VERSION ""

NS_ :

BS_:

BU_: FCM

BO_ 969 RRCR_3: 24 Vector__XXX
 SG_ RRCR_3_Ri2ObjBoxLen : 7|9@0+ (0.1,0) [0|50] "m"  FCM
 SG_ RRCR_3_Ri2ObjBoxWidth : 14|9@0+ (0.1,0) [0|50] "m"  FCM
 SG_ RRCR_3_Ri2HdTo : 21|12@0+ (0.1,-180) [-180|180] "deg"  FCM
 SG_ RRCR_3_Ri2ObjID : 25|8@0+ (1,0) [0|255] ""  FCM
 SG_ RRCR_3_Ri2ObjCoordY : 33|13@0+ (0.05,-200) [-200|200] "m"  FCM
 SG_ RRCR_3_Ri2ObjCoordX : 52|13@0+ (0.05,-200) [-200|200] "m"  FCM
 SG_ RRCR_3_Ri2ObjXDirAV : 71|8@0+ (0.1,-12.8) [-12.8|12.7] "m/s2"  FCM
 SG_ RRCR_3_Ri2ObjYDirV : 79|14@0+ (0.02,-128) [-128|128] "m/s"  FCM
 SG_ RRCR_3_Ri2ObjXDirV : 81|14@0+ (0.02,-128) [-128|128] "m/s"  FCM
 SG_ RRCR_3_Ri2ObjMtnChartc : 99|2@0+ (1,0) [0|3] ""  FCM
 SG_ RRCR_3_Ri2ObjTyp : 97|2@0+ (1,0) [0|3] ""  FCM
 SG_ RRCR_3_Ri2ObjConf : 111|1@0+ (1,0) [0|1] ""  FCM
 SG_ RRCR_3_Ri2ObjNrOffocst : 110|5@0+ (1,0) [0|31] ""  FCM
 SG_ RRCR_3_Ri2ObjTrackSt : 105|2@0+ (1,0) [0|3] ""  FCM
 SG_ RRCR_3_Ri2ObjCoordXDstStdDe : 119|8@0+ (0.05,0) [0|12.7] ""  FCM
 SG_ RRCR_3_Ri2ObjCoordYDstStdDe : 127|8@0+ (0.05,0) [0|12.7] ""  FCM
 SG_ RRCR_3_Ri2ObjXDirVStdDe : 135|6@0+ (0.05,0) [0|2] ""  FCM
 SG_ RRCR_3_Ri2ObjYDirVStdDe : 129|6@0+ (0.05,0) [0|2] ""  FCM
 SG_ RRCR_3_MsgCntr : 179|4@0+ (1,0) [0|15] ""  FCM
 SG_ RRCR_3_CRC : 191|8@0+ (1,0) [0|255] ""  FCM

BO_ 976 RRCR_4: 24 Vector__XXX
 SG_ RRCR_4_Ri3ObjBoxLen : 7|9@0+ (0.1,0) [0|50] "m"  FCM
 SG_ RRCR_4_Ri3ObjBoxWidth : 14|9@0+ (0.1,0) [0|50] "m"  FCM
 SG_ RRCR_4_Ri3HdTo : 21|12@0+ (0.1,-180) [-180|180] "deg"  FCM
 SG_ RRCR_4_Ri3ObjID : 25|8@0+ (1,0) [0|255] ""  FCM
 SG_ RRCR_4_Ri3ObjCoordY : 33|13@0+ (0.05,-200) [-200|200] "m"  FCM
 SG_ RRCR_4_Ri3ObjCoordX : 52|13@0+ (0.05,-200) [-200|200] "m"  FCM
 SG_ RRCR_4_Ri3ObjXDirAV : 71|8@0+ (0.1,-12.8) [-12.8|12.7] "m/s2"  FCM
 SG_ RRCR_4_Ri3ObjYDirV : 79|14@0+ (0.02,-128) [-128|128] "m/s"  FCM
 SG_ RRCR_4_Ri3ObjXDirV : 81|14@0+ (0.02,-128) [-128|128] "m/s"  FCM
 SG_ RRCR_4_Ri3ObjMtnChartc : 99|2@0+ (1,0) [0|3] ""  FCM
 SG_ RRCR_4_Ri3ObjTyp : 97|2@0+ (1,0) [0|3] ""  FCM
 SG_ RRCR_4_Ri3ObjConf : 111|1@0+ (1,0) [0|1] ""  FCM
 SG_ RRCR_4_Ri3ObjNrOffocst : 110|5@0+ (1,0) [0|31] ""  FCM
 SG_ RRCR_4_Ri3ObjTrackSt : 105|2@0+ (1,0) [0|3] ""  FCM
 SG_ RRCR_4_Ri3ObjCoordXDstStdDe : 119|8@0+ (0.05,0) [0|12.7] ""  FCM
 SG_ RRCR_4_Ri3ObjCoordYDstStdDe : 127|8@0+ (0.05,0) [0|12.7] ""  FCM
 SG_ RRCR_4_Ri3ObjXDirVStdDe : 135|6@0+ (0.05,0) [0|2] ""  FCM
 SG_ RRCR_4_Ri3ObjYDirVStdDe : 129|6@0+ (0.05,0) [0|2] ""  FCM
 SG_ RRCR_4_MsgCntr : 179|4@0+ (1,0) [0|15] ""  FCM
 SG_ RRCR_4_CRC : 191|8@0+ (1,0) [0|255] ""  FCM

BO_ 984 RRCR_5: 24 Vector__XXX
 SG_ RRCR_5_Ri4ObjBoxLen : 7|9@0+ (0.1,0) [0|50] "m"  FCM
 SG_ RRCR_5_Ri4ObjBoxWidth : 14|9@0+ (0.1,0) [0|50] "m"  FCM
 SG_ RRCR_5_Ri4HdTo : 21|12@0+ (0.1,-180) [-180|180] "deg"  FCM
 SG_ RRCR_5_Ri4ObjID : 25|8@0+ (1,0) [0|255] ""  FCM
 SG_ RRCR_5_Ri4ObjCoordY : 33|13@0+ (0.05,-200) [-200|200] "m"  FCM
 SG_ RRCR_5_Ri4ObjCoordX : 52|13@0+ (0.05,-200) [-200|200] "m"  FCM
 SG_ RRCR_5_Ri4ObjXDirAV : 71|8@0+ (0.1,-12.8) [-12.8|12.7] "m/s2"  FCM
 SG_ RRCR_5_Ri4ObjYDirV : 79|14@0+ (0.02,-128) [-128|128] "m/s"  FCM
 SG_ RRCR_5_Ri4ObjXDirV : 81|14@0+ (0.02,-128) [-128|128] "m/s"  FCM
 SG_ RRCR_5_Ri4ObjMtnChartc : 99|2@0+ (1,0) [0|3] ""  FCM
 SG_ RRCR_5_Ri4ObjTyp : 97|2@0+ (1,0) [0|3] ""  FCM
 SG_ RRCR_5_Ri4ObjConf : 111|1@0+ (1,0) [0|1] ""  FCM
 SG_ RRCR_5_Ri4ObjNrOffocst : 110|5@0+ (1,0) [0|31] ""  FCM
 SG_ RRCR_5_Ri4ObjTrackSt : 105|2@0+ (1,0) [0|3] ""  FCM
 SG_ RRCR_5_Ri4ObjCoordXDstStdDe : 119|8@0+ (0.05,0) [0|12.7] ""  FCM
 SG_ RRCR_5_Ri4ObjCoordYDstStdDe : 127|8@0+ (0.05,0) [0|12.7] ""  FCM
 SG_ RRCR_5_Ri4ObjXDirVStdDe : 135|6@0+ (0.05,0) [0|2] ""  FCM
 SG_ RRCR_5_Ri4ObjYDirVStdDe : 129|6@0+ (0.05,0) [0|2] ""  FCM
 SG_ RRCR_5_MsgCntr : 179|4@0+ (1,0) [0|15] ""  FCM
 SG_ RRCR_5_CRC : 191|8@0+ (1,0) [0|255] ""  FCM

BO_ 986 RRCR_6: 24 Vector__XXX
 SG_ RRCR_6_Ri5ObjBoxLen : 7|9@0+ (0.1,0) [0|50] "m"  FCM
 SG_ RRCR_6_Ri5ObjBoxWidth : 14|9@0+ (0.1,0) [0|50] "m"  FCM
 SG_ RRCR_6_Ri5HdTo : 21|12@0+ (0.1,-180) [-180|180] "deg"  FCM
 SG_ RRCR_6_Ri5ObjID : 25|8@0+ (1,0) [0|255] ""  FCM
 SG_ RRCR_6_Ri5ObjCoordY : 33|13@0+ (0.05,-200) [-200|200] "m"  FCM
 SG_ RRCR_6_Ri5ObjCoordX : 52|13@0+ (0.05,-200) [-200|200] "m"  FCM
 SG_ RRCR_6_Ri5ObjXDirAV : 71|8@0+ (0.1,-12.8) [-12.8|12.7] "m/s2"  FCM
 SG_ RRCR_6_Ri5ObjYDirV : 79|14@0+ (0.02,-128) [-128|128] "m/s"  FCM
 SG_ RRCR_6_Ri5ObjXDirV : 81|14@0+ (0.02,-128) [-128|128] "m/s"  FCM
 SG_ RRCR_6_Ri5ObjMtnChartc : 99|2@0+ (1,0) [0|3] ""  FCM
 SG_ RRCR_6_Ri5ObjTyp : 97|2@0+ (1,0) [0|3] ""  FCM
 SG_ RRCR_6_Ri5ObjConf : 111|1@0+ (1,0) [0|1] ""  FCM
 SG_ RRCR_6_Ri5ObjNrOffocst : 110|5@0+ (1,0) [0|31] ""  FCM
 SG_ RRCR_6_Ri5ObjTrackSt : 105|2@0+ (1,0) [0|3] ""  FCM
 SG_ RRCR_6_Ri5ObjCoordXDstStdDe : 119|8@0+ (0.05,0) [0|12.7] ""  FCM
 SG_ RRCR_6_Ri5ObjCoordYDstStdDe : 127|8@0+ (0.05,0) [0|12.7] ""  FCM
 SG_ RRCR_6_Ri5ObjXDirVStdDe : 135|6@0+ (0.05,0) [0|2] ""  FCM
 SG_ RRCR_6_Ri5ObjYDirVStdDe : 129|6@0+ (0.05,0) [0|2] ""  FCM
 SG_ RRCR_6_MsgCntr : 179|4@0+ (1,0) [0|15] ""  FCM
 SG_ RRCR_6_CRC : 191|8@0+ (1,0) [0|255] ""  FCM

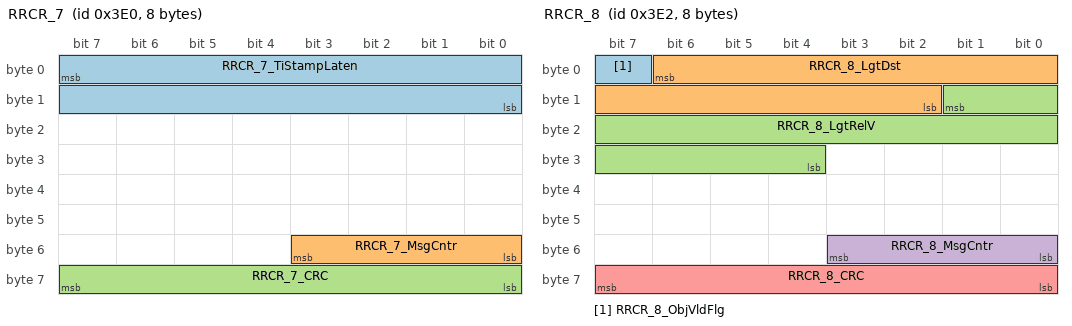
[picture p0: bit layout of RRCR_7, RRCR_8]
BO_ 992 RRCR_7: 8 Vector__XXX
 SG_ RRCR_7_TiStampLaten : 7|16@0+ (1,0) [0|65535] ""  FCM
 SG_ RRCR_7_MsgCntr : 51|4@0+ (1,0) [0|15] ""  FCM
 SG_ RRCR_7_CRC : 63|8@0+ (1,0) [0|255] ""  FCM

BO_ 994 RRCR_8: 8 Vector__XXX
 SG_ RRCR_8_ObjVldFlg : 7|1@0+ (1,0) [0|1] ""  FCM
 SG_ RRCR_8_LgtDst : 6|13@0+ (0.05,-200) [-200|200] "m"  FCM
 SG_ RRCR_8_LgtRelV : 9|14@0+ (0.02,-128) [-128|128] "m/s"  FCM
 SG_ RRCR_8_MsgCntr : 51|4@0+ (1,0) [0|15] ""  FCM
 SG_ RRCR_8_CRC : 63|8@0+ (1,0) [0|255] ""  FCM

BO_ 1785 XCP_FCM_RES: 8 FCM
 SG_ XCP_FCM_RES : 7|64@0+ (1,0) [0|1] ""  Vector__XXX

BO_ 1854 Diag_FCM_RES: 8 FCM
 SG_ Diag_FCM_RES : 7|64@0+ (1,0) [0|1] ""  Vector__XXX

BO_ 745 ABS_ESP_1: 8 Vector__XXX
 SG_ ABS_ESP_1_EBDFailSts : 1|1@0+ (1,0) [0|1] ""  FCM
 SG_ ABS_ESP_1_ABSFailSts : 5|1@0+ (1,0) [0|1] ""  FCM
 SG_ ABS_ESP_1_ABSActive : 6|1@0+ (1,0) [0|1] ""  FCM
 SG_ ABS_ESP_1_VDCFailSts : 11|1@0+ (1,0) [0|1] ""  FCM
 SG_ ABS_ESP_1_VDCActive : 12|1@0+ (1,0) [0|1] ""  FCM
 SG_ ABS_ESP_1_TCSFailSts : 13|1@0+ (1,0) [0|1] ""  FCM
 SG_ ABS_ESP_1_TCSActive : 14|1@0+ (1,0) [0|1] ""  FCM
 SG_ ABS_ESP_1_PressureMasterCylinder : 9|10@0+ (1,0) [0|1022] "Bar"  FCM
 SG_ ESP1_PressureMasCylindValidData : 29|1@0+ (1,0) [0|1] ""  FCM
 SG_ ESP1_VehicleSpeedVSOSigValidData : 30|1@0+ (1,0) [0|1] ""  FCM
 SG_ ABS_ESP_1_VehicleSpeedVSOSig : 28|13@0+ (0.0625,0) [0|511.875] "km/h"  FCM
 SG_ ABS_ESP_1_Checksum : 47|8@0+ (1,0) [0|255] ""  FCM
 SG_ ABS_ESP_1_HDCCtrlSts : 53|2@0+ (1,0) [0|3] ""  FCM
 SG_ ABS_ESP_1_HDCFailSts : 54|1@0+ (1,0) [0|1] ""  FCM
 SG_ ABS_ESP_1_MessageCounter : 59|4@0+ (1,0) [0|15] ""  FCM
 SG_ ABS_ESP_1_ESPSwitchStatus : 60|1@0+ (1,0) [0|1] ""  FCM
 SG_ SwitchOffCruiseControl : 63|1@0+ (1,0) [0|1] ""  FCM

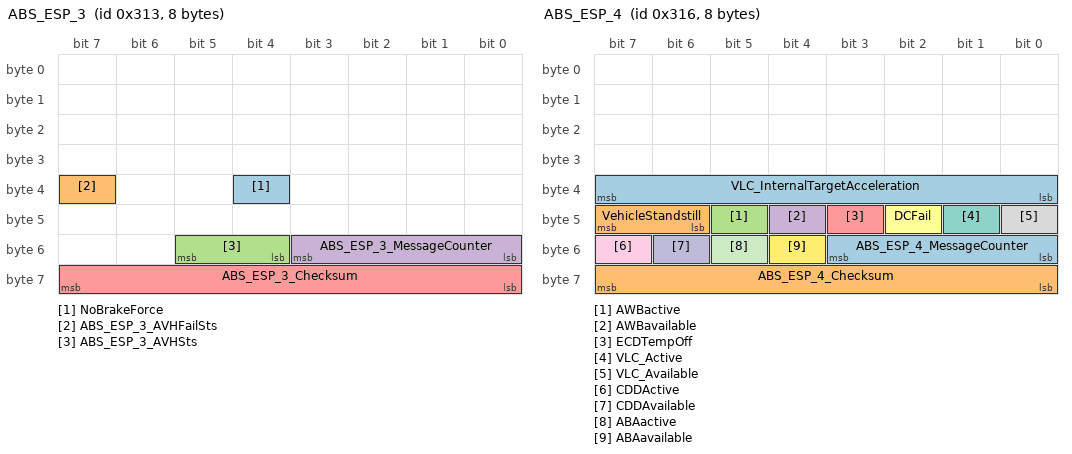
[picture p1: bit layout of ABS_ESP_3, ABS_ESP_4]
BO_ 787 ABS_ESP_3: 8 Vector__XXX
 SG_ NoBrakeForce : 36|1@0+ (1,0) [0|1] ""  FCM
 SG_ ABS_ESP_3_AVHFailSts : 39|1@0+ (1,0) [0|1] ""  FCM
 SG_ ABS_ESP_3_AVHSts : 53|2@0+ (1,0) [0|3] ""  FCM
 SG_ ABS_ESP_3_MessageCounter : 51|4@0+ (1,0) [0|15] ""  FCM
 SG_ ABS_ESP_3_Checksum : 63|8@0+ (1,0) [0|255] ""  FCM

BO_ 790 ABS_ESP_4: 8 Vector__XXX
 SG_ VLC_InternalTargetAcceleration : 39|8@0+ (0.05,-7) [-7|5.75] "m/s2"  FCM
 SG_ VehicleStandstill : 47|2@0+ (1,0) [0|3] ""  FCM
 SG_ AWBactive : 45|1@0+ (1,0) [0|1] ""  FCM
 SG_ AWBavailable : 44|1@0+ (1,0) [0|1] ""  FCM
 SG_ ECDTempOff : 43|1@0+ (1,0) [0|1] ""  FCM
 SG_ DCFail : 42|1@0+ (1,0) [0|1] ""  FCM
 SG_ VLC_Active : 41|1@0+ (1,0) [0|1] ""  FCM
 SG_ VLC_Available : 40|1@0+ (1,0) [0|1] ""  FCM
 SG_ CDDActive : 55|1@0+ (1,0) [0|1] ""  FCM
 SG_ CDDAvailable : 54|1@0+ (1,0) [0|1] ""  FCM
 SG_ ABAactive : 53|1@0+ (1,0) [0|1] ""  FCM
 SG_ ABAavailable : 52|1@0+ (1,0) [0|1] ""  FCM
 SG_ ABS_ESP_4_MessageCounter : 51|4@0+ (1,0) [0|15] ""  FCM
 SG_ ABS_ESP_4_Checksum : 63|8@0+ (1,0) [0|255] ""  FCM

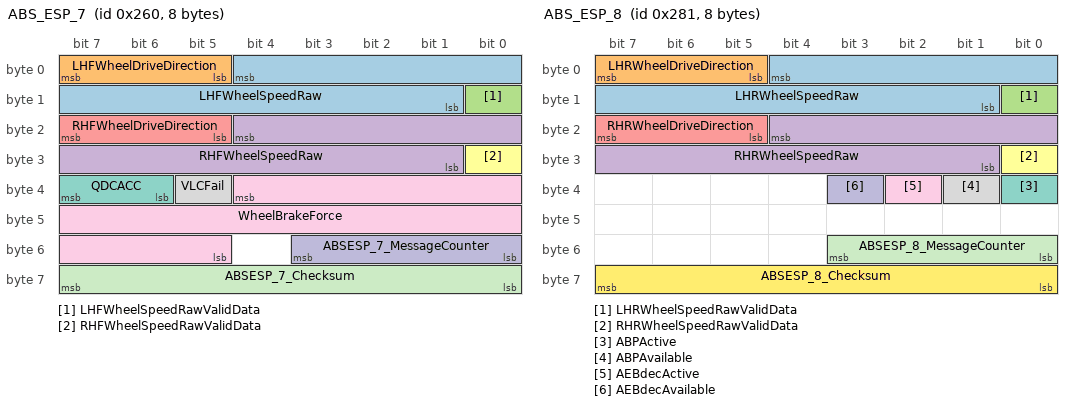
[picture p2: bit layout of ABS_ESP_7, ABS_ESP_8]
BO_ 608 ABS_ESP_7: 8 Vector__XXX
 SG_ LHFWheelSpeedRaw : 4|12@0+ (0.05,-30) [-30|80] "m/s"  FCM
 SG_ LHFWheelDriveDirection : 7|3@0+ (1,0) [0|7] ""  FCM
 SG_ LHFWheelSpeedRawValidData : 8|1@0+ (1,0) [0|1] ""  FCM
 SG_ RHFWheelSpeedRaw : 20|12@0+ (0.05,-30) [-30|80] "m/s"  FCM
 SG_ RHFWheelDriveDirection : 23|3@0+ (1,0) [0|7] ""  FCM
 SG_ RHFWheelSpeedRawValidData : 24|1@0+ (1,0) [0|1] ""  FCM
 SG_ QDCACC : 39|2@0+ (1,0) [0|3] ""  FCM
 SG_ VLCFail : 37|1@0+ (1,0) [0|1] ""  FCM
 SG_ WheelBrakeForce : 36|16@0+ (8,-250000) [-250000|250000] "N"  FCM
 SG_ ABSESP_7_MessageCounter : 51|4@0+ (1,0) [0|15] ""  FCM
 SG_ ABSESP_7_Checksum : 63|8@0+ (1,0) [0|255] ""  FCM

BO_ 641 ABS_ESP_8: 8 Vector__XXX
 SG_ LHRWheelSpeedRaw : 4|12@0+ (0.05,-30) [-30|80] "m/s"  FCM
 SG_ LHRWheelDriveDirection : 7|3@0+ (1,0) [0|7] ""  FCM
 SG_ LHRWheelSpeedRawValidData : 8|1@0+ (1,0) [0|1] ""  FCM
 SG_ RHRWheelSpeedRaw : 20|12@0+ (0.05,-30) [-30|80] "m/s"  FCM
 SG_ RHRWheelDriveDirection : 23|3@0+ (1,0) [0|7] ""  FCM
 SG_ RHRWheelSpeedRawValidData : 24|1@0+ (1,0) [0|1] ""  FCM
 SG_ ABPActive : 32|1@0+ (1,0) [0|1] ""  FCM
 SG_ ABPAvailable : 33|1@0+ (1,0) [0|1] ""  FCM
 SG_ AEBdecActive : 34|1@0+ (1,0) [0|1] ""  FCM
 SG_ AEBdecAvailable : 35|1@0+ (1,0) [0|1] ""  FCM
 SG_ ABSESP_8_MessageCounter : 51|4@0+ (1,0) [0|15] ""  FCM
 SG_ ABSESP_8_Checksum : 63|8@0+ (1,0) [0|255] ""  FCM

BO_ 1282 ABS_ESP_G: 7 Vector__XXX
 SG_ CDPActive : 13|1@0+ (1,0) [0|1] ""  FCM

BO_ 913 BCM_1: 8 Vector__XXX
 SG_ RHTurnlightSts : 0|1@0+ (1,0) [0|1] ""  FCM
 SG_ LHTurnlightSts : 1|1@0+ (1,0) [0|1] ""  FCM
 SG_ HighBeamSts : 2|1@0+ (1,0) [0|1] ""  FCM
 SG_ LowBeamSts : 3|1@0+ (1,0) [0|1] ""  FCM
 SG_ KeySts : 6|2@0+ (1,0) [0|3] ""  FCM
 SG_ BCM_1_Checksum : 15|8@0+ (1,0) [0|255] ""  FCM
 SG_ DirectionIndRight : 16|1@0+ (1,0) [0|1] ""  FCM
 SG_ DirectionIndLeft : 17|1@0+ (1,0) [0|1] ""  FCM
 SG_ HazardLightSW : 18|1@0+ (1,0) [0|1] ""  FCM
 SG_ AutoLightSW : 19|1@0+ (1,0) [0|1] ""  FCM
 SG_ FGHeat_Request_CommandFeedback : 22|1@0+ (1,0) [0|1] ""  FCM
 SG_ DriverDoorLockSts : 23|1@0+ (1,0) [0|1] ""  FCM
 SG_ DriverDoorSts : 24|1@0+ (1,0) [0|1] ""  FCM
 SG_ PsngrDoorSts : 25|1@0+ (1,0) [0|1] ""  FCM
 SG_ HoodSts : 26|1@0+ (1,0) [0|1] ""  FCM
 SG_ RHRDoorSts : 28|1@0+ (1,0) [0|1] ""  FCM
 SG_ LHRdoorSts : 29|1@0+ (1,0) [0|1] ""  FCM
 SG_ TrunkSts : 30|1@0+ (1,0) [0|1] ""  FCM
 SG_ DriverDoorStsQbit : 31|1@0+ (1,0) [0|1] ""  FCM
 SG_ HMASW : 32|1@0+ (1,0) [0|1] ""  FCM
 SG_ RearFogLightSts : 34|1@0+ (1,0) [0|1] ""  FCM
 SG_ ReverseGearSts : 35|1@0+ (1,0) [0|1] ""  FCM
 SG_ FrontFogLightSts : 37|1@0+ (1,0) [0|1] ""  FCM
 SG_ HighBeamSWSts : 38|1@0+ (1,0) [0|1] ""  FCM
 SG_ FlashSWSts : 39|1@0+ (1,0) [0|1] ""  FCM
 SG_ LHTurnSW : 44|1@0+ (1,0) [0|1] ""  FCM
 SG_ RHTurnSW : 45|1@0+ (1,0) [0|1] ""  FCM
 SG_ WiperSts : 47|2@0+ (1,0) [0|3] ""  FCM
 SG_ RainDetected : 53|1@0+ (1,0) [0|1] ""  FCM
 SG_ AutoHighSpeedRequest : 52|1@0+ (1,0) [0|1] ""  FCM
 SG_ BCM_1_MessageCounter : 51|4@0+ (1,0) [0|15] ""  FCM

BO_ 1077 BCM_9: 8 Vector__XXX
 SG_ TrailerConnectSts : 48|1@0+ (1,0) [0|1] ""  FCM

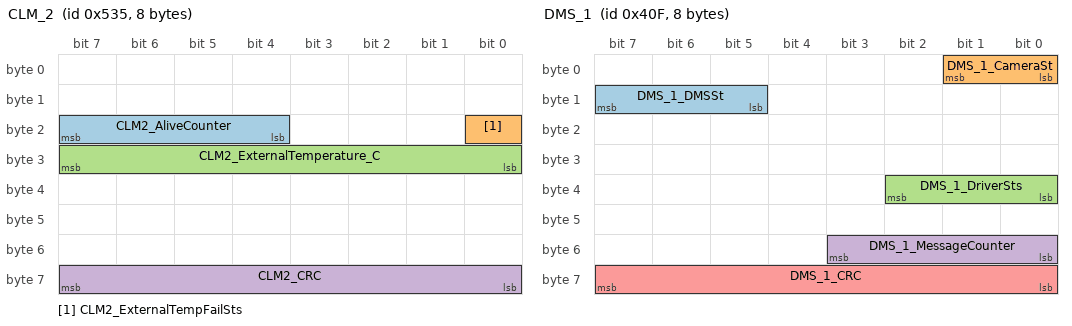
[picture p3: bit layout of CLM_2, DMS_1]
BO_ 1333 CLM_2: 8 Vector__XXX
 SG_ CLM2_AliveCounter : 23|4@0+ (1,0) [0|15] ""  FCM
 SG_ CLM2_ExternalTempFailSts : 16|1@0+ (1,0) [0|1] ""  FCM
 SG_ CLM2_ExternalTemperature_C : 31|8@0+ (0.5,-55) [-55|70] "°C"  FCM
 SG_ CLM2_CRC : 63|8@0+ (1,0) [0|255] ""  FCM

BO_ 1039 DMS_1: 8 Vector__XXX
 SG_ DMS_1_DMSSt : 15|3@0+ (1,0) [0|7] ""  FCM
 SG_ DMS_1_CameraSt : 1|2@0+ (1,0) [0|3] ""  FCM
 SG_ DMS_1_DriverSts : 34|3@0+ (1,0) [0|5] ""  FCM
 SG_ DMS_1_MessageCounter : 51|4@0+ (1,0) [0|15] ""  FCM
 SG_ DMS_1_CRC : 63|8@0+ (1,0) [0|255] ""  FCM

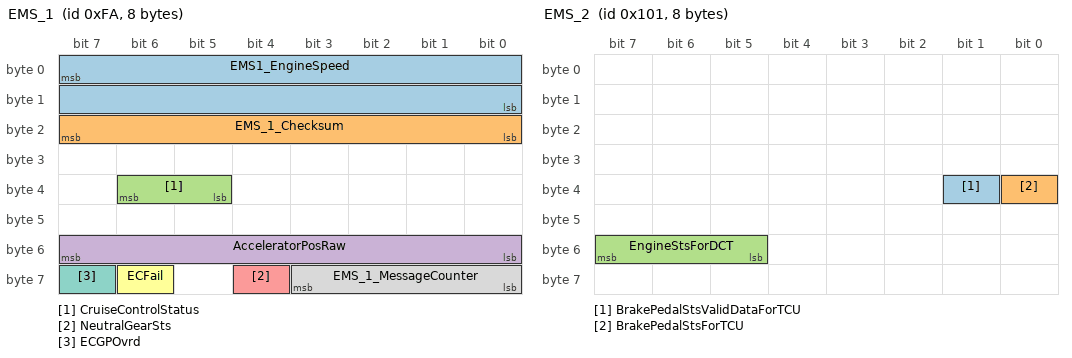
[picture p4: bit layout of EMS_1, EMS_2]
BO_ 250 EMS_1: 8 Vector__XXX
 SG_ EMS1_EngineSpeed : 7|16@0+ (0.25,0) [0|16383] "rpm"  FCM
 SG_ EMS_1_Checksum : 23|8@0+ (1,0) [0|255] ""  FCM
 SG_ CruiseControlStatus : 38|2@0+ (1,0) [0|3] ""  FCM
 SG_ AcceleratorPosRaw : 55|8@0+ (0.392,0) [0|99.568] "%"  FCM
 SG_ NeutralGearSts : 60|1@0+ (1,0) [0|1] ""  FCM
 SG_ ECFail : 62|1@0+ (1,0) [0|1] ""  FCM
 SG_ ECGPOvrd : 63|1@0+ (1,0) [0|1] ""  FCM
 SG_ EMS_1_MessageCounter : 59|4@0+ (1,0) [0|15] ""  FCM

BO_ 257 EMS_2: 8 Vector__XXX
 SG_ BrakePedalStsValidDataForTCU : 33|1@0+ (1,0) [0|1] ""  FCM
 SG_ BrakePedalStsForTCU : 32|1@0+ (1,0) [0|1] ""  FCM
 SG_ EngineStsForDCT : 55|3@0+ (1,0) [0|7] ""  FCM

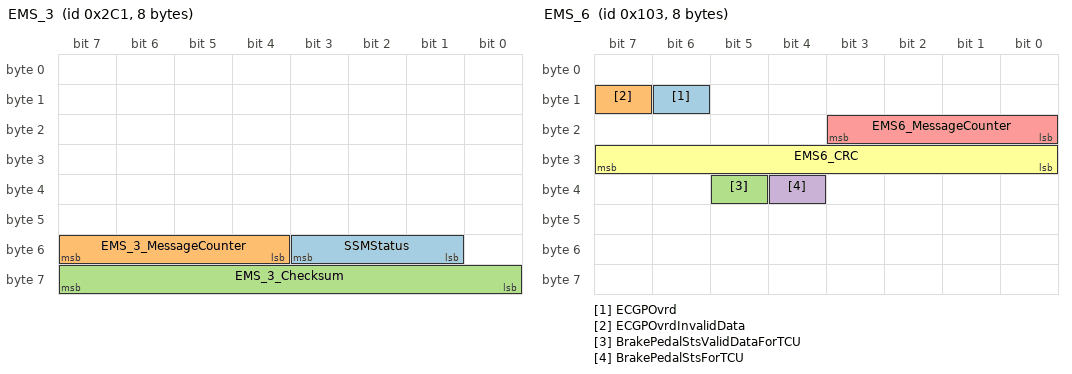
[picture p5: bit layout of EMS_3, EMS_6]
BO_ 705 EMS_3: 8 Vector__XXX
 SG_ SSMStatus : 51|3@0+ (1,0) [0|7] ""  FCM
 SG_ EMS_3_MessageCounter : 55|4@0+ (1,0) [0|15] ""  FCM
 SG_ EMS_3_Checksum : 63|8@0+ (1,0) [0|255] ""  FCM

BO_ 259 EMS_6: 8 Vector__XXX
 SG_ ECGPOvrd : 14|1@0+ (1,0) [0|1] ""  FCM
 SG_ ECGPOvrdInvalidData : 15|1@0+ (1,0) [0|1] ""  FCM
 SG_ BrakePedalStsValidDataForTCU : 37|1@0+ (1,0) [0|1] ""  FCM
 SG_ BrakePedalStsForTCU : 36|1@0+ (1,0) [0|1] ""  FCM
 SG_ EMS6_MessageCounter : 19|4@0+ (1,0) [0|15] ""  FCM
 SG_ EMS6_CRC : 31|8@0+ (1,0) [0|255] ""  FCM

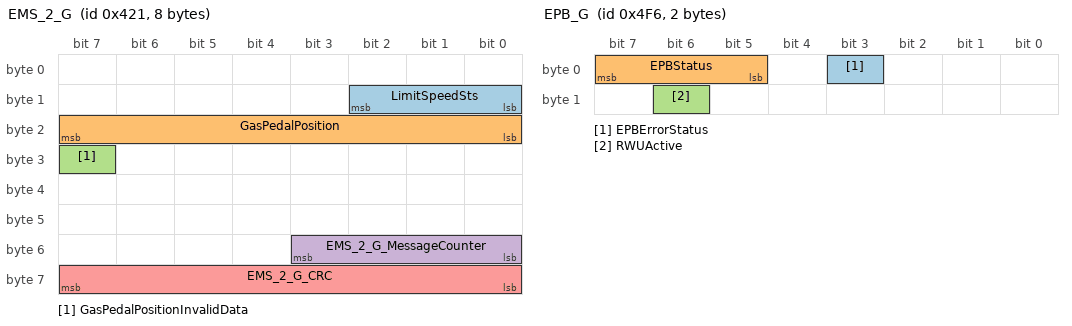
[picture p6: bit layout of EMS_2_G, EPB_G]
BO_ 1057 EMS_2_G: 8 Vector__XXX
 SG_ LimitSpeedSts : 10|3@0+ (1,0) [0|7] ""  FCM
 SG_ GasPedalPosition : 23|8@0+ (0.392,0) [0|99.568] "%"  FCM
 SG_ GasPedalPositionInvalidData : 31|1@0+ (1,0) [0|1] ""  FCM
 SG_ EMS_2_G_MessageCounter : 51|4@0+ (1,0) [0|15] ""  FCM
 SG_ EMS_2_G_CRC : 63|8@0+ (1,0) [0|255] ""  FCM

BO_ 1270 EPB_G: 2 Vector__XXX
 SG_ EPBErrorStatus : 3|1@0+ (1,0) [0|1] ""  FCM
 SG_ EPBStatus : 7|3@0+ (1,0) [0|7] ""  FCM
 SG_ RWUActive : 14|1@0+ (1,0) [0|1] ""  FCM

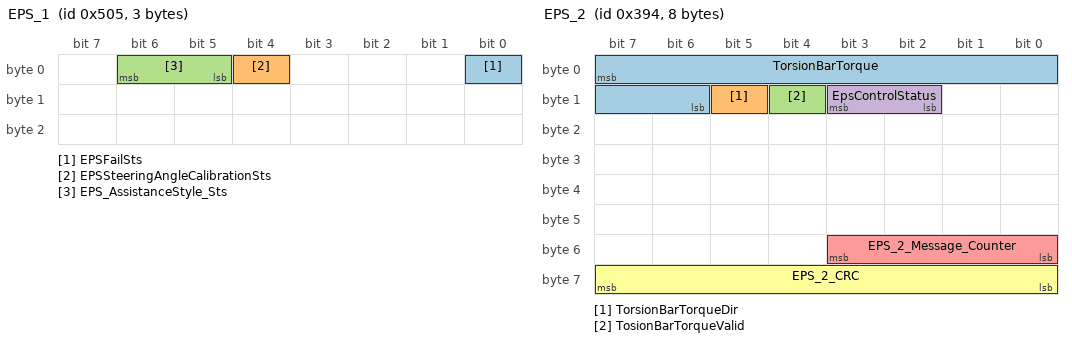
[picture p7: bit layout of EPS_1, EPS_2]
BO_ 1285 EPS_1: 3 Vector__XXX
 SG_ EPSFailSts : 0|1@0+ (1,0) [0|1] ""  FCM
 SG_ EPSSteeringAngleCalibrationSts : 4|1@0+ (1,0) [0|1] ""  FCM
 SG_ EPS_AssistanceStyle_Sts : 6|2@0+ (1,0) [0|3] ""  FCM

BO_ 916 EPS_2: 8 Vector__XXX
 SG_ TorsionBarTorque : 7|10@0+ (0.01,0) [0|10.23] "Nm"  FCM
 SG_ TorsionBarTorqueDir : 13|1@0+ (1,0) [0|1] ""  FCM
 SG_ TosionBarTorqueValid : 12|1@0+ (1,0) [0|1] ""  FCM
 SG_ EpsControlStatus : 11|2@0+ (1,0) [0|3] ""  FCM
 SG_ EPS_2_Message_Counter : 51|4@0+ (1,0) [0|15] ""  FCM
 SG_ EPS_2_CRC : 63|8@0+ (1,0) [0|255] ""  FCM

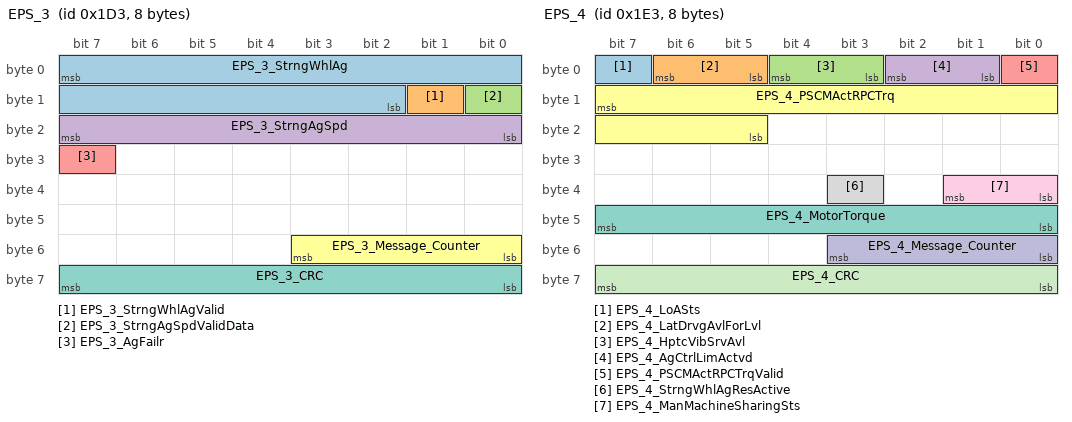
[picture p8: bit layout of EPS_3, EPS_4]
BO_ 467 EPS_3: 8 Vector__XXX
 SG_ EPS_3_StrngWhlAg : 7|14@0+ (0.1,-780) [-780|780] "deg"  FCM
 SG_ EPS_3_StrngWhlAgValid : 9|1@0+ (1,0) [0|1] ""  FCM
 SG_ EPS_3_StrngAgSpdValidData : 8|1@0+ (1,0) [0|1] ""  FCM
 SG_ EPS_3_StrngAgSpd : 23|8@0+ (4,0) [0|1016] "deg/Sec"  FCM
 SG_ EPS_3_AgFailr : 31|1@0+ (1,0) [0|1] ""  FCM
 SG_ EPS_3_Message_Counter : 51|4@0+ (1,0) [0|15] ""  FCM
 SG_ EPS_3_CRC : 63|8@0+ (1,0) [0|255] ""  FCM

BO_ 483 EPS_4: 8 Vector__XXX
 SG_ EPS_4_LoASts : 7|1@0+ (1,0) [0|1] ""  FCM
 SG_ EPS_4_LatDrvgAvlForLvl : 6|2@0+ (1,0) [0|3] ""  FCM
 SG_ EPS_4_HptcVibSrvAvl : 4|2@0+ (1,0) [0|3] ""  FCM
 SG_ EPS_4_AgCtrlLimActvd : 2|2@0+ (1,0) [0|3] ""  FCM
 SG_ EPS_4_PSCMActRPCTrqValid : 0|1@0+ (1,0) [0|1] ""  FCM
 SG_ EPS_4_PSCMActRPCTrq : 15|11@0+ (0.02,-20.48) [-20.48|20.44] "Nm"  FCM
 SG_ EPS_4_MotorTorque : 47|8@0+ (0.1,-10) [-10|10] "NM"  FCM
 SG_ EPS_4_StrngWhlAgResActive : 35|1@0+ (1,0) [0|1] ""  FCM
 SG_ EPS_4_ManMachineSharingSts : 33|2@0+ (1,0) [0|3] ""  FCM
 SG_ EPS_4_Message_Counter : 51|4@0+ (1,0) [0|15] ""  FCM
 SG_ EPS_4_CRC : 63|8@0+ (1,0) [0|255] ""  FCM

BO_ 406 EPB_State_R: 24 Vector__XXX
 SG_ EPB_State_R_CRC1 : 7|8@0+ (1,0) [0|255] ""  FCM
 SG_ EPB_State_R_RollgCntr1 : 11|4@0+ (1,0) [0|15] ""  FCM
 SG_ EPB_FltLvl : 37|2@0+ (1,0) [0|3] ""  FCM
 SG_ EPBStatus : 61|3@0+ (1,0) [0|7] ""  FCM

BO_ 263 HCU_6: 32 Vector__XXX
 SG_ HCU_6_MaxTorqueWheel : 87|16@0+ (1,-32767) [-32767|32767] "NM"  FCM
 SG_ HCU_6_MinTorqueWheel : 103|16@0+ (1,-32767) [-32767|32767] "NM"  FCM
 SG_ HCU_6_ECGPOvrd : 119|1@0+ (1,0) [0|1] ""  FCM
 SG_ HCU_6_ECGPOvrdInvalidData : 118|1@0+ (1,0) [0|1] ""  FCM
 SG_ HCU_BrakePedalStsValidDataForTCU : 148|1@0+ (1,0) [0|1] ""  FCM
 SG_ HCU_6_BrakePedalStsForTCU : 149|1@0+ (1,0) [0|1] ""  FCM
 SG_ HCU_6_MessageCounter : 243|4@0+ (1,0) [0|15] "/"  FCM
 SG_ HCU_6_CRC : 255|8@0+ (1,0) [0|255] "/"  FCM

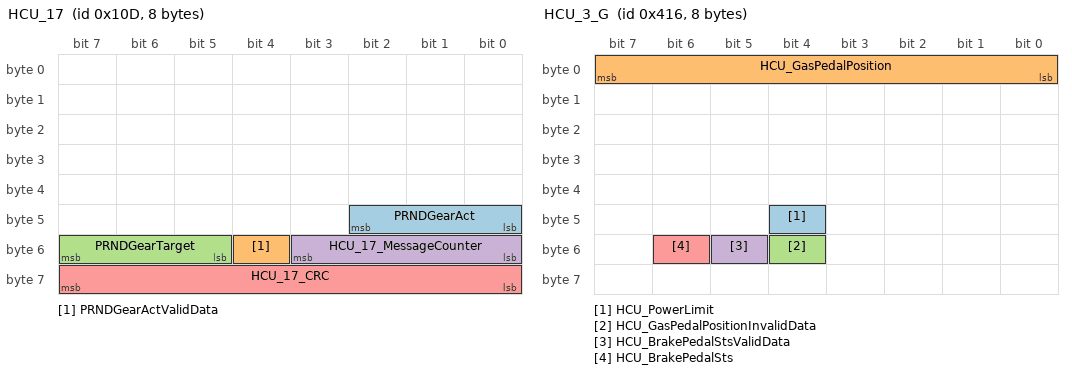
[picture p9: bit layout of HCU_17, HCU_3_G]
BO_ 269 HCU_17: 8 Vector__XXX
 SG_ PRNDGearAct : 42|3@0+ (1,0) [0|7] ""  FCM
 SG_ PRNDGearActValidData : 52|1@0+ (1,0) [0|1] ""  FCM
 SG_ PRNDGearTarget : 55|3@0+ (1,0) [0|7] ""  FCM
 SG_ HCU_17_MessageCounter : 51|4@0+ (1,0) [0|15] ""  FCM
 SG_ HCU_17_CRC : 63|8@0+ (1,0) [0|255] ""  FCM

BO_ 1034 HCU_1_G: 8 Vector__XXX
 SG_ HCU_PTReady : 49|1@0+ (1,0) [0|1] ""  FCM
 SG_ HCU_PowertrainFault : 8|1@0+ (1,0) [0|1] ""  FCM

BO_ 1046 HCU_3_G: 8 Vector__XXX
 SG_ HCU_PowerLimit : 44|1@0+ (1,0) [0|1] ""  FCM
 SG_ HCU_GasPedalPosition : 7|8@0+ (0.392,0) [0|99.96] "%"  FCM
 SG_ HCU_GasPedalPositionInvalidData : 52|1@0+ (1,0) [0|1] ""  FCM
 SG_ HCU_BrakePedalStsValidData : 53|1@0+ (1,0) [0|1] ""  FCM
 SG_ HCU_BrakePedalSts : 54|1@0+ (1,0) [0|1] ""  FCM

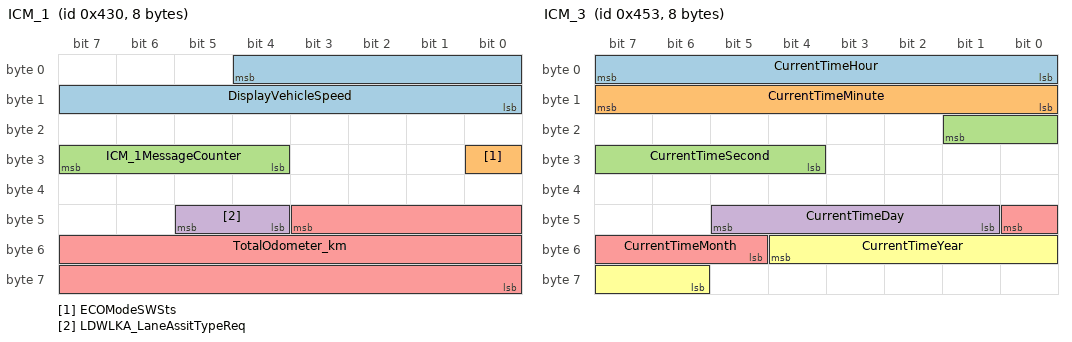
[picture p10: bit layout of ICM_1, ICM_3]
BO_ 1072 ICM_1: 8 Vector__XXX
 SG_ DisplayVehicleSpeed : 4|13@0+ (0.0625,0) [0|511.875] "km/h"  FCM
 SG_ ECOModeSWSts : 24|1@0+ (1,0) [0|1] ""  FCM
 SG_ ICM_1MessageCounter : 31|4@0+ (1,0) [0|15] ""  FCM
 SG_ LDWLKA_LaneAssitTypeReq : 45|2@0+ (1,0) [0|3] ""  FCM
 SG_ TotalOdometer_km : 43|20@0+ (1,0) [0|999999] "km"  FCM

BO_ 1106 ICM_2: 4 Vector__XXX
 SG_ DISFail : 18|1@0+ (1,0) [0|1] ""  FCM
 SG_ QDashACCFail : 17|2@0+ (1,0) [0|3] ""  FCM

BO_ 1107 ICM_3: 8 Vector__XXX
 SG_ CurrentTimeHour : 7|8@0+ (1,0) [0|23] ""  FCM
 SG_ CurrentTimeMinute : 15|8@0+ (1,0) [0|59] ""  FCM
 SG_ CurrentTimeSecond : 17|6@0+ (1,0) [0|59] ""  FCM
 SG_ CurrentTimeDay : 45|5@0+ (1,0) [1|31] ""  FCM
 SG_ CurrentTimeMonth : 40|4@0+ (1,0) [1|12] ""  FCM
 SG_ CurrentTimeYear : 52|7@0+ (1,2000) [2000|2127] ""  FCM

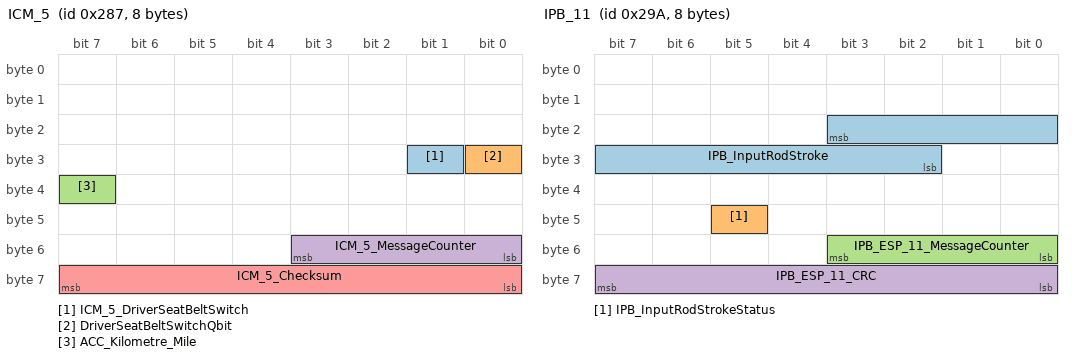
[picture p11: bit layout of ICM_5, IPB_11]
BO_ 647 ICM_5: 8 Vector__XXX
 SG_ ICM_5_DriverSeatBeltSwitch : 25|1@0+ (1,0) [0|1] ""  FCM
 SG_ DriverSeatBeltSwitchQbit : 24|1@0+ (1,0) [0|1] ""  FCM
 SG_ ACC_Kilometre_Mile : 39|1@0+ (1,0) [0|1] ""  FCM
 SG_ ICM_5_MessageCounter : 51|4@0+ (1,0) [0|15] ""  FCM
 SG_ ICM_5_Checksum : 63|8@0+ (1,0) [0|255] ""  FCM

BO_ 666 IPB_11: 8 Vector__XXX
 SG_ IPB_InputRodStroke : 19|10@0+ (0.05,-5) [-5|46.15] "mm"  FCM
 SG_ IPB_InputRodStrokeStatus : 45|1@0+ (1,0) [0|1] ""  FCM
 SG_ IPB_ESP_11_MessageCounter : 51|4@0+ (1,0) [0|15] ""  FCM
 SG_ IPB_ESP_11_CRC : 63|8@0+ (1,0) [0|255] ""  FCM

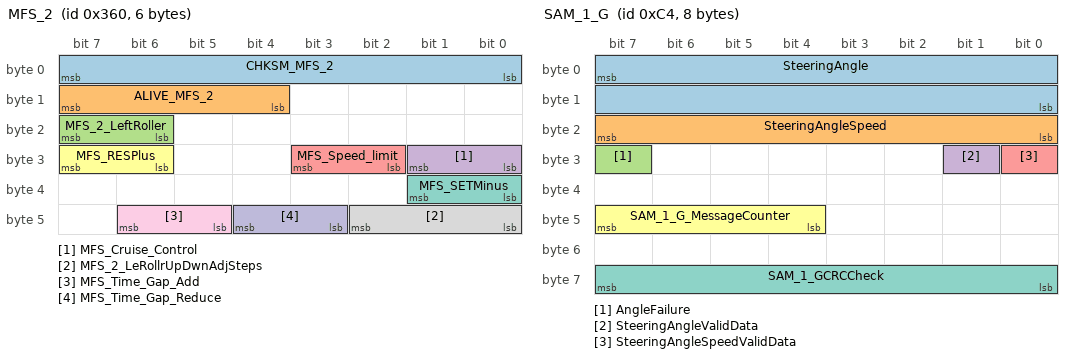
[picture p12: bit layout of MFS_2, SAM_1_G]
BO_ 864 MFS_2: 6 Vector__XXX
 SG_ CHKSM_MFS_2 : 7|8@0+ (1,0) [0|255] ""  FCM
 SG_ ALIVE_MFS_2 : 15|4@0+ (1,0) [0|15] ""  FCM
 SG_ MFS_2_LeftRoller : 23|2@0+ (1,0) [0|3] ""  FCM
 SG_ MFS_Cruise_Control : 25|2@0+ (1,0) [0|3] ""  FCM
 SG_ MFS_Speed_limit : 27|2@0+ (1,0) [0|3] ""  FCM
 SG_ MFS_RESPlus : 31|2@0+ (1,0) [0|3] ""  FCM
 SG_ MFS_SETMinus : 33|2@0+ (1,0) [0|3] ""  FCM
 SG_ MFS_2_LeRollrUpDwnAdjSteps : 42|3@0+ (1,0) [0|7] ""  FCM
 SG_ MFS_Time_Gap_Add : 46|2@0+ (1,0) [0|3] ""  FCM
 SG_ MFS_Time_Gap_Reduce : 44|2@0+ (1,0) [0|3] ""  FCM

BO_ 196 SAM_1_G: 8 Vector__XXX
 SG_ SteeringAngle : 7|16@0+ (0.0625,-2048) [-2048|2047.875] "deg"  FCM
 SG_ SteeringAngleSpeed : 23|8@0+ (4,0) [0|1016] "deg/Sec"  FCM
 SG_ AngleFailure : 31|1@0+ (1,0) [0|1] ""  FCM
 SG_ SteeringAngleValidData : 25|1@0+ (1,0) [0|1] ""  FCM
 SG_ SteeringAngleSpeedValidData : 24|1@0+ (1,0) [0|1] ""  FCM
 SG_ SAM_1_G_MessageCounter : 47|4@0+ (1,0) [0|15] ""  FCM
 SG_ SAM_1_GCRCCheck : 63|8@0+ (1,0) [0|255] ""  FCM

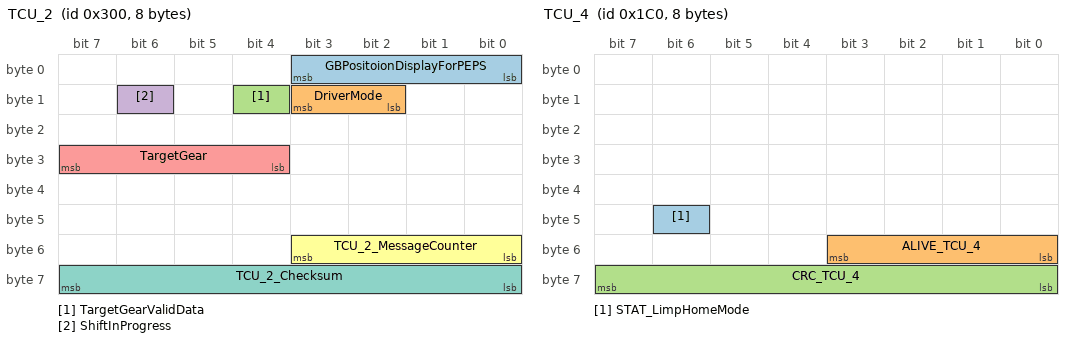
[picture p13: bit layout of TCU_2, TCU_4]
BO_ 768 TCU_2: 8 Vector__XXX
 SG_ GBPositoionDisplayForPEPS : 3|4@0+ (1,0) [0|15] ""  FCM
 SG_ DriverMode : 11|2@0+ (1,0) [0|3] ""  FCM
 SG_ TargetGearValidData : 12|1@0+ (1,0) [0|1] ""  FCM
 SG_ ShiftInProgress : 14|1@0+ (1,0) [0|1] ""  FCM
 SG_ TargetGear : 31|4@0+ (1,0) [0|15] ""  FCM
 SG_ TCU_2_MessageCounter : 51|4@0+ (1,0) [0|15] ""  FCM
 SG_ TCU_2_Checksum : 63|8@0+ (1,0) [0|255] ""  FCM

BO_ 448 TCU_4: 8 Vector__XXX
 SG_ STAT_LimpHomeMode : 46|1@0+ (1,0) [0|1] ""  FCM
 SG_ ALIVE_TCU_4 : 51|4@0+ (1,0) [0|15] ""  FCM
 SG_ CRC_TCU_4 : 63|8@0+ (1,0) [0|255] ""  FCM

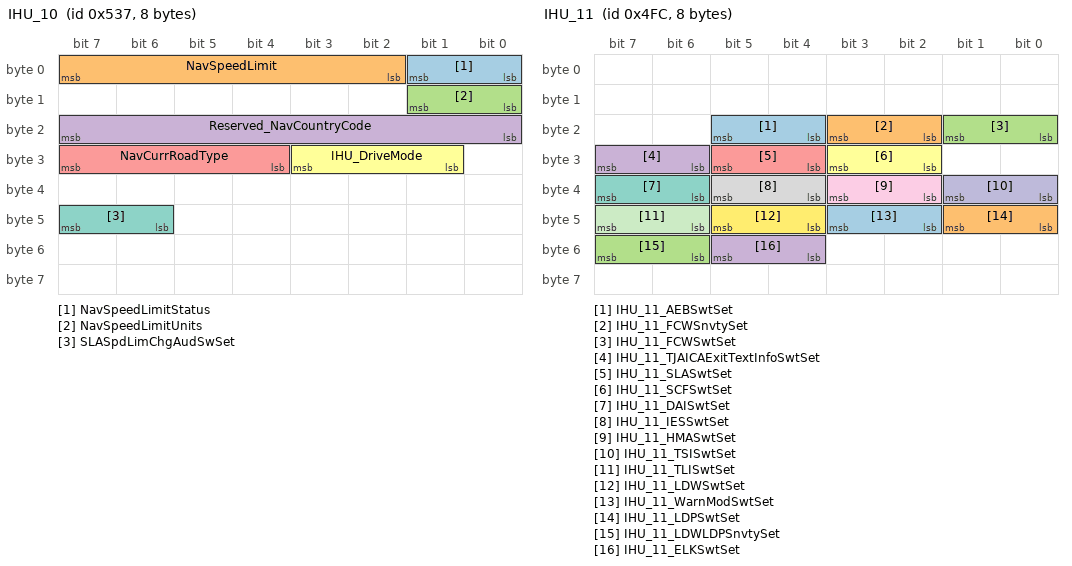
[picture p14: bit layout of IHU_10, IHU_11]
BO_ 1335 IHU_10: 8 Vector__XXX
 SG_ NavSpeedLimitStatus : 1|2@0+ (1,0) [0|3] ""  FCM
 SG_ NavSpeedLimit : 7|6@0+ (1,0) [0|59] ""  FCM
 SG_ NavSpeedLimitUnits : 9|2@0+ (1,0) [0|3] ""  FCM
 SG_ Reserved_NavCountryCode : 23|8@0+ (1,0) [0|255] ""  FCM
 SG_ NavCurrRoadType : 31|4@0+ (1,0) [0|15] ""  FCM
 SG_ IHU_DriveMode : 27|3@0+ (1,0) [0|7] ""  FCM
 SG_ SLASpdLimChgAudSwSet : 47|2@0+ (1,0) [0|3] ""  FCM

BO_ 1276 IHU_11: 8 Vector__XXX
 SG_ IHU_11_AEBSwtSet : 21|2@0+ (1,0) [0|3] ""  FCM
 SG_ IHU_11_FCWSnvtySet : 19|2@0+ (1,0) [0|3] ""  FCM
 SG_ IHU_11_FCWSwtSet : 17|2@0+ (1,0) [0|3] ""  FCM
 SG_ IHU_11_TJAICAExitTextInfoSwtSet : 31|2@0+ (1,0) [0|3] ""  FCM
 SG_ IHU_11_SLASwtSet : 29|2@0+ (1,0) [0|3] ""  FCM
 SG_ IHU_11_SCFSwtSet : 27|2@0+ (1,0) [0|3] ""  FCM
 SG_ IHU_11_DAISwtSet : 39|2@0+ (1,0) [0|3] ""  FCM
 SG_ IHU_11_IESSwtSet : 37|2@0+ (1,0) [0|3] ""  FCM
 SG_ IHU_11_HMASwtSet : 35|2@0+ (1,0) [0|3] ""  FCM
 SG_ IHU_11_TSISwtSet : 33|2@0+ (1,0) [0|3] ""  FCM
 SG_ IHU_11_TLISwtSet : 47|2@0+ (1,0) [0|3] ""  FCM
 SG_ IHU_11_LDWSwtSet : 45|2@0+ (1,0) [0|3] ""  FCM
 SG_ IHU_11_WarnModSwtSet : 43|2@0+ (1,0) [0|3] ""  FCM
 SG_ IHU_11_LDPSwtSet : 41|2@0+ (1,0) [0|3] ""  FCM
 SG_ IHU_11_LDWLDPSnvtySet : 55|2@0+ (1,0) [0|3] ""  FCM
 SG_ IHU_11_ELKSwtSet : 53|2@0+ (1,0) [0|3] ""  FCM

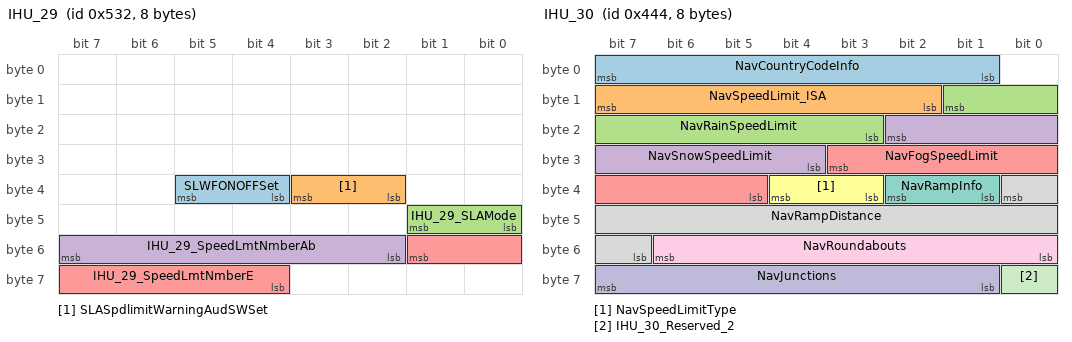
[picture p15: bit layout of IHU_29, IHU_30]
BO_ 1330 IHU_29: 8 Vector__XXX
 SG_ SLWFONOFFSet : 37|2@0+ (1,0) [0|3] ""  FCM
 SG_ SLASpdlimitWarningAudSWSet : 35|2@0+ (1,0) [0|3] ""  FCM
 SG_ IHU_29_SLAMode : 41|2@0+ (1,0) [0|3] ""  FCM
 SG_ IHU_29_SpeedLmtNmberAb : 55|6@0+ (1,0) [0|63] ""  FCM
 SG_ IHU_29_SpeedLmtNmberE : 49|6@0+ (1,0) [0|63] ""  FCM

BO_ 1092 IHU_30: 8 Vector__XXX
 SG_ NavCountryCodeInfo : 7|7@0+ (1,0) [0|127] ""  FCM
 SG_ NavSpeedLimit_ISA : 15|6@0+ (1,0) [0|34] ""  FCM
 SG_ NavRainSpeedLimit : 9|7@0+ (1,0) [0|120] ""  FCM
 SG_ NavSnowSpeedLimit : 18|7@0+ (1,0) [0|120] ""  FCM
 SG_ NavFogSpeedLimit : 27|7@0+ (1,0) [0|120] ""  FCM
 SG_ NavSpeedLimitType : 36|2@0+ (1,0) [0|3] ""  FCM
 SG_ NavRampInfo : 34|2@0+ (1,0) [0|1] ""  FCM
 SG_ NavRampDistance : 32|10@0+ (1,0) [0|1000] "m"  FCM
 SG_ NavRoundabouts : 54|7@0+ (1,0) [0|100] ""  FCM
 SG_ NavJunctions : 63|7@0+ (1,0) [0|100] ""  FCM
 SG_ IHU_30_Reserved_2 : 56|1@0+ (1,0) [0|1] ""  FCM

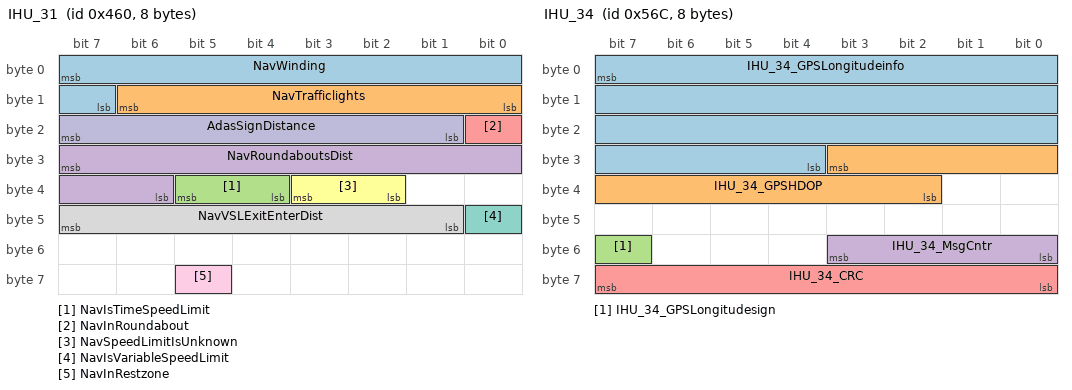
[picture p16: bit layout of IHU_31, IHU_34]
BO_ 1120 IHU_31: 8 Vector__XXX
 SG_ NavWinding : 7|9@0+ (1,0) [0|360] ""  FCM
 SG_ NavTrafficlights : 14|7@0+ (1,0) [0|100] ""  FCM
 SG_ NavIsTimeSpeedLimit : 37|2@0+ (1,0) [0|3] ""  FCM
 SG_ NavRoundaboutsDist : 31|10@0+ (1,0) [0|1000] "m"  FCM
 SG_ NavInRoundabout : 16|1@0+ (1,0) [0|1] ""  FCM
 SG_ NavSpeedLimitIsUnknown : 35|2@0+ (1,0) [0|3] ""  FCM
 SG_ NavIsVariableSpeedLimit : 40|1@0+ (1,0) [0|1] ""  FCM
 SG_ NavVSLExitEnterDist : 47|7@0+ (1,0) [0|1] "m"  FCM
 SG_ NavInRestzone : 61|1@0+ (1,0) [0|1] ""  FCM
 SG_ AdasSignDistance : 23|7@0+ (1,0) [0|100] ""  FCM

BO_ 1388 IHU_34: 8 Vector__XXX
 SG_ IHU_34_GPSLongitudeinfo : 7|28@0+ (0.000001,0) [0|180] "°"  FCM
 SG_ IHU_34_GPSHDOP : 27|10@0+ (0.1,0) [0|99.9] ""  FCM
 SG_ IHU_34_GPSLongitudesign : 55|1@0+ (1,0) [0|1] ""  FCM
 SG_ IHU_34_MsgCntr : 51|4@0+ (1,0) [0|15] ""  FCM
 SG_ IHU_34_CRC : 63|8@0+ (1,0) [0|255] ""  FCM

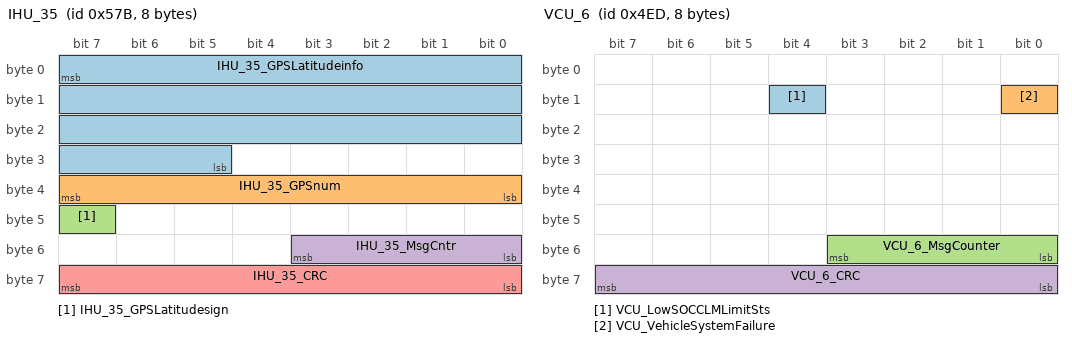
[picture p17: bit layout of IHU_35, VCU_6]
BO_ 1403 IHU_35: 8 Vector__XXX
 SG_ IHU_35_GPSLatitudeinfo : 7|27@0+ (0.000001,0) [0|90] "°"  FCM
 SG_ IHU_35_GPSnum : 39|8@0+ (1,0) [0|254] "pcs"  FCM
 SG_ IHU_35_GPSLatitudesign : 47|1@0+ (1,0) [0|1] ""  FCM
 SG_ IHU_35_MsgCntr : 51|4@0+ (1,0) [0|15] ""  FCM
 SG_ IHU_35_CRC : 63|8@0+ (1,0) [0|255] ""  FCM

BO_ 1441 IHU_40: 8 Vector__XXX
 SG_ IHU_40_IDSSwtSet : 7|2@0+ (1,0) [0|3] ""  FCM
 SG_ IHU_40_WSOSSwtSet : 5|2@0+ (1,0) [0|3] ""  FCM

BO_ 62 VCU_2: 48 Vector__XXX
 SG_ VCU_2_CRC1 : 7|8@0+ (1,0) [0|255] ""  FCM
 SG_ VCU_2_RollgCntr1 : 11|4@0+ (1,0) [0|15] ""  FCM
 SG_ VCU_2_Resd1 : 15|4@0+ (1,0) [0|1] ""  FCM
 SG_ VCU_MinActualWheelTorque : 55|16@0+ (1,-32768) [-32768|32767] "NM"  FCM
 SG_ VCU_2_CRC2 : 71|8@0+ (1,0) [0|255] ""  FCM
 SG_ VCU_2_RollgCntr2 : 75|4@0+ (1,0) [0|15] ""  FCM
 SG_ VCU_2_Resd2 : 79|4@0+ (1,0) [0|1] ""  FCM
 SG_ VCU_MaxActualWheelTorque : 87|16@0+ (1,-32768) [-32768|32767] "NM"  FCM
 SG_ VCU_2_CRC3 : 135|8@0+ (1,0) [0|255] ""  FCM
 SG_ VCU_2_RollgCntr3 : 139|4@0+ (1,0) [0|15] ""  FCM
 SG_ VCU_2_Resd3 : 143|4@0+ (1,0) [0|1] ""  FCM
 SG_ VCU_GasPedalPositionInvalidData : 173|1@0+ (1,0) [0|1] ""  FCM
 SG_ VCU_DrivePedalOverride : 171|1@0+ (1,0) [0|1] ""  FCM
 SG_ VCU_DrivePedalOverride_Valid : 170|1@0+ (1,0) [0|1] ""  FCM
 SG_ VCU_GasPedalPosition : 183|8@0+ (0.392,0) [0|99.568] "%"  FCM
 SG_ VCU_2_CRC4 : 199|8@0+ (1,0) [0|255] ""  FCM
 SG_ VCU_2_RollgCntr4 : 203|4@0+ (1,0) [0|15] ""  FCM
 SG_ VCU_PTReady : 245|1@0+ (1,0) [0|1] ""  FCM
 SG_ VCU_2_Resd4 : 207|1@0+ (1,0) [0|1] ""  FCM
 SG_ VCU_TargetGear : 213|3@0+ (1,0) [0|7] ""  FCM
 SG_ VCU_ActualGear : 210|3@0+ (1,0) [0|7] ""  FCM
 SG_ VCU_TargetGearValidData : 223|1@0+ (1,0) [0|1] ""  FCM
 SG_ VCU_ActualGearValidData : 222|1@0+ (1,0) [0|1] ""  FCM
 SG_ VCU_BrakePedalStsValidData : 221|1@0+ (1,0) [0|1] ""  FCM
 SG_ VCU_BrakePedalSts : 220|1@0+ (1,0) [0|1] ""  FCM
 SG_ VCU_LimitSpeedSts : 219|3@0+ (1,0) [0|7] ""  FCM

BO_ 1261 VCU_6: 8 Vector__XXX
 SG_ VCU_LowSOCCLMLimitSts : 12|1@0+ (1,0) [0|1] ""  FCM
 SG_ VCU_VehicleSystemFailure : 8|1@0+ (1,0) [0|1] ""  FCM
 SG_ VCU_6_MsgCounter : 51|4@0+ (1,0) [0|15] ""  FCM
 SG_ VCU_6_CRC : 63|8@0+ (1,0) [0|255] ""  FCM

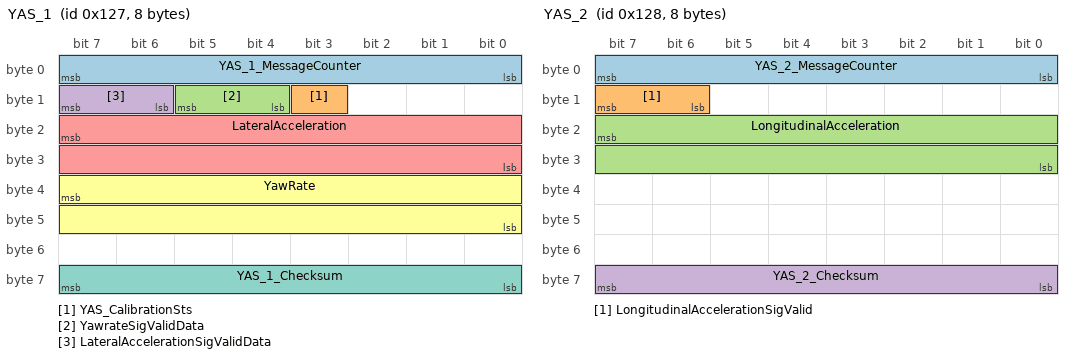
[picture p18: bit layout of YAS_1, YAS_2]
BO_ 295 YAS_1: 8 Vector__XXX
 SG_ YAS_1_MessageCounter : 7|8@0+ (1,0) [0|255] ""  FCM
 SG_ YAS_CalibrationSts : 11|1@0+ (1,0) [0|1] ""  FCM
 SG_ YawrateSigValidData : 13|2@0+ (1,0) [0|3] ""  FCM
 SG_ LateralAccelerationSigValidData : 15|2@0+ (1,0) [0|3] ""  FCM
 SG_ LateralAcceleration : 23|16@0+ (0.001,-2) [-2|2] "g"  FCM
 SG_ YawRate : 39|16@0+ (0.01,-180) [-180|180] "deg/sec"  FCM
 SG_ YAS_1_Checksum : 63|8@0+ (1,0) [0|255] ""  FCM

BO_ 296 YAS_2: 8 Vector__XXX
 SG_ YAS_2_MessageCounter : 7|8@0+ (1,0) [0|255] ""  FCM
 SG_ LongitudinalAccelerationSigValid : 15|2@0+ (1,0) [0|3] ""  FCM
 SG_ LongitudinalAcceleration : 23|16@0+ (0.001,-2) [-2|2] "g"  FCM
 SG_ YAS_2_Checksum : 63|8@0+ (1,0) [0|255] ""  FCM

BO_ 1784 XCP_FCM_REQ: 8 Vector__XXX
 SG_ XCP_FCM_REQ : 7|64@0+ (1,0) [0|1] ""  FCM

BO_ 1838 Diag_FCM_REQ: 8 Vector__XXX
 SG_ Diag_FCM_REQ : 7|64@0+ (1,0) [0|1] ""  FCM

BO_ 2015 DIAG_OBD_REQ_Broadcast: 8 Vector__XXX
 SG_ Diag_Functional_REQ : 7|64@0+ (1,0) [0|1] ""  FCM

CM_ BO_ 969 "(only for VEONEER)";
CM_ BO_ 976 "(only for VEONEER)";
CM_ BO_ 984 "(only for VEONEER)";
CM_ BO_ 986 "(only for VEONEER)";
CM_ BO_ 992 "(only for VEONEER)";
CM_ BO_ 994 "(only for Bosch)";
CM_ BO_ 745 "Source network message is 'Cyclic, 10ms'.
If no messages are received on source network, no messages are sent on the destination network.";
CM_ BO_ 787 "Source network message is 'Cyclic, 20ms'.
If no messages are received on source network, no messages are sent on the destination network.";
CM_ BO_ 790 "Source network message is 'Cyclic, 20ms'.
If no messages are received on source network, no messages are sent on the destination network.";
CM_ BO_ 608 "Source network message is 'Cyclic, 20ms'.
If no messages are received on source network, no messages are sent on the destination network.";
CM_ BO_ 641 "Source network message is 'Cyclic, 20ms'.
If no messages are received on source network, no messages are sent on the destination network.";
CM_ BO_ 1282 "Source network message is 'Cyclic, 100ms'.
If no messages are received on source network, no messages are sent on the destination network.";
CM_ BO_ 913 "Source network message is 'Cyclic, 20ms'.
If no messages are received on source network, no messages are sent on the destination network.";
CM_ BO_ 1077 "Source network message is 'Cyclic, 100ms'.
If no messages are received on source network, no messages are sent on the destination network.";
CM_ BO_ 1333 "Source network message is 'Cyclic, 100ms'.
If no messages are received on source network, no messages are sent on the destination network.";
CM_ BO_ 250 "Source network message is 'Cyclic, 10ms'.
If no messages are received on source network, no messages are sent on the destination network.";
CM_ BO_ 257 "Source network message is 'Cyclic, 10ms'.
If no messages are received on source network, no messages are sent on the destination network.";
CM_ BO_ 705 "Source network message is 'Cyclic, 10ms'.
If no messages are received on source network, no messages are sent on the destination network.";
CM_ BO_ 259 "Source network message is 'Cyclic, 10ms'.
If no messages are received on source network, no messages are sent on the destination network.";
CM_ BO_ 1057 "Source network message is 'Cyclic, 100ms'.
If no messages are received on source network, no messages are sent on the destination network.";
CM_ BO_ 1270 "Source network message is 'Cyclic, 100ms'.
If no messages are received on source network, no messages are sent on the destination network.";
CM_ BO_ 1285 "Source network message is 'Cyclic, 100ms'.
If no messages are received on source network, no messages are sent on the destination network.";
CM_ BO_ 916 "Source network message is 'Cyclic, 20ms'.
If no messages are received on source network, no messages are sent on the destination network.";
CM_ BO_ 467 "Source network message is 'Cyclic, 10ms'.
If no messages are received on source network, no messages are sent on the destination network.";
CM_ BO_ 483 "Source network message is 'Cyclic, 10ms'.
If no messages are received on source network, no messages are sent on the destination network.";
CM_ BO_ 406 "Source network message is 'Cyclic, 20ms'.
If no messages are received on source network, no messages are sent on the destination network.";
CM_ BO_ 1072 "Source network message is 'Cyclic, 20ms'.
If no messages are received on source network, no messages are sent on the destination network.";
CM_ BO_ 1106 "Source network message is 'Cyclic, 100ms'.
If no messages are received on source network, no messages are sent on the destination network.";
CM_ BO_ 1107 "Source network message is 'Cyclic, 500ms'.
If no messages are received on source network, no messages are sent on the destination network.";
CM_ BO_ 647 "Source network message is 'Cyclic, 20ms'.
If no messages are received on source network, no messages are sent on the destination network.";
CM_ BO_ 666 "Only IPB transmit this message";
CM_ BO_ 864 "Source network message is 'Cyclic, 50ms'.
If no messages are received on source network, no messages are sent on the destination network.";
CM_ BO_ 196 "Source network message is 'Cyclic, 10ms'.
If no messages are received on source network, no messages are sent on the destination network.";
CM_ BO_ 768 "Source network message is 'Cyclic, 10ms'.
If no messages are received on source network, no messages are sent on the destination network.";
CM_ BO_ 448 "Source network message is 'Cyclic, 10ms'.
If no messages are received on source network, no messages are sent on the destination network.";
CM_ BO_ 1335 "Source network message is 'Cyclic, 100ms'.
If no messages are received on source network, no messages are sent on the destination network.";
CM_ BO_ 1276 "Source network message is 'NoMsgSendType, /'.
If no messages are received on source network, no messages are sent on the destination network.";
CM_ BO_ 62 "Source network message is 'Cyclic, 10ms'.
If no messages are received on source network, no messages are sent on the destination network.";
CM_ BO_ 1261 "Source network message is 'Cyclic, 100ms'.
If no messages are received on source network, no messages are sent on the destination network.";
CM_ BO_ 295 "Source network message is 'Cyclic, 20ms'.
If no messages are received on source network, no messages are sent on the destination network.";
CM_ BO_ 296 "Source network message is 'Cyclic, 20ms'.
If no messages are received on source network, no messages are sent on the destination network.";
CM_ BO_ 1784 "Source network message is 'NoMsgSendType, /'.
If no messages are received on source network, no messages are sent on the destination network.";
CM_ BO_ 1838 "Source network message is 'NoMsgSendType, /'.
If no messages are received on source network, no messages are sent on the destination network.";
CM_ BO_ 2015 "Source network message is 'NoMsgSendType, /'.
If no messages are received on source network, no messages are sent on the destination network.";
CM_ SG_ 969 RRCR_3_Ri2ObjBoxLen "right 2 Objective Box Length";
CM_ SG_ 969 RRCR_3_Ri2ObjBoxWidth "right 2 Objective Box Width";
CM_ SG_ 969 RRCR_3_Ri2HdTo "right 2 Head towards";
CM_ SG_ 969 RRCR_3_Ri2ObjID "right 2 Objective ID";
CM_ SG_ 969 RRCR_3_Ri2ObjCoordY "Y coordinates of right 2 Objective目标物中心位置y轴坐标";
CM_ SG_ 969 RRCR_3_Ri2ObjCoordX "X coordinates of right 2Objective目标物中心位置x轴坐标";
CM_ SG_ 969 RRCR_3_Ri2ObjXDirAV "right 2 Objective X directions Acceleration velocity目标物x方向加速度";
CM_ SG_ 969 RRCR_3_Ri2ObjYDirV "right 2Objective Y directions velocity目标物y方向速度";
CM_ SG_ 969 RRCR_3_Ri2ObjXDirV "right 2Objective X directions velocity目标物x方向速度";
CM_ SG_ 969 RRCR_3_Ri2ObjMtnChartc "right 2 Objective motion characteristic目标运动特征";
CM_ SG_ 969 RRCR_3_Ri2ObjTyp "right 2 Objective type
-00 (Ukwn)： invalid（Unused objects, such as people）";
CM_ SG_ 969 RRCR_3_Ri2ObjConf "right 2 Objective confidence目标置信度";
CM_ SG_ 969 RRCR_3_Ri2ObjNrOffocst "forecast Number of right 2 Objective  目标预测次数";
CM_ SG_ 969 RRCR_3_Ri2ObjTrackSt "right 2 Objective Track state 目标追踪状态";
CM_ SG_ 969 RRCR_3_Ri2ObjCoordXDstStdDe "right 2 Objective X coordinates distance standard deviations
x轴距离标准";
CM_ SG_ 969 RRCR_3_Ri2ObjCoordYDstStdDe "right 2ObjectiveY coordinates distance standard deviations  y轴距离标准差";
CM_ SG_ 969 RRCR_3_Ri2ObjXDirVStdDe "right 2 Objective X directions velocity standard deviations x方向速度标准差";
CM_ SG_ 969 RRCR_3_Ri2ObjYDirVStdDe "right 2 Objective Y directions velocity standard deviations y方向速度标准差";
CM_ SG_ 969 RRCR_3_MsgCntr "Rolling message counter(the maximum value of Alive counter is 15)
Note: Details Please refer to specification《EE Standard Specification for CAN FD Network Implementation》section 2.3.1";
CM_ SG_ 969 RRCR_3_CRC "CRC (SAE J1850 CRC-8)
Note: Details Please refer to specification《EE Standard Specification for CAN FD Network Implementation》section 2.3.2";
CM_ SG_ 976 RRCR_4_Ri3ObjBoxLen "right 3 Objective Box Length";
CM_ SG_ 976 RRCR_4_Ri3ObjBoxWidth "right 3 Objective Box Width";
CM_ SG_ 976 RRCR_4_Ri3HdTo "right 3 Head towards";
CM_ SG_ 976 RRCR_4_Ri3ObjID "right 3 Objective ID";
CM_ SG_ 976 RRCR_4_Ri3ObjCoordY "Y coordinates of right 3 Objective目标物中心位置y轴坐标";
CM_ SG_ 976 RRCR_4_Ri3ObjCoordX "X coordinates of  right 3 Objective目标物中心位置x轴坐标";
CM_ SG_ 976 RRCR_4_Ri3ObjXDirAV "right 3 Objective X directions Acceleration velocity目标物x方向加速度";
CM_ SG_ 976 RRCR_4_Ri3ObjYDirV "right 3 Objective Y directions velocity目标物y方向速度";
CM_ SG_ 976 RRCR_4_Ri3ObjXDirV "right 3 Objective X directions velocity目标物x方向速度";
CM_ SG_ 976 RRCR_4_Ri3ObjMtnChartc "right 3 Objective motion characteristic目标运动特征";
CM_ SG_ 976 RRCR_4_Ri3ObjTyp "right 3 Objective type
-00 (Ukwn)： invalid（Unused objects, such as people）";
CM_ SG_ 976 RRCR_4_Ri3ObjConf "right 3 Objective confidence目标置信度";
CM_ SG_ 976 RRCR_4_Ri3ObjNrOffocst "forecast Number of right 3 Objective  目标预测次数";
CM_ SG_ 976 RRCR_4_Ri3ObjTrackSt "right 3 Objective Track state 目标追踪状态";
CM_ SG_ 976 RRCR_4_Ri3ObjCoordXDstStdDe "right 3 Objective X coordinates distance standard deviations
x轴距离标准";
CM_ SG_ 976 RRCR_4_Ri3ObjCoordYDstStdDe "right 3 ObjectiveY coordinates distance standard deviations  y轴距离标准差";
CM_ SG_ 976 RRCR_4_Ri3ObjXDirVStdDe "right 3 Objective X directions velocity standard deviations x方向速度标准差";
CM_ SG_ 976 RRCR_4_Ri3ObjYDirVStdDe "right 3 Objective Y directions velocity standard deviations y方向速度标准差";
CM_ SG_ 976 RRCR_4_MsgCntr "Rolling message counter(the maximum value of Alive counter is 15)
Note: Details Please refer to specification《EE Standard Specification for CAN FD Network Implementation》section 2.3.1";
CM_ SG_ 976 RRCR_4_CRC "CRC (SAE J1850 CRC-8)
Note: Details Please refer to specification《EE Standard Specification for CAN FD Network Implementation》section 2.3.2";
CM_ SG_ 984 RRCR_5_Ri4ObjBoxLen "right 4 Objective Box Length";
CM_ SG_ 984 RRCR_5_Ri4ObjBoxWidth "right 4 Objective Box Width";
CM_ SG_ 984 RRCR_5_Ri4HdTo "right 4 Head towards";
CM_ SG_ 984 RRCR_5_Ri4ObjID "right 4 Objective ID";
CM_ SG_ 984 RRCR_5_Ri4ObjCoordY "Y coordinates of right 4 Objective目标物中心位置y轴坐标";
CM_ SG_ 984 RRCR_5_Ri4ObjCoordX "X coordinates of  right 4 Objective目标物中心位置x轴坐标";
CM_ SG_ 984 RRCR_5_Ri4ObjXDirAV "right 4 Objective X directions Acceleration velocity目标物x方向加速度";
CM_ SG_ 984 RRCR_5_Ri4ObjYDirV "right 4 Objective Y directions velocity目标物y方向速度";
CM_ SG_ 984 RRCR_5_Ri4ObjXDirV "right 4 Objective X directions velocity目标物x方向速度";
CM_ SG_ 984 RRCR_5_Ri4ObjMtnChartc "right 4 Objective motion characteristic目标运动特征";
CM_ SG_ 984 RRCR_5_Ri4ObjTyp "right 4Objective type
-00 (Ukwn)： invalid（Unused objects, such as people）";
CM_ SG_ 984 RRCR_5_Ri4ObjConf "right 4 Objective confidence目标置信度";
CM_ SG_ 984 RRCR_5_Ri4ObjNrOffocst "forecast Number of right 4 Objective  目标预测次数";
CM_ SG_ 984 RRCR_5_Ri4ObjTrackSt "right 4 Objective Track state 目标追踪状态";
CM_ SG_ 984 RRCR_5_Ri4ObjCoordXDstStdDe "right 4 Objective X coordinates distance standard deviations
x轴距离标准";
CM_ SG_ 984 RRCR_5_Ri4ObjCoordYDstStdDe "right 4 ObjectiveY coordinates distance standard deviations  y轴距离标准差";
CM_ SG_ 984 RRCR_5_Ri4ObjXDirVStdDe "right 4 Objective X directions velocity standard deviations x方向速度标准差";
CM_ SG_ 984 RRCR_5_Ri4ObjYDirVStdDe "right 4 Objective Y directions velocity standard deviations y方向速度标准差";
CM_ SG_ 984 RRCR_5_MsgCntr "Rolling message counter(the maximum value of Alive counter is 15)
Note: Details Please refer to specification《EE Standard Specification for CAN FD Network Implementation》section 2.3.1";
CM_ SG_ 984 RRCR_5_CRC "CRC (SAE J1850 CRC-8)
Note: Details Please refer to specification《EE Standard Specification for CAN FD Network Implementation》section 2.3.2";
CM_ SG_ 986 RRCR_6_Ri5ObjBoxLen "right 5 Objective Box Length";
CM_ SG_ 986 RRCR_6_Ri5ObjBoxWidth "right 5 Objective Box Width";
CM_ SG_ 986 RRCR_6_Ri5HdTo "right 5 Head towards";
CM_ SG_ 986 RRCR_6_Ri5ObjID "right 5 Objective ID";
CM_ SG_ 986 RRCR_6_Ri5ObjCoordY "Y coordinates of right 5 Objective目标物中心位置y轴坐标";
CM_ SG_ 986 RRCR_6_Ri5ObjCoordX "X coordinates of  right 5 Objective目标物中心位置x轴坐标";
CM_ SG_ 986 RRCR_6_Ri5ObjXDirAV "right 5 Objective X directions Acceleration velocity目标物x方向加速度";
CM_ SG_ 986 RRCR_6_Ri5ObjYDirV "right 5 Objective Y directions velocity目标物y方向速度";
CM_ SG_ 986 RRCR_6_Ri5ObjXDirV "right 5 Objective X directions velocity目标物x方向速度";
CM_ SG_ 986 RRCR_6_Ri5ObjMtnChartc "right 5 Objective motion characteristic目标运动特征";
CM_ SG_ 986 RRCR_6_Ri5ObjTyp "right 5 Objective type
-00 (Ukwn)： invalid（Unused objects, such as people）";
CM_ SG_ 986 RRCR_6_Ri5ObjConf "right 5 Objective confidence目标置信度";
CM_ SG_ 986 RRCR_6_Ri5ObjNrOffocst "forecast Number of right 5 Objective  目标预测次数";
CM_ SG_ 986 RRCR_6_Ri5ObjTrackSt "right 5 Objective Track state 目标追踪状态";
CM_ SG_ 986 RRCR_6_Ri5ObjCoordXDstStdDe "right 5 Objective X coordinates distance standard deviations
x轴距离标准";
CM_ SG_ 986 RRCR_6_Ri5ObjCoordYDstStdDe "right 5 ObjectiveY coordinates distance standard deviations  y轴距离标准差";
CM_ SG_ 986 RRCR_6_Ri5ObjXDirVStdDe "right 5 Objective X directions velocity standard deviations x方向速度标准差";
CM_ SG_ 986 RRCR_6_Ri5ObjYDirVStdDe "right 5 Objective Y directions velocity standard deviations y方向速度标准差";
CM_ SG_ 986 RRCR_6_MsgCntr "Rolling message counter(the maximum value of Alive counter is 15)
Note: Details Please refer to specification《EE Standard Specification for CAN FD Network Implementation》section 2.3.1";
CM_ SG_ 986 RRCR_6_CRC "CRC (SAE J1850 CRC-8)
Note: Details Please refer to specification《EE Standard Specification for CAN FD Network Implementation》section 2.3.2";
CM_ SG_ 992 RRCR_7_TiStampLaten "timestamp Latency时间戳同步用的延迟，生成目标到发到总线上的时间，提供平均值";
CM_ SG_ 992 RRCR_7_MsgCntr "Rolling message counter(the maximum value of Alive counter is 15)
Note: Details Please refer to specification《EE Standard Specification for CAN FD Network Implementation》section 2.3.1";
CM_ SG_ 992 RRCR_7_CRC "CRC (SAE J1850 CRC-8)
Note: Details Please refer to specification《EE Standard Specification for CAN FD Network Implementation》section 2.3.2";
CM_ SG_ 994 RRCR_8_ObjVldFlg "Right Object valid flag(For Bosch)目标有效位";
CM_ SG_ 994 RRCR_8_LgtDst "Right Longitudinal distance(For Bosch)纵向距离（以车辆后轴中心作为原点）";
CM_ SG_ 994 RRCR_8_LgtRelV "Right Longitudinal relative velocity(For Bosch)   纵向相对速度";
CM_ SG_ 994 RRCR_8_MsgCntr "Rolling message counter(the maximum value of Alive counter is 15)
Note: Details Please refer to specification《EE Standard Specification for CAN FD Network Implementation》section 2.3.1";
CM_ SG_ 994 RRCR_8_CRC "CRC (SAE J1850 CRC-8)
Note: Details Please refer to specification《EE Standard Specification for CAN FD Network Implementation》section 2.3.2";
CM_ SG_ 745 ABS_ESP_1_VDCActive "ESP lamp on ICM should blinking ;VDC Intervention";
CM_ SG_ 745 ABS_ESP_1_TCSActive "ESP lamp on ICM should blinking; TCS Intervention";
CM_ SG_ 745 ABS_ESP_1_PressureMasterCylinder "ESP：主缸压力";
CM_ SG_ 745 ESP1_PressureMasCylindValidData "Valid check bit of the signal ABS_ESP_1_PressureMasterCylinder";
CM_ SG_ 745 ABS_ESP_1_Checksum "((Byte0+Byte1+ Byte2+Byte3+Byte4+Byte6+Byte7) AND 0xFF) XOR 0xFF";
CM_ SG_ 745 ABS_ESP_1_ESPSwitchStatus "“1” means VDC and Engine Traction Control System (PTC) Function and Brake Traction Control System (BTC) Function disabled and Ignit ESP lamp.
0x0：ESP功能开启
0x1：ESP功能关闭";
CM_ SG_ 787 NoBrakeForce "No brake pressure applied
Generally it regards wheel cylinder pressure";
CM_ SG_ 787 ABS_ESP_3_AVHFailSts "AutoHold功能失效状态";
CM_ SG_ 787 ABS_ESP_3_AVHSts "Auto Hold功能状态";
CM_ SG_ 787 ABS_ESP_3_MessageCounter "Rolling message counter(the maximum value of Alive counter is 15)
Note: Details Please refer to specification《EE Standard Specification for CAN FD Network Implementation》section 2.3.1";
CM_ SG_ 787 ABS_ESP_3_Checksum "((Byte0+Byte1+ Byte2+Byte3+Byte4+Byte5+Byte6) AND 0xFF) XOR 0xFF
Note: Details Please refer to specification《EE Standard Specification for CAN FD Network Implementation》section 2.3.3";
CM_ SG_ 790 VLC_InternalTargetAcceleration "VLC内部加速度";
CM_ SG_ 790 VehicleStandstill "车辆静止状态";
CM_ SG_ 790 ECDTempOff "制动盘温度过高";
CM_ SG_ 790 DCFail "不能执行ACC的减速功能时通知FRM";
CM_ SG_ 790 VLC_Active "VLC激活";
CM_ SG_ 790 VLC_Available "VLC可用";
CM_ SG_ 790 ABS_ESP_4_MessageCounter "Rolling message counter(the maximum value of Alive counter is 15)
Note: Details Please refer to specification《Standard Specification for CAN Data Link Layer_v1.1》section 2.3.1";
CM_ SG_ 790 ABS_ESP_4_Checksum "((Byte0+Byte1+ Byte2+Byte3+Byte4+Byte5+Byte6) AND 0xFF) XOR 0xFF
Note: Details Please refer to specification《Standard Specification for CAN Data Link Layer_v1.1》section 2.3.3";
CM_ SG_ 608 QDCACC "ACC error detected by ESP, like timeout or alivecounter error.
The error should distinguish reversible and irreversible errors.";
CM_ SG_ 608 WheelBrakeForce "Four-wheel total braking force
0xF425~0xFFFE：Not Used";
CM_ SG_ 608 ABSESP_7_MessageCounter "Rolling message counter(the maximum value of Alive counter is 15)
Note: Details Please refer to specification《Standard Specification for CAN Data Link Layer_v1.1》section 2.3.1";
CM_ SG_ 608 ABSESP_7_Checksum "((Byte0+Byte1+ Byte2+Byte3+Byte4+Byte5+Byte6) AND 0xFF) XOR 0xFF
Note: Details Please refer to specification《Standard Specification for CAN Data Link Layer_v1.1》section 2.3.3";
CM_ SG_ 641 ABPActive "Automatic Brake Pre-fill--自动预制动";
CM_ SG_ 641 AEBdecActive "AEB  braking function";
CM_ SG_ 641 ABSESP_8_MessageCounter "Rolling message counter(the maximum value of Alive counter is 15)
Note: Details Please refer to specification《Standard Specification for CAN Data Link Layer_v1.1》section 2.3.1";
CM_ SG_ 641 ABSESP_8_Checksum "((Byte0+Byte1+ Byte2+Byte3+Byte4+Byte5+Byte6) AND 0xFF) XOR 0xFF
Note: Details Please refer to specification《Standard Specification for CAN Data Link Layer_v1.1》section 2.3.3";
CM_ SG_ 1282 CDPActive "动态制动时：仪表接收CDPActive=1_active或RWUActive=1_active，仪表驻车灯闪烁";
CM_ SG_ 913 HighBeamSts "HighBeamFlash function uses this signal.";
CM_ SG_ 913 BCM_1_Checksum "((Byte0+Byte2+Byte3+Byte4+Byte5+Byte6+Byte7) AND 0xFF) XOR 0xFF
Note: Details Please refer to specification《Standard Specification for CAN Data Link Layer_v1.1》section 2.3.3";
CM_ SG_ 913 DirectionIndRight "当右转向灯闪烁时一直发1，转向灯熄灭时一直发0.";
CM_ SG_ 913 DirectionIndLeft "当左转向灯闪烁时一直发1，转向灯熄灭时一直发0.";
CM_ SG_ 913 HazardLightSW "带自锁的开关，按照危险灯状态发送；不带自锁的开关，发送危险灯状态";
CM_ SG_ 913 AutoLightSW "AUTO灯开关，拨到该位置（打开）发1，不拨到该位置（关闭）发0，默认发0";
CM_ SG_ 913 HMASW "Intelligent Headlamp Control Switch From BCM";
CM_ SG_ 913 ReverseGearSts "MT：BCM接倒车开关硬线。
AT：BCM接TCU发的倒档CAN信号。
MT的车，ESP接收从BCM过来的ReverseGearSts信号
AT的车，ESP 接收从TCU过来的ActualGear信号";
CM_ SG_ 913 LHTurnSW "左转向开关，打开发1；关闭发0，默认发0";
CM_ SG_ 913 RHTurnSW "右转向开关，打开发1；关闭发0，默认发0";
CM_ SG_ 913 RainDetected "Rain detected
检测到有无雨量";
CM_ SG_ 913 AutoHighSpeedRequest "Auto high speed request
让高速雨刮电机工作";
CM_ SG_ 913 BCM_1_MessageCounter "Rolling message counter(the maximum value of Alive counter is 15)
Note: Details Please refer to specification《Standard Specification for CAN Data Link Layer_v1.1》section 2.3.1";
CM_ SG_ 1077 TrailerConnectSts "拖车连接状态";
CM_ SG_ 1333 CLM2_AliveCounter "Rolling message counter(the maximum value of Alive counter is 15)
Note: Details Please refer to specification《Standard Specification for CAN Data Link Layer_v1.1》section 2.3.1
备注：外控变排量增加此信号";
CM_ SG_ 1333 CLM2_CRC "CRC (SAE J1850 CRC-8)
Note: Details Please refer to specification《Standard Specification for CAN Data Link Layer_v1.1》section 2.3.2
备注：外控变排量增加此信号";
CM_ SG_ 1039 DMS_1_DMSSt "DMS State";
CM_ SG_ 1039 DMS_1_CameraSt "Camera State";
CM_ SG_ 1039 DMS_1_DriverSts "Driver status signal";
CM_ SG_ 1039 DMS_1_MessageCounter "Rolling message counter(the maximum value of Alive counter is 15)
Note: Details Please refer to specification《EE Standard Specification for CAN  Network Implementation》section 2.3.1";
CM_ SG_ 1039 DMS_1_CRC "CRC (SAE J1850 CRC-8)
Note: Details Please refer to specification《EE Standard Specification for CAN  Network Implementation》section 2.3.2";
CM_ SG_ 250 EMS_1_Checksum "((Byte0+Byte1+Byte3+Byte4+Byte5+Byte6+Byte7) AND 0xFF) XOR 0xFF
Note: Details Please refer to specification《Standard Specification for CAN Data Link Layer_v1.1》section 2.3.3";
CM_ SG_ 250 CruiseControlStatus "Cruise Control Status";
CM_ SG_ 250 AcceleratorPosRaw "Raw position of the accelerator pedal (unfiltered). Represents always raw pedal position without any other influcence only mandatory to calculated gradient acceleration pedal.";
CM_ SG_ 250 NeutralGearSts "Neutral Gear Status
空档状态信号
This signal is reserved ,because PHEV doesn't have MT";
CM_ SG_ 250 ECGPOvrd "标识驾驶员扭矩高于ACC请求扭矩
Identify driver torque is higher than ACC requested torque";
CM_ SG_ 250 EMS_1_MessageCounter "Rolling message counter(the maximum value of Alive counter is 15)
Note: Details Please refer to specification《Standard Specification for CAN Data Link Layer_v1.1》section 2.3.1";
CM_ SG_ 257 EngineStsForDCT "发动机状态信号";
CM_ SG_ 705 SSMStatus "用于起停状态机的各种状态
0-Reset Start/Stop not active(any engine condition possible)
开关关掉
1-StandbyS/S active, engine off(waiting for initial keybutton start)
默认状态，奇瑞默认上电开启
2- StoppedS/S active, engine standstill
3- Starter RestartSS/ active starter engine is turning 
是指需要通过起动机来启动
4 - Engine RestartS/S active, engine runs up
只是不需要起动机介入就可以自动启动，比如说正在停机过程中，转速还没有到0，驾驶员改变的意图，不想停机了。因为这时候转速还比较高，不需要起动机拖动，直接恢复供油就可以启动了。
5 - OperationS/S active, engine is running
6 - Auto StoppingS/S active, engine is turning but no fuel injection anymore
若无ISS功能，该信号发000";
CM_ SG_ 705 EMS_3_MessageCounter "Rolling message counter(the maximum value of Alive counter is 15)
Note: Details Please refer to specification《Standard Specification for CAN Data Link Layer_v1.1》section 2.3.1";
CM_ SG_ 705 EMS_3_Checksum "((Byte0+Byte1+Byte2+Byte3+Byte4+Byte5+Byte6) AND 0xFF) XOR 0xFF
Note: Details Please refer to specification《Standard Specification for CAN Data Link Layer_v1.1》section 2.3.3";
CM_ SG_ 259 ECGPOvrd "标识驾驶员扭矩高于ACC请求扭矩";
CM_ SG_ 259 BrakePedalStsValidDataForTCU "Valid check bit of the signal BrakePedalStsForTCU";
CM_ SG_ 259 BrakePedalStsForTCU "Brake Pedal Status For TCU";
CM_ SG_ 259 EMS6_MessageCounter "Rolling message counter(the maximum value of Alive counter is 15)
Note: Details Please refer to specification《EE Standard Specification for CAN FD Network Implementation》section 2.3.1";
CM_ SG_ 259 EMS6_CRC "CRC (SAE J1850 CRC-8)
Note: Details Please refer to specification《EE Standard Specification for CAN FD Network Implementation》section 2.3.2";
CM_ SG_ 1057 LimitSpeedSts "Off：关闭主动限速功能
Standby：打开主动限速功能但未激活
Overspeed：限速功能激活后当前车速超过限速值
Limit：限速功能激活
Cancel：暂时退出主动限速状态
Kickdown：油门踩到底";
CM_ SG_ 1057 GasPedalPosition "Driver/Cruise control
This signal including compositive informations which are actual gas pedal position and dummy Cruise control gas pedal position";
CM_ SG_ 1057 EMS_2_G_MessageCounter "Rolling message counter(the maximum value of Alive counter is 15)
Note: Details Please refer to specification《EE Standard Specification for CAN FD Network Implementation_V6.0》section 2.3.1";
CM_ SG_ 1057 EMS_2_G_CRC "CRC (SAE J1850 CRC-8)
Note: Details Please refer to specification《EE Standard Specification for CAN FD Network Implementation_V6.0》section 2.3.2";
CM_ SG_ 1270 EPBErrorStatus "用于EPB故障显示
夹紧力不够时也发Error";
CM_ SG_ 1270 EPBStatus "（此信号EV/PHEV专用）
卡钳处于释放状态
卡钳处于夹紧状态
卡钳正处于释放过程中
卡钳正处于夹紧过程中
未知状态：当前卡钳处于未知状态
ErrorApplied：
当EPBError之前卡钳已经处于夹紧状态,用户再操作EPB(apply)开关时发101进行闪烁报警；
当EPBError之后卡钳处于夹紧状态,发101进行闪烁报警。";
CM_ SG_ 1270 RWUActive "动态制动时：仪表接收CDPActive=1_active或RWUActive=1_active，仪表驻车灯闪烁";
CM_ SG_ 1285 EPS_AssistanceStyle_Sts "0x0: 'sport'
0x1: 'comfort'
0x2: 'normal'";
CM_ SG_ 916 TorsionBarTorque "驾驶员输入方向盘扭矩";
CM_ SG_ 916 TorsionBarTorqueDir "方向盘扭矩方向";
CM_ SG_ 916 EpsControlStatus "为LKS对EPS的控制信号";
CM_ SG_ 916 EPS_2_Message_Counter "Rolling message counter(the maximum value of Alive counter is 15)
Note: Details Please refer to specification《Standard Specification for CAN Data Link Layer_v1.1》section 2.3.1";
CM_ SG_ 916 EPS_2_CRC "CRC (SAE J1850 CRC-8)
Note: Details Please refer to specification《Standard Specification for CAN Data Link Layer_v1.1》section 2.3.2";
CM_ SG_ 467 EPS_3_StrngWhlAg "EPS实时监测的方向盘转角信号
EPS shall provide the calculated angle from steering wheel.The result is average of the right wheel and the left wheel.";
CM_ SG_ 467 EPS_3_StrngWhlAgValid "EPS转角响应有效状态";
CM_ SG_ 467 EPS_3_StrngAgSpdValidData "Strng Angle Speed Valid Data(for Veoneer)";
CM_ SG_ 467 EPS_3_StrngAgSpd "Strng Angle Speed(for Veoneer)";
CM_ SG_ 467 EPS_3_AgFailr "Angle Failure";
CM_ SG_ 467 EPS_3_Message_Counter "Rolling message counter(the maximum value of Alive counter is 15)
Note: Details Please refer to specification《Standard Specification for CAN Data Link Layer_v1.1》section 2.3.1";
CM_ SG_ 467 EPS_3_CRC "CRC (SAE J1850 CRC-8)
Note: Details Please refer to specification《Standard Specification for CAN Data Link Layer_v1.1》section 2.3.2";
CM_ SG_ 483 EPS_4_LoASts "(only for VEONEER)
EPSLoAStatus_HandsFree. Indicate whether loss of assisstence fault happens
EPS失去助力状态位";
CM_ SG_ 483 EPS_4_LatDrvgAvlForLvl "EPS lateral driving service availability for level 1 or 2.
角度端口 是否支持角度控制";
CM_ SG_ 483 EPS_4_HptcVibSrvAvl "Steering wheel vibration service availability
方向盘震动状态位";
CM_ SG_ 483 EPS_4_AgCtrlLimActvd "(only for VEONEER)
0:The angle controller has not been limited.
1:The angle controller has been limited by
AgCtrlTqMaxLim.
2:The angle controller has been limited by
AgCtrlTqMinLim.
3:The angle controller has been rate limited by
PinionAgRateLim.";
CM_ SG_ 483 EPS_4_PSCMActRPCTrqValid "(only for VEONEER)
EPS电机端扭矩校验位";
CM_ SG_ 483 EPS_4_PSCMActRPCTrq "(only for VEONEER)
Actual RPC torque request (TBT level)
EPS电机端扭矩";
CM_ SG_ 483 EPS_4_ManMachineSharingSts "EPS是否支持人机共驾标志位";
CM_ SG_ 483 EPS_4_Message_Counter "Rolling message counter(the maximum value of Alive counter is 15)
Note: Details Please refer to specification《Standard Specification for CAN Data Link Layer_v1.1》section 2.3.1";
CM_ SG_ 483 EPS_4_CRC "CRC (SAE J1850 CRC-8)
Note: Details Please refer to specification《Standard Specification for CAN Data Link Layer_v1.1》section 2.3.2";
CM_ SG_ 406 EPB_State_R_CRC1 "CRC (SAE J1850 CRC-8) Note: Details Please refer to specification《EE Standard Specification for CAN FD Network Implementation》section 2.3.2";
CM_ SG_ 406 EPB_State_R_RollgCntr1 "Rolling message counter(the maximum value of Alive counter is 15) Note: Details Please refer to specification《EE Standard Specification for CAN FD Network Implementation》section 2.3.1";
CM_ SG_ 406 EPB_FltLvl "EPB故障状态";
CM_ SG_ 406 EPBStatus "EPB Status
For EEA4.0";
CM_ SG_ 263 HCU_6_ECGPOvrd "标识驾驶员扭矩高于ACC请求扭矩";
CM_ SG_ 263 HCU_BrakePedalStsValidDataForTCU "Valid check bit of the signal BrakePedalStsForTCU";
CM_ SG_ 263 HCU_6_BrakePedalStsForTCU "Brake Pedal Status For TCU";
CM_ SG_ 263 HCU_6_MessageCounter "Alivecounter";
CM_ SG_ 263 HCU_6_CRC "CRC";
CM_ SG_ 269 PRNDGearAct "Actual PRND gear as evaluated by HCU.";
CM_ SG_ 269 PRNDGearActValidData "Valid check bit of the signal  PRNDGearAct";
CM_ SG_ 269 PRNDGearTarget "Target PRND gear as evaluated by HCU.";
CM_ SG_ 269 HCU_17_MessageCounter "Alivecounter";
CM_ SG_ 269 HCU_17_CRC "CRC";
CM_ SG_ 1034 HCU_PTReady "Drive Ready indication";
CM_ SG_ 1034 HCU_PowertrainFault "Powertrain fault";
CM_ SG_ 1046 HCU_PowerLimit "Power Limit";
CM_ SG_ 1046 HCU_GasPedalPosition "Driver/Cruise control
This signal including compositive informations which are actual gas pedal position and dummy Cruise control gas pedal position";
CM_ SG_ 1046 HCU_GasPedalPositionInvalidData "gas pedal position valid";
CM_ SG_ 1046 HCU_BrakePedalStsValidData "brake pedal position";
CM_ SG_ 1046 HCU_BrakePedalSts "brake pedal position valid";
CM_ SG_ 1072 DisplayVehicleSpeed "仪表显示的车速，比实际车速略大。";
CM_ SG_ 1072 ECOModeSWSts "信号值为1代表'ECO'，0代表'Sport'
MT无有ECO模式。";
CM_ SG_ 1072 ICM_1MessageCounter "Rolling message counter(the maximum value of Alive counter is 15)
Note: Details Please refer to specification《Standard Specification for CAN Data Link Layer_v1.1》section 2.3.1";
CM_ SG_ 1106 DISFail "Error in the display or display control unit.
TFT本身有个输出PIN脚，可以通过检测这个PIN能发现屏本身参数设置是否有问题，但屏损坏不能正常工作时可能会影响这个PIN输出造成判断错误;";
CM_ SG_ 1106 QDashACCFail "Error in the ACC message detected by the HMI, like timeout or alivecounter error.
The error should distinguish reversible and irreversible errors.
屏上的报警指示灯显示方法是原指示灯图片与背景叠加在一起显示。如果要判断指示灯是否有问题就需要把指示灯显示区域的图抠出来分离出指示灯的图片与原图作对比，这个技术暂时无法实现;";
CM_ SG_ 1107 CurrentTimeHour "ICM把当前时钟信号回馈给
DVD用于时间设置接口
若断蓄电池电，发0 (Not active)；初始化期间发0 (Startup)；若断15电后再上电，发当前时钟信息(仪表通过晶振自动更新时间)。";
CM_ SG_ 1107 CurrentTimeMinute "ICM把当前分钟信号回馈
DVD用于时间设置接口
若断蓄电池电，发0 (Not active)；初始化期间发0 (Startup)；若断15电后再上电，发当前时钟信息(仪表通过晶振自动更新时间)。";
CM_ SG_ 1107 CurrentTimeSecond "ICM把当前秒钟信号回馈
DVD；
若断蓄电池电，发0 (Not active)；
初始化期间发0 (Startup)；若断15电后再上电，发当前时钟信息(仪表通过晶振自动更新时间)。";
CM_ SG_ 1107 CurrentTimeDay "日";
CM_ SG_ 1107 CurrentTimeMonth "月";
CM_ SG_ 1107 CurrentTimeYear "年";
CM_ SG_ 647 ICM_5_MessageCounter "Rolling message counter(the maximum value of Alive counter is 15)
Note: Details Please refer to specification《Standard Specification for CAN Data Link Layer_v1.1》section 2.3.1";
CM_ SG_ 647 ICM_5_Checksum "((Byte0+Byte1+Byte2+Byte3+Byte4+Byte5+Byte6) AND 0xFF) XOR 0xFF
Note: Details Please refer to specification《Standard Specification for CAN Data Link Layer_v1.1》section 2.3.3";
CM_ SG_ 666 IPB_InputRodStroke "Indicate inputRod stroke for pedal travel";
CM_ SG_ 666 IPB_InputRodStrokeStatus "Indicate inputRod stroke for pedal travel";
CM_ SG_ 666 IPB_ESP_11_CRC "(SAE J1850 CRC-8)";
CM_ SG_ 864 CHKSM_MFS_2 "Checksum (SAE J1850 CRC-8).";
CM_ SG_ 864 ALIVE_MFS_2 "Alive counter.";
CM_ SG_ 864 MFS_2_LeftRoller "备注：左滚轮方向（仅T1GC项目E系列方向盘使用）";
CM_ SG_ 864 MFS_Cruise_Control "Cruise Control ON/OFF button";
CM_ SG_ 864 MFS_Speed_limit "Speed limit ON/OFF button";
CM_ SG_ 864 MFS_RESPlus "CC/SL RES/+ button";
CM_ SG_ 864 MFS_SETMinus "CC/SL SET/- button";
CM_ SG_ 864 MFS_2_LeRollrUpDwnAdjSteps "备注：左滚轮步数信号（仅T1GC项目E系列方向盘使用）";
CM_ SG_ 864 MFS_Time_Gap_Add "Distance increases";
CM_ SG_ 864 MFS_Time_Gap_Reduce "distance decreases";
CM_ SG_ 196 SteeringAngle "The actual range is from -720 deg to +720 deg.";
CM_ SG_ 196 AngleFailure "此错误为角度传感器（SAS）自身的错误。在
SAS未能进行标定或角度超过允许范围时发1-failure";
CM_ SG_ 196 SAM_1_G_MessageCounter "Rolling message counter(the maximum value of Alive counter is 15)
Note: Details Please refer to specification《Standard Specification for CAN Data Link Layer_v1.1》section 2.3.1";
CM_ SG_ 196 SAM_1_GCRCCheck "CRC (SAE J1850 CRC-8)
Note: Details Please refer to specification《Standard Specification for CAN Data Link Layer_v1.1》section 2.3.2";
CM_ SG_ 768 GBPositoionDisplayForPEPS "DCT这个信号为换挡杆物理位置；CVT这个信号，_G中档位显示信号属性可以覆盖此信号。
PEPS：获取P档和N档信号
目标档位
CVT可用到属性里的1-9gear
和PRND。
4AT可用到属性里的1-4gear和PRND。
AMT可用到属性里的RND（AMT由手动变速箱更改过来的，没有增加驻车锁，所以没有P档）。
DCT只发出0001、1011、1100、1101、1110、1111";
CM_ SG_ 768 DriverMode "CVT有正常、运动、冬季模式；4AT有正常、运动、冬季模式；AMT有正常、经济模式；
DCT有正常、ECO模式，ECO模式通过其他模块给开关信号。";
CM_ SG_ 768 ShiftInProgress "Shift In progress:
shows if a gear shift is
actually in progress";
CM_ SG_ 768 TargetGear "The gear that the gearbox is currently changing to (this is valid when Gearshift In Progress equals 1).
Target gear是指变速箱将要达到的档位。
Actual gear是指变速箱现在实际的档位
DCT无0111,1000两个属性";
CM_ SG_ 768 TCU_2_Checksum "((Byte0+Byte1+……+Byte6) AND 0xFF) XOR 0xFF";
CM_ SG_ 448 ALIVE_TCU_4 "Rolling message counter(the maximum value of Alive counter is 15)
Note: Details Please refer to specification《Standard Specification for CAN Data Link Layer_v1.1》section 2.3.1";
CM_ SG_ 448 CRC_TCU_4 "CRC (SAE J1850 CRC-8)
Note: Details Please refer to specification《Standard Specification for CAN Data Link Layer_v1.1》section 2.3.2";
CM_ SG_ 1335 NavSpeedLimitStatus "NavSpeedLimitStatus
0x0'SL_UNKNOWN';导航不可用
0x1'SL_EXISTS';有限速
0x2'SL_NOLIMIT';无限速
0x3'SL_PLURAL'.有匝道
专业将0x0定义为故障信号，默认发送故障信号，易导致FCM下线报错
0x2包含导航无限速和德国高速不限速两种情况
0x3表示驶入没有数据的国家/GPS信号弱/无GPS信号，也用于表示地图不可用";
CM_ SG_ 1335 NavSpeedLimit "NavSpeedLimit";
CM_ SG_ 1335 NavSpeedLimitUnits "NavSpeedLimitUnits";
CM_ SG_ 1335 SLASpdLimChgAudSwSet "提示开关限速值改变";
CM_ SG_ 1276 IHU_11_AEBSwtSet "AEB switch set";
CM_ SG_ 1276 IHU_11_FCWSnvtySet "FCW_Sensitivity_Set";
CM_ SG_ 1276 IHU_11_FCWSwtSet "FCW switch set";
CM_ SG_ 1276 IHU_11_TJAICAExitTextInfoSwtSet "TJAICA Exit Text Information switch set";
CM_ SG_ 1276 IHU_11_SLASwtSet "SLA switch set";
CM_ SG_ 1276 IHU_11_SCFSwtSet "SCF switch set";
CM_ SG_ 1276 IHU_11_DAISwtSet "DAI switch set";
CM_ SG_ 1276 IHU_11_IESSwtSet "IES switch set";
CM_ SG_ 1276 IHU_11_HMASwtSet "HMA switch set";
CM_ SG_ 1276 IHU_11_TSISwtSet "TSI  switch set";
CM_ SG_ 1276 IHU_11_TLISwtSet "TLI  switch set";
CM_ SG_ 1276 IHU_11_LDWSwtSet "LDW switch set";
CM_ SG_ 1276 IHU_11_WarnModSwtSet "warning mode switch set";
CM_ SG_ 1276 IHU_11_LDPSwtSet "LDP switch set";
CM_ SG_ 1276 IHU_11_LDWLDPSnvtySet "LDWLDP Senstitivity set";
CM_ SG_ 1276 IHU_11_ELKSwtSet "ELK switch set";
CM_ SG_ 1330 IHU_29_SLAMode "限速提醒，增加绝对和相对切换信号";
CM_ SG_ 1330 IHU_29_SpeedLmtNmberAb "限速阈值调整信号，从-10到10";
CM_ SG_ 1330 IHU_29_SpeedLmtNmberE "限速阈值调整相对信号，从-20%到20%";
CM_ SG_ 1092 NavCountryCodeInfo "国家代码";
CM_ SG_ 1092 NavSpeedLimit_ISA "道路限速值-EV欧洲";
CM_ SG_ 1092 NavRainSpeedLimit "雨天道路限速值";
CM_ SG_ 1092 NavSnowSpeedLimit "雪天道路限速值";
CM_ SG_ 1092 NavFogSpeedLimit "大雾道路限速值";
CM_ SG_ 1092 NavSpeedLimitType "道路限速类型";
CM_ SG_ 1092 NavRampInfo "前方路口匝道信息
0x0:unknown 导航不可用
0x1:exists 前方1公里内第一个岔路口有匝道
0x2:About to leave 即将离开匝道";
CM_ SG_ 1092 NavRampDistance "距离匝道距离";
CM_ SG_ 1092 NavRoundabouts "0表示前方100米内无圆环，非0表示前方100米内有圆环和限速值，例：50=有圆环，圆环限速50";
CM_ SG_ 1092 NavJunctions "0表示前方100米内无交叉口，非0表示前方100米内有交叉口和距离，例：60=距离交叉口60米";
CM_ SG_ 1120 NavWinding "前方道路的弯曲角度，取值范围0~360度；
计算角度方案：根据道路限速，暂定道路等级1和2为1000米，3和4为600米，5为400米，后面根据路测效果校调；
多少度算弯路由ADAS定";
CM_ SG_ 1120 NavTrafficlights "0表示前方100米内无红绿灯，非0表示前方100米内有红绿灯和距离，例：60=距离红绿灯60米";
CM_ SG_ 1120 NavIsTimeSpeedLimit "0:默认值或没有时间限速, 
1:有时间限速,但未满足时间条件(NavSpeedLimit_EV为原限速)
2:有时间限速,且满足时间条件(NavSpeedLimit_EV为时间限速)
3:预留";
CM_ SG_ 1120 NavRoundaboutsDist "当前到下一个环岛的距离
（暂定最大值1000米，以梦擎实际外发的最大距离为准）";
CM_ SG_ 1120 NavInRoundabout "0：默认值&不在圆环&其他情况 
1：在圆环内";
CM_ SG_ 1120 NavSpeedLimitIsUnknown "0:默认值
1:无限速数据
2:有限速数据（包含有限速和德国不限速）
3:预留";
CM_ SG_ 1120 NavIsVariableSpeedLimit "0：默认值or不是可变限速
1：当前道路是可变限速";
CM_ SG_ 1120 NavVSLExitEnterDist "距离可变限速开始或结束位置的距离(单位:米).取值范围[0,100];默认值或超出范围:0";
CM_ SG_ 1120 NavInRestzone "0：默认值&不在服务区&其他情况
1：在服务区内";
CM_ SG_ 1120 AdasSignDistance "标牌距离";
CM_ SG_ 1388 IHU_34_GPSLongitudeinfo "经度";
CM_ SG_ 1388 IHU_34_GPSHDOP "水平精度质量因子";
CM_ SG_ 1388 IHU_34_GPSLongitudesign "东经或西经";
CM_ SG_ 1388 IHU_34_MsgCntr "Rolling message counter(the maximum value of Alive counter is 15)
Note: Details Please refer to specification《EE Standard Specification for CAN FD Network Implementation》section 2.3.1";
CM_ SG_ 1388 IHU_34_CRC "CRC (SAE J1850 CRC-8)
Note: Details Please refer to specification《EE Standard Specification for CAN FD Network Implementation》section 2.3.2";
CM_ SG_ 1403 IHU_35_GPSLatitudeinfo "纬度";
CM_ SG_ 1403 IHU_35_GPSnum "卫星数量";
CM_ SG_ 1403 IHU_35_GPSLatitudesign "北纬或南纬";
CM_ SG_ 1403 IHU_35_MsgCntr "Rolling message counter(the maximum value of Alive counter is 15)
Note: Details Please refer to specification《EE Standard Specification for CAN FD Network Implementation》section 2.3.1";
CM_ SG_ 1403 IHU_35_CRC "CRC (SAE J1850 CRC-8)
Note: Details Please refer to specification《EE Standard Specification for CAN FD Network Implementation》section 2.3.2";
CM_ SG_ 1441 IHU_40_IDSSwtSet "通过DVD设置IDS功能开关";
CM_ SG_ 1441 IHU_40_WSOSSwtSet "通过DVD设置WSOS功能开关";
CM_ SG_ 62 VCU_2_CRC1 "CRC (SAE J1850 CRC-8) Note: Details Please refer to specification《EE Standard Specification for CAN FD Network Implementation》section 2.3.2";
CM_ SG_ 62 VCU_2_RollgCntr1 "Rolling message counter(the maximum value of Alive counter is 15) Note: Details Please refer to specification《EE Standard Specification for CAN FD Network Implementation》section 2.3.1";
CM_ SG_ 62 VCU_2_Resd1 "Reserved";
CM_ SG_ 62 VCU_MinActualWheelTorque "最小轮端扭矩";
CM_ SG_ 62 VCU_2_CRC2 "CRC (SAE J1850 CRC-8) Note: Details Please refer to specification《EE Standard Specification for CAN FD Network Implementation》section 2.3.2";
CM_ SG_ 62 VCU_2_RollgCntr2 "Rolling message counter(the maximum value of Alive counter is 15) Note: Details Please refer to specification《EE Standard Specification for CAN FD Network Implementation》section 2.3.1";
CM_ SG_ 62 VCU_2_Resd2 "Reserved";
CM_ SG_ 62 VCU_MaxActualWheelTorque "最大轮端扭矩";
CM_ SG_ 62 VCU_2_CRC3 "CRC (SAE J1850 CRC-8) Note: Details Please refer to specification《EE Standard Specification for CAN FD Network Implementation》section 2.3.2";
CM_ SG_ 62 VCU_2_RollgCntr3 "Rolling message counter(the maximum value of Alive counter is 15) Note: Details Please refer to specification《EE Standard Specification for CAN FD Network Implementation》section 2.3.1";
CM_ SG_ 62 VCU_2_Resd3 "Reserved";
CM_ SG_ 62 VCU_GasPedalPosition "Driver/Cruise control
This signal including compositive informations which are actual gas pedal position and dummy Cruise control gas pedal position";
CM_ SG_ 62 VCU_2_CRC4 "CRC (SAE J1850 CRC-8) Note: Details Please refer to specification《EE Standard Specification for CAN FD Network Implementation》section 2.3.2";
CM_ SG_ 62 VCU_2_RollgCntr4 "Rolling message counter(the maximum value of Alive counter is 15) Note: Details Please refer to specification《EE Standard Specification for CAN FD Network Implementation》section 2.3.1";
CM_ SG_ 62 VCU_PTReady "PT Ready indication";
CM_ SG_ 62 VCU_2_Resd4 "Reserved";
CM_ SG_ 62 VCU_TargetGear "Target gear";
CM_ SG_ 62 VCU_ActualGear "actual gear";
CM_ SG_ 62 VCU_TargetGearValidData "valid Target gear";
CM_ SG_ 62 VCU_ActualGearValidData "valid actual gear";
CM_ SG_ 62 VCU_LimitSpeedSts "主动限速状态，用于和ACC功能互斥";
CM_ SG_ 1261 VCU_LowSOCCLMLimitSts "power limitation CLM";
CM_ SG_ 1261 VCU_VehicleSystemFailure "vehicle system failure";
CM_ SG_ 1261 VCU_6_MsgCounter "Alivecounter";
CM_ SG_ 1261 VCU_6_CRC "SAE J1850 CRC-8";
CM_ SG_ 295 YAS_CalibrationSts "Indicates  IMU Calibration State";
CM_ SG_ 295 YawrateSigValidData "Signal state for yawrate";
CM_ SG_ 295 LateralAccelerationSigValidData "If hasn’t been calibrated, after initialization, this signal ‘s value is always 10(invalid).";
CM_ SG_ 295 LateralAcceleration "横向加速度信号
传感器精度：0.0027680342857143g";
CM_ SG_ 295 YawRate "偏航角速度信号                传感器精度：0.122189236 deg/s";
CM_ SG_ 295 YAS_1_Checksum "0x01 XOR 0x27 XOR Byte0 XOR Byte1 XOR Byte2 XOR Byte3 XOR Byte4 XOR Byte5 XOR Byte6";
CM_ SG_ 296 LongitudinalAccelerationSigValid "If hasn’t been calibrated, after initialization, this signal ‘s value is always10(invalid)";
CM_ SG_ 296 LongitudinalAcceleration "纵向加速度信号
传感器精度：0.0027680342857143 g";
CM_ SG_ 296 YAS_2_Checksum "0x01 XOR 0x28 XOR Byte0 XOR Byte1 XOR Byte2 XOR Byte3 XOR Byte4 XOR Byte5 XOR Byte6";

BA_DEF_ BO_  "DiagState" ENUM  "No","Yes";
BA_DEF_ BO_  "GenMsgSendType" ENUM  "Cyclic","Event","IfActive","CE","CA","NoMsgSendType";
BA_DEF_ BO_  "GenMsgCycleTime" INT 0 0;
BA_DEF_ SG_  "GenSigSendType" ENUM  "Cyclic","OnChange","OnWrite","IfActive","OnChangeWithRepetition","OnWriteWithRepetition","IfActiveWithRepetition","NoSigSendType","OnChangeAndIfActive","OnChangeAndIfActiveWithRepetition","CA","CE","Event";
BA_DEF_ SG_  "GenSigStartValue" INT 0 0;
BA_DEF_ BO_  "GenMsgCycleTimeFast" INT 0 0;
BA_DEF_ BO_  "GenMsgNrOfRepetition" INT 0 0;
BA_DEF_ BO_  "GenMsgDelayTime" INT 0 0;
BA_DEF_ BO_  "CANFD_BRS" ENUM  "0","1";
BA_DEF_ BO_  "VFrameFormat" ENUM  "StandardCAN","ExtendedCAN","reserved","reserved","reserved","reserved","reserved","reserved","reserved","reserved","reserved","reserved","reserved","reserved","StandardCAN_FD","ExtendedCAN_FD";
BA_DEF_ BO_  "GenMsgILSupport" ENUM  "No","Yes";
BA_DEF_ SG_ "GenSigASIL" ENUM "QM","A","B","C","D","";
BA_DEF_DEF_  "DiagState" "No";
BA_DEF_DEF_  "GenMsgSendType" "Cyclic";
BA_DEF_DEF_  "GenMsgCycleTime" 0;
BA_DEF_DEF_  "GenSigSendType" "Cyclic";
BA_DEF_DEF_  "GenSigStartValue" 0;
BA_DEF_DEF_  "GenMsgCycleTimeFast" 0;
BA_DEF_DEF_  "GenMsgNrOfRepetition" 0;
BA_DEF_DEF_  "GenMsgDelayTime" 0;
BA_DEF_DEF_  "CANFD_BRS" "1";
BA_DEF_DEF_  "VFrameFormat" "StandardCAN_FD";
BA_DEF_DEF_  "GenMsgILSupport" "No";
BA_DEF_DEF_ "GenSigASIL" "QM";
BA_ "GenMsgILSupport" BO_ 969 1;
BA_ "GenMsgCycleTime" BO_ 969 50;
BA_ "GenSigASIL"  SG_ 969 RRCR_3_Ri2ObjBoxLen 5;
BA_ "GenSigASIL"  SG_ 969 RRCR_3_Ri2ObjBoxWidth 5;
BA_ "GenSigStartValue" SG_ 969 RRCR_3_Ri2HdTo 1800;
BA_ "GenSigASIL"  SG_ 969 RRCR_3_Ri2HdTo 5;
BA_ "GenSigASIL"  SG_ 969 RRCR_3_Ri2ObjID 5;
BA_ "GenSigStartValue" SG_ 969 RRCR_3_Ri2ObjCoordY 4000;
BA_ "GenSigASIL"  SG_ 969 RRCR_3_Ri2ObjCoordY 5;
BA_ "GenSigStartValue" SG_ 969 RRCR_3_Ri2ObjCoordX 4000;
BA_ "GenSigASIL"  SG_ 969 RRCR_3_Ri2ObjCoordX 5;
BA_ "GenSigStartValue" SG_ 969 RRCR_3_Ri2ObjXDirAV 128;
BA_ "GenSigASIL"  SG_ 969 RRCR_3_Ri2ObjXDirAV 5;
BA_ "GenSigStartValue" SG_ 969 RRCR_3_Ri2ObjYDirV 6400;
BA_ "GenSigASIL"  SG_ 969 RRCR_3_Ri2ObjYDirV 5;
BA_ "GenSigStartValue" SG_ 969 RRCR_3_Ri2ObjXDirV 6400;
BA_ "GenSigASIL"  SG_ 969 RRCR_3_Ri2ObjXDirV 5;
BA_ "GenSigASIL"  SG_ 969 RRCR_3_Ri2ObjMtnChartc 5;
BA_ "GenSigASIL"  SG_ 969 RRCR_3_Ri2ObjTyp 5;
BA_ "GenSigASIL"  SG_ 969 RRCR_3_Ri2ObjConf 5;
BA_ "GenSigStartValue" SG_ 969 RRCR_3_Ri2ObjNrOffocst 31;
BA_ "GenSigASIL"  SG_ 969 RRCR_3_Ri2ObjNrOffocst 5;
BA_ "GenSigASIL"  SG_ 969 RRCR_3_Ri2ObjTrackSt 5;
BA_ "GenSigASIL"  SG_ 969 RRCR_3_Ri2ObjCoordXDstStdDe 5;
BA_ "GenSigASIL"  SG_ 969 RRCR_3_Ri2ObjCoordYDstStdDe 5;
BA_ "GenSigASIL"  SG_ 969 RRCR_3_Ri2ObjXDirVStdDe 5;
BA_ "GenSigASIL"  SG_ 969 RRCR_3_Ri2ObjYDirVStdDe 5;
BA_ "GenSigASIL"  SG_ 969 RRCR_3_MsgCntr 5;
BA_ "GenSigASIL"  SG_ 969 RRCR_3_CRC 5;
BA_ "GenMsgILSupport" BO_ 976 1;
BA_ "GenMsgCycleTime" BO_ 976 50;
BA_ "GenSigASIL"  SG_ 976 RRCR_4_Ri3ObjBoxLen 5;
BA_ "GenSigASIL"  SG_ 976 RRCR_4_Ri3ObjBoxWidth 5;
BA_ "GenSigStartValue" SG_ 976 RRCR_4_Ri3HdTo 1800;
BA_ "GenSigASIL"  SG_ 976 RRCR_4_Ri3HdTo 5;
BA_ "GenSigASIL"  SG_ 976 RRCR_4_Ri3ObjID 5;
BA_ "GenSigStartValue" SG_ 976 RRCR_4_Ri3ObjCoordY 4000;
BA_ "GenSigASIL"  SG_ 976 RRCR_4_Ri3ObjCoordY 5;
BA_ "GenSigStartValue" SG_ 976 RRCR_4_Ri3ObjCoordX 4000;
BA_ "GenSigASIL"  SG_ 976 RRCR_4_Ri3ObjCoordX 5;
BA_ "GenSigStartValue" SG_ 976 RRCR_4_Ri3ObjXDirAV 128;
BA_ "GenSigASIL"  SG_ 976 RRCR_4_Ri3ObjXDirAV 5;
BA_ "GenSigStartValue" SG_ 976 RRCR_4_Ri3ObjYDirV 6400;
BA_ "GenSigASIL"  SG_ 976 RRCR_4_Ri3ObjYDirV 5;
BA_ "GenSigStartValue" SG_ 976 RRCR_4_Ri3ObjXDirV 6400;
BA_ "GenSigASIL"  SG_ 976 RRCR_4_Ri3ObjXDirV 5;
BA_ "GenSigASIL"  SG_ 976 RRCR_4_Ri3ObjMtnChartc 5;
BA_ "GenSigASIL"  SG_ 976 RRCR_4_Ri3ObjTyp 5;
BA_ "GenSigASIL"  SG_ 976 RRCR_4_Ri3ObjConf 5;
BA_ "GenSigStartValue" SG_ 976 RRCR_4_Ri3ObjNrOffocst 31;
BA_ "GenSigASIL"  SG_ 976 RRCR_4_Ri3ObjNrOffocst 5;
BA_ "GenSigASIL"  SG_ 976 RRCR_4_Ri3ObjTrackSt 5;
BA_ "GenSigASIL"  SG_ 976 RRCR_4_Ri3ObjCoordXDstStdDe 5;
BA_ "GenSigASIL"  SG_ 976 RRCR_4_Ri3ObjCoordYDstStdDe 5;
BA_ "GenSigASIL"  SG_ 976 RRCR_4_Ri3ObjXDirVStdDe 5;
BA_ "GenSigASIL"  SG_ 976 RRCR_4_Ri3ObjYDirVStdDe 5;
BA_ "GenSigASIL"  SG_ 976 RRCR_4_MsgCntr 5;
BA_ "GenSigASIL"  SG_ 976 RRCR_4_CRC 5;
BA_ "GenMsgILSupport" BO_ 984 1;
BA_ "GenMsgCycleTime" BO_ 984 50;
BA_ "GenSigASIL"  SG_ 984 RRCR_5_Ri4ObjBoxLen 5;
BA_ "GenSigASIL"  SG_ 984 RRCR_5_Ri4ObjBoxWidth 5;
BA_ "GenSigStartValue" SG_ 984 RRCR_5_Ri4HdTo 1800;
BA_ "GenSigASIL"  SG_ 984 RRCR_5_Ri4HdTo 5;
BA_ "GenSigASIL"  SG_ 984 RRCR_5_Ri4ObjID 5;
BA_ "GenSigStartValue" SG_ 984 RRCR_5_Ri4ObjCoordY 4000;
BA_ "GenSigASIL"  SG_ 984 RRCR_5_Ri4ObjCoordY 5;
BA_ "GenSigStartValue" SG_ 984 RRCR_5_Ri4ObjCoordX 4000;
BA_ "GenSigASIL"  SG_ 984 RRCR_5_Ri4ObjCoordX 5;
BA_ "GenSigStartValue" SG_ 984 RRCR_5_Ri4ObjXDirAV 128;
BA_ "GenSigASIL"  SG_ 984 RRCR_5_Ri4ObjXDirAV 5;
BA_ "GenSigStartValue" SG_ 984 RRCR_5_Ri4ObjYDirV 6400;
BA_ "GenSigASIL"  SG_ 984 RRCR_5_Ri4ObjYDirV 5;
BA_ "GenSigStartValue" SG_ 984 RRCR_5_Ri4ObjXDirV 6400;
BA_ "GenSigASIL"  SG_ 984 RRCR_5_Ri4ObjXDirV 5;
BA_ "GenSigASIL"  SG_ 984 RRCR_5_Ri4ObjMtnChartc 5;
BA_ "GenSigASIL"  SG_ 984 RRCR_5_Ri4ObjTyp 5;
BA_ "GenSigASIL"  SG_ 984 RRCR_5_Ri4ObjConf 5;
BA_ "GenSigStartValue" SG_ 984 RRCR_5_Ri4ObjNrOffocst 31;
BA_ "GenSigASIL"  SG_ 984 RRCR_5_Ri4ObjNrOffocst 5;
BA_ "GenSigASIL"  SG_ 984 RRCR_5_Ri4ObjTrackSt 5;
BA_ "GenSigASIL"  SG_ 984 RRCR_5_Ri4ObjCoordXDstStdDe 5;
BA_ "GenSigASIL"  SG_ 984 RRCR_5_Ri4ObjCoordYDstStdDe 5;
BA_ "GenSigASIL"  SG_ 984 RRCR_5_Ri4ObjXDirVStdDe 5;
BA_ "GenSigASIL"  SG_ 984 RRCR_5_Ri4ObjYDirVStdDe 5;
BA_ "GenSigASIL"  SG_ 984 RRCR_5_MsgCntr 5;
BA_ "GenSigASIL"  SG_ 984 RRCR_5_CRC 5;
BA_ "GenMsgILSupport" BO_ 986 1;
BA_ "GenMsgCycleTime" BO_ 986 50;
BA_ "GenSigASIL"  SG_ 986 RRCR_6_Ri5ObjBoxLen 5;
BA_ "GenSigASIL"  SG_ 986 RRCR_6_Ri5ObjBoxWidth 5;
BA_ "GenSigStartValue" SG_ 986 RRCR_6_Ri5HdTo 1800;
BA_ "GenSigASIL"  SG_ 986 RRCR_6_Ri5HdTo 5;
BA_ "GenSigASIL"  SG_ 986 RRCR_6_Ri5ObjID 5;
BA_ "GenSigStartValue" SG_ 986 RRCR_6_Ri5ObjCoordY 4000;
BA_ "GenSigASIL"  SG_ 986 RRCR_6_Ri5ObjCoordY 5;
BA_ "GenSigStartValue" SG_ 986 RRCR_6_Ri5ObjCoordX 4000;
BA_ "GenSigASIL"  SG_ 986 RRCR_6_Ri5ObjCoordX 5;
BA_ "GenSigStartValue" SG_ 986 RRCR_6_Ri5ObjXDirAV 128;
BA_ "GenSigASIL"  SG_ 986 RRCR_6_Ri5ObjXDirAV 5;
BA_ "GenSigStartValue" SG_ 986 RRCR_6_Ri5ObjYDirV 6400;
BA_ "GenSigASIL"  SG_ 986 RRCR_6_Ri5ObjYDirV 5;
BA_ "GenSigStartValue" SG_ 986 RRCR_6_Ri5ObjXDirV 6400;
BA_ "GenSigASIL"  SG_ 986 RRCR_6_Ri5ObjXDirV 5;
BA_ "GenSigASIL"  SG_ 986 RRCR_6_Ri5ObjMtnChartc 5;
BA_ "GenSigASIL"  SG_ 986 RRCR_6_Ri5ObjTyp 5;
BA_ "GenSigASIL"  SG_ 986 RRCR_6_Ri5ObjConf 5;
BA_ "GenSigStartValue" SG_ 986 RRCR_6_Ri5ObjNrOffocst 31;
BA_ "GenSigASIL"  SG_ 986 RRCR_6_Ri5ObjNrOffocst 5;
BA_ "GenSigASIL"  SG_ 986 RRCR_6_Ri5ObjTrackSt 5;
BA_ "GenSigASIL"  SG_ 986 RRCR_6_Ri5ObjCoordXDstStdDe 5;
BA_ "GenSigASIL"  SG_ 986 RRCR_6_Ri5ObjCoordYDstStdDe 5;
BA_ "GenSigASIL"  SG_ 986 RRCR_6_Ri5ObjXDirVStdDe 5;
BA_ "GenSigASIL"  SG_ 986 RRCR_6_Ri5ObjYDirVStdDe 5;
BA_ "GenSigASIL"  SG_ 986 RRCR_6_MsgCntr 5;
BA_ "GenSigASIL"  SG_ 986 RRCR_6_CRC 5;
BA_ "GenMsgILSupport" BO_ 992 1;
BA_ "GenMsgCycleTime" BO_ 992 50;
BA_ "GenSigASIL"  SG_ 992 RRCR_7_TiStampLaten 5;
BA_ "GenSigASIL"  SG_ 992 RRCR_7_MsgCntr 5;
BA_ "GenSigASIL"  SG_ 992 RRCR_7_CRC 5;
BA_ "GenMsgILSupport" BO_ 994 1;
BA_ "GenMsgCycleTime" BO_ 994 50;
BA_ "GenSigASIL"  SG_ 994 RRCR_8_ObjVldFlg 5;
BA_ "GenSigStartValue" SG_ 994 RRCR_8_LgtDst 4000;
BA_ "GenSigASIL"  SG_ 994 RRCR_8_LgtDst 5;
BA_ "GenSigStartValue" SG_ 994 RRCR_8_LgtRelV 6400;
BA_ "GenSigASIL"  SG_ 994 RRCR_8_LgtRelV 5;
BA_ "GenSigASIL"  SG_ 994 RRCR_8_MsgCntr 5;
BA_ "GenSigASIL"  SG_ 994 RRCR_8_CRC 5;
BA_ "GenMsgSendType" BO_ 1785 5;
BA_ "GenSigSendType" SG_ 1785 XCP_FCM_RES 2;
BA_ "GenSigASIL"  SG_ 1785 XCP_FCM_RES 5;
BA_ "GenMsgSendType" BO_ 1854 5;
BA_ "GenSigSendType" SG_ 1854 Diag_FCM_RES 2;
BA_ "GenSigASIL"  SG_ 1854 Diag_FCM_RES 5;
BA_ "GenMsgILSupport" BO_ 745 1;
BA_ "GenMsgCycleTime" BO_ 745 10;
BA_ "GenSigASIL"  SG_ 745 ABS_ESP_1_EBDFailSts 5;
BA_ "GenSigASIL"  SG_ 745 ABS_ESP_1_ABSFailSts 5;
BA_ "GenSigASIL"  SG_ 745 ABS_ESP_1_ABSActive 5;
BA_ "GenSigASIL"  SG_ 745 ABS_ESP_1_VDCFailSts 5;
BA_ "GenSigASIL"  SG_ 745 ABS_ESP_1_VDCActive 5;
BA_ "GenSigASIL"  SG_ 745 ABS_ESP_1_TCSFailSts 5;
BA_ "GenSigASIL"  SG_ 745 ABS_ESP_1_TCSActive 5;
BA_ "GenSigASIL"  SG_ 745 ABS_ESP_1_PressureMasterCylinder 5;
BA_ "GenSigStartValue" SG_ 745 ESP1_PressureMasCylindValidData 1;
BA_ "GenSigASIL"  SG_ 745 ESP1_PressureMasCylindValidData 5;
BA_ "GenSigStartValue" SG_ 745 ESP1_VehicleSpeedVSOSigValidData 1;
BA_ "GenSigASIL"  SG_ 745 ESP1_VehicleSpeedVSOSigValidData 5;
BA_ "GenSigASIL"  SG_ 745 ABS_ESP_1_VehicleSpeedVSOSig 5;
BA_ "GenSigASIL"  SG_ 745 ABS_ESP_1_Checksum 5;
BA_ "GenSigASIL"  SG_ 745 ABS_ESP_1_HDCCtrlSts 5;
BA_ "GenSigASIL"  SG_ 745 ABS_ESP_1_HDCFailSts 5;
BA_ "GenSigASIL"  SG_ 745 ABS_ESP_1_MessageCounter 5;
BA_ "GenSigASIL"  SG_ 745 ABS_ESP_1_ESPSwitchStatus 5;
BA_ "GenSigASIL"  SG_ 745 SwitchOffCruiseControl 5;
BA_ "GenMsgILSupport" BO_ 787 1;
BA_ "GenMsgCycleTime" BO_ 787 20;
BA_ "GenSigStartValue" SG_ 787 NoBrakeForce 1;
BA_ "GenSigASIL"  SG_ 787 NoBrakeForce 5;
BA_ "GenSigASIL"  SG_ 787 ABS_ESP_3_AVHFailSts 5;
BA_ "GenSigASIL"  SG_ 787 ABS_ESP_3_AVHSts 5;
BA_ "GenSigASIL"  SG_ 787 ABS_ESP_3_MessageCounter 5;
BA_ "GenSigASIL"  SG_ 787 ABS_ESP_3_Checksum 5;
BA_ "GenMsgILSupport" BO_ 790 1;
BA_ "GenMsgCycleTime" BO_ 790 20;
BA_ "GenSigStartValue" SG_ 790 VLC_InternalTargetAcceleration 140;
BA_ "GenSigASIL"  SG_ 790 VLC_InternalTargetAcceleration 5;
BA_ "GenSigASIL"  SG_ 790 VehicleStandstill 5;
BA_ "GenSigASIL"  SG_ 790 AWBactive 5;
BA_ "GenSigASIL"  SG_ 790 AWBavailable 5;
BA_ "GenSigASIL"  SG_ 790 ECDTempOff 5;
BA_ "GenSigASIL"  SG_ 790 DCFail 5;
BA_ "GenSigASIL"  SG_ 790 VLC_Active 5;
BA_ "GenSigASIL"  SG_ 790 VLC_Available 5;
BA_ "GenSigASIL"  SG_ 790 CDDActive 5;
BA_ "GenSigASIL"  SG_ 790 CDDAvailable 5;
BA_ "GenSigASIL"  SG_ 790 ABAactive 5;
BA_ "GenSigASIL"  SG_ 790 ABAavailable 5;
BA_ "GenSigASIL"  SG_ 790 ABS_ESP_4_MessageCounter 5;
BA_ "GenSigASIL"  SG_ 790 ABS_ESP_4_Checksum 5;
BA_ "GenMsgILSupport" BO_ 608 1;
BA_ "GenMsgCycleTime" BO_ 608 20;
BA_ "GenSigASIL"  SG_ 608 LHFWheelSpeedRaw 5;
BA_ "GenSigASIL"  SG_ 608 LHFWheelDriveDirection 5;
BA_ "GenSigStartValue" SG_ 608 LHFWheelSpeedRawValidData 1;
BA_ "GenSigASIL"  SG_ 608 LHFWheelSpeedRawValidData 5;
BA_ "GenSigASIL"  SG_ 608 RHFWheelSpeedRaw 5;
BA_ "GenSigASIL"  SG_ 608 RHFWheelDriveDirection 5;
BA_ "GenSigStartValue" SG_ 608 RHFWheelSpeedRawValidData 1;
BA_ "GenSigASIL"  SG_ 608 RHFWheelSpeedRawValidData 5;
BA_ "GenSigASIL"  SG_ 608 QDCACC 5;
BA_ "GenSigStartValue" SG_ 608 VLCFail 1;
BA_ "GenSigASIL"  SG_ 608 VLCFail 5;
BA_ "GenSigStartValue" SG_ 608 WheelBrakeForce 31250;
BA_ "GenSigASIL"  SG_ 608 WheelBrakeForce 5;
BA_ "GenSigASIL"  SG_ 608 ABSESP_7_MessageCounter 5;
BA_ "GenSigASIL"  SG_ 608 ABSESP_7_Checksum 5;
BA_ "GenMsgILSupport" BO_ 641 1;
BA_ "GenMsgCycleTime" BO_ 641 20;
BA_ "GenSigASIL"  SG_ 641 LHRWheelSpeedRaw 5;
BA_ "GenSigASIL"  SG_ 641 LHRWheelDriveDirection 5;
BA_ "GenSigStartValue" SG_ 641 LHRWheelSpeedRawValidData 1;
BA_ "GenSigASIL"  SG_ 641 LHRWheelSpeedRawValidData 5;
BA_ "GenSigASIL"  SG_ 641 RHRWheelSpeedRaw 5;
BA_ "GenSigASIL"  SG_ 641 RHRWheelDriveDirection 5;
BA_ "GenSigStartValue" SG_ 641 RHRWheelSpeedRawValidData 1;
BA_ "GenSigASIL"  SG_ 641 RHRWheelSpeedRawValidData 5;
BA_ "GenSigASIL"  SG_ 641 ABPActive 5;
BA_ "GenSigASIL"  SG_ 641 ABPAvailable 5;
BA_ "GenSigASIL"  SG_ 641 AEBdecActive 5;
BA_ "GenSigASIL"  SG_ 641 AEBdecAvailable 5;
BA_ "GenSigASIL"  SG_ 641 ABSESP_8_MessageCounter 5;
BA_ "GenSigASIL"  SG_ 641 ABSESP_8_Checksum 5;
BA_ "GenMsgILSupport" BO_ 1282 1;
BA_ "GenMsgCycleTime" BO_ 1282 100;
BA_ "GenSigASIL"  SG_ 1282 CDPActive 5;
BA_ "GenMsgILSupport" BO_ 913 1;
BA_ "GenMsgCycleTime" BO_ 913 20;
BA_ "GenSigASIL"  SG_ 913 RHTurnlightSts 5;
BA_ "GenSigASIL"  SG_ 913 LHTurnlightSts 5;
BA_ "GenSigASIL"  SG_ 913 HighBeamSts 5;
BA_ "GenSigASIL"  SG_ 913 LowBeamSts 5;
BA_ "GenSigASIL"  SG_ 913 KeySts 5;
BA_ "GenSigASIL"  SG_ 913 BCM_1_Checksum 5;
BA_ "GenSigASIL"  SG_ 913 DirectionIndRight 5;
BA_ "GenSigASIL"  SG_ 913 DirectionIndLeft 5;
BA_ "GenSigASIL"  SG_ 913 HazardLightSW 5;
BA_ "GenSigASIL"  SG_ 913 AutoLightSW 5;
BA_ "GenSigASIL"  SG_ 913 FGHeat_Request_CommandFeedback 5;
BA_ "GenSigStartValue" SG_ 913 DriverDoorLockSts 1;
BA_ "GenSigASIL"  SG_ 913 DriverDoorLockSts 5;
BA_ "GenSigASIL"  SG_ 913 DriverDoorSts 5;
BA_ "GenSigASIL"  SG_ 913 PsngrDoorSts 5;
BA_ "GenSigASIL"  SG_ 913 HoodSts 5;
BA_ "GenSigASIL"  SG_ 913 RHRDoorSts 5;
BA_ "GenSigASIL"  SG_ 913 LHRdoorSts 5;
BA_ "GenSigASIL"  SG_ 913 TrunkSts 5;
BA_ "GenSigASIL"  SG_ 913 DriverDoorStsQbit 5;
BA_ "GenSigASIL"  SG_ 913 HMASW 5;
BA_ "GenSigASIL"  SG_ 913 RearFogLightSts 5;
BA_ "GenSigASIL"  SG_ 913 ReverseGearSts 5;
BA_ "GenSigASIL"  SG_ 913 FrontFogLightSts 5;
BA_ "GenSigASIL"  SG_ 913 HighBeamSWSts 5;
BA_ "GenSigASIL"  SG_ 913 FlashSWSts 5;
BA_ "GenSigASIL"  SG_ 913 LHTurnSW 5;
BA_ "GenSigASIL"  SG_ 913 RHTurnSW 5;
BA_ "GenSigASIL"  SG_ 913 WiperSts 5;
BA_ "GenSigASIL"  SG_ 913 RainDetected 5;
BA_ "GenSigASIL"  SG_ 913 AutoHighSpeedRequest 5;
BA_ "GenSigASIL"  SG_ 913 BCM_1_MessageCounter 5;
BA_ "GenMsgILSupport" BO_ 1077 1;
BA_ "GenMsgCycleTime" BO_ 1077 100;
BA_ "GenSigASIL"  SG_ 1077 TrailerConnectSts 5;
BA_ "GenMsgILSupport" BO_ 1333 1;
BA_ "GenMsgCycleTime" BO_ 1333 100;
BA_ "GenSigASIL"  SG_ 1333 CLM2_AliveCounter 5;
BA_ "GenSigASIL"  SG_ 1333 CLM2_ExternalTempFailSts 5;
BA_ "GenSigStartValue" SG_ 1333 CLM2_ExternalTemperature_C 254;
BA_ "GenSigASIL"  SG_ 1333 CLM2_ExternalTemperature_C 5;
BA_ "GenSigASIL"  SG_ 1333 CLM2_CRC 5;
BA_ "GenMsgILSupport" BO_ 1039 1;
BA_ "GenMsgCycleTime" BO_ 1039 100;
BA_ "GenSigASIL"  SG_ 1039 DMS_1_DMSSt 5;
BA_ "GenSigASIL"  SG_ 1039 DMS_1_CameraSt 5;
BA_ "GenSigASIL"  SG_ 1039 DMS_1_DriverSts 5;
BA_ "GenSigASIL"  SG_ 1039 DMS_1_MessageCounter 5;
BA_ "GenSigASIL"  SG_ 1039 DMS_1_CRC 5;
BA_ "GenMsgILSupport" BO_ 250 1;
BA_ "GenMsgCycleTime" BO_ 250 10;
BA_ "GenSigASIL"  SG_ 250 EMS1_EngineSpeed 5;
BA_ "GenSigASIL"  SG_ 250 EMS_1_Checksum 5;
BA_ "GenSigASIL"  SG_ 250 CruiseControlStatus 5;
BA_ "GenSigASIL"  SG_ 250 AcceleratorPosRaw 5;
BA_ "GenSigASIL"  SG_ 250 NeutralGearSts 5;
BA_ "GenSigASIL"  SG_ 250 ECFail 5;
BA_ "GenSigASIL"  SG_ 250 ECGPOvrd 5;
BA_ "GenSigASIL"  SG_ 250 EMS_1_MessageCounter 5;
BA_ "GenMsgILSupport" BO_ 257 1;
BA_ "GenMsgCycleTime" BO_ 257 10;
BA_ "GenSigASIL"  SG_ 257 BrakePedalStsValidDataForTCU 5;
BA_ "GenSigASIL"  SG_ 257 BrakePedalStsForTCU 5;
BA_ "GenSigASIL"  SG_ 257 EngineStsForDCT 5;
BA_ "GenMsgILSupport" BO_ 705 1;
BA_ "GenMsgCycleTime" BO_ 705 10;
BA_ "GenSigASIL"  SG_ 705 SSMStatus 5;
BA_ "GenSigASIL"  SG_ 705 EMS_3_MessageCounter 5;
BA_ "GenSigASIL"  SG_ 705 EMS_3_Checksum 5;
BA_ "GenMsgILSupport" BO_ 259 1;
BA_ "GenMsgCycleTime" BO_ 259 10;
BA_ "GenSigASIL"  SG_ 259 ECGPOvrd 5;
BA_ "GenSigASIL"  SG_ 259 ECGPOvrdInvalidData 5;
BA_ "GenSigASIL"  SG_ 259 BrakePedalStsValidDataForTCU 5;
BA_ "GenSigASIL"  SG_ 259 BrakePedalStsForTCU 5;
BA_ "GenSigASIL"  SG_ 259 EMS6_MessageCounter 5;
BA_ "GenSigASIL"  SG_ 259 EMS6_CRC 5;
BA_ "GenMsgILSupport" BO_ 1057 1;
BA_ "GenMsgCycleTime" BO_ 1057 100;
BA_ "GenSigASIL"  SG_ 1057 LimitSpeedSts 5;
BA_ "GenSigASIL"  SG_ 1057 GasPedalPosition 5;
BA_ "GenSigASIL"  SG_ 1057 GasPedalPositionInvalidData 5;
BA_ "GenSigASIL"  SG_ 1057 EMS_2_G_MessageCounter 5;
BA_ "GenSigASIL"  SG_ 1057 EMS_2_G_CRC 5;
BA_ "GenMsgILSupport" BO_ 1270 1;
BA_ "GenMsgCycleTime" BO_ 1270 100;
BA_ "GenSigASIL"  SG_ 1270 EPBErrorStatus 5;
BA_ "GenSigStartValue" SG_ 1270 EPBStatus 4;
BA_ "GenSigASIL"  SG_ 1270 EPBStatus 5;
BA_ "GenSigASIL"  SG_ 1270 RWUActive 5;
BA_ "GenMsgILSupport" BO_ 1285 1;
BA_ "GenMsgCycleTime" BO_ 1285 100;
BA_ "GenSigASIL"  SG_ 1285 EPSFailSts 5;
BA_ "GenSigASIL"  SG_ 1285 EPSSteeringAngleCalibrationSts 5;
BA_ "GenSigASIL"  SG_ 1285 EPS_AssistanceStyle_Sts 5;
BA_ "GenMsgILSupport" BO_ 916 1;
BA_ "GenMsgCycleTime" BO_ 916 20;
BA_ "GenSigASIL"  SG_ 916 TorsionBarTorque 5;
BA_ "GenSigASIL"  SG_ 916 TorsionBarTorqueDir 5;
BA_ "GenSigASIL"  SG_ 916 TosionBarTorqueValid 5;
BA_ "GenSigASIL"  SG_ 916 EpsControlStatus 5;
BA_ "GenSigASIL"  SG_ 916 EPS_2_Message_Counter 5;
BA_ "GenSigASIL"  SG_ 916 EPS_2_CRC 5;
BA_ "GenMsgILSupport" BO_ 467 1;
BA_ "GenMsgCycleTime" BO_ 467 10;
BA_ "GenSigStartValue" SG_ 467 EPS_3_StrngWhlAg 7800;
BA_ "GenSigASIL"  SG_ 467 EPS_3_StrngWhlAg 5;
BA_ "GenSigASIL"  SG_ 467 EPS_3_StrngWhlAgValid 5;
BA_ "GenSigStartValue" SG_ 467 EPS_3_StrngAgSpdValidData 1;
BA_ "GenSigASIL"  SG_ 467 EPS_3_StrngAgSpdValidData 5;
BA_ "GenSigStartValue" SG_ 467 EPS_3_StrngAgSpd 255;
BA_ "GenSigASIL"  SG_ 467 EPS_3_StrngAgSpd 5;
BA_ "GenSigASIL"  SG_ 467 EPS_3_AgFailr 5;
BA_ "GenSigASIL"  SG_ 467 EPS_3_Message_Counter 5;
BA_ "GenSigASIL"  SG_ 467 EPS_3_CRC 5;
BA_ "GenMsgILSupport" BO_ 483 1;
BA_ "GenMsgCycleTime" BO_ 483 10;
BA_ "GenSigASIL"  SG_ 483 EPS_4_LoASts 5;
BA_ "GenSigASIL"  SG_ 483 EPS_4_LatDrvgAvlForLvl 5;
BA_ "GenSigASIL"  SG_ 483 EPS_4_HptcVibSrvAvl 5;
BA_ "GenSigASIL"  SG_ 483 EPS_4_AgCtrlLimActvd 5;
BA_ "GenSigASIL"  SG_ 483 EPS_4_PSCMActRPCTrqValid 5;
BA_ "GenSigStartValue" SG_ 483 EPS_4_PSCMActRPCTrq 1024;
BA_ "GenSigASIL"  SG_ 483 EPS_4_PSCMActRPCTrq 5;
BA_ "GenSigStartValue" SG_ 483 EPS_4_MotorTorque 100;
BA_ "GenSigASIL"  SG_ 483 EPS_4_MotorTorque 5;
BA_ "GenSigASIL"  SG_ 483 EPS_4_StrngWhlAgResActive 5;
BA_ "GenSigASIL"  SG_ 483 EPS_4_ManMachineSharingSts 5;
BA_ "GenSigASIL"  SG_ 483 EPS_4_Message_Counter 5;
BA_ "GenSigASIL"  SG_ 483 EPS_4_CRC 5;
BA_ "GenMsgILSupport" BO_ 406 1;
BA_ "GenMsgCycleTime" BO_ 406 20;
BA_ "GenSigASIL"  SG_ 406 EPB_State_R_CRC1 5;
BA_ "GenSigASIL"  SG_ 406 EPB_State_R_RollgCntr1 5;
BA_ "GenSigASIL"  SG_ 406 EPB_FltLvl 5;
BA_ "GenSigStartValue" SG_ 406 EPBStatus 4;
BA_ "GenSigASIL"  SG_ 406 EPBStatus 5;
BA_ "GenMsgILSupport" BO_ 263 1;
BA_ "GenMsgCycleTime" BO_ 263 10;
BA_ "GenSigStartValue" SG_ 263 HCU_6_MaxTorqueWheel 32767;
BA_ "GenSigASIL"  SG_ 263 HCU_6_MaxTorqueWheel 5;
BA_ "GenSigStartValue" SG_ 263 HCU_6_MinTorqueWheel 32767;
BA_ "GenSigASIL"  SG_ 263 HCU_6_MinTorqueWheel 5;
BA_ "GenSigASIL"  SG_ 263 HCU_6_ECGPOvrd 5;
BA_ "GenSigASIL"  SG_ 263 HCU_6_ECGPOvrdInvalidData 5;
BA_ "GenSigASIL"  SG_ 263 HCU_BrakePedalStsValidDataForTCU 5;
BA_ "GenSigASIL"  SG_ 263 HCU_6_BrakePedalStsForTCU 5;
BA_ "GenSigASIL"  SG_ 263 HCU_6_MessageCounter 5;
BA_ "GenSigASIL"  SG_ 263 HCU_6_CRC 5;
BA_ "GenMsgILSupport" BO_ 269 1;
BA_ "GenMsgCycleTime" BO_ 269 10;
BA_ "GenSigASIL"  SG_ 269 PRNDGearAct 5;
BA_ "GenSigASIL"  SG_ 269 PRNDGearActValidData 5;
BA_ "GenSigASIL"  SG_ 269 PRNDGearTarget 5;
BA_ "GenSigASIL"  SG_ 269 HCU_17_MessageCounter 5;
BA_ "GenSigASIL"  SG_ 269 HCU_17_CRC 5;
BA_ "GenMsgILSupport" BO_ 1034 1;
BA_ "GenMsgCycleTime" BO_ 1034 100;
BA_ "GenSigASIL"  SG_ 1034 HCU_PTReady 5;
BA_ "GenSigASIL"  SG_ 1034 HCU_PowertrainFault 5;
BA_ "GenMsgILSupport" BO_ 1046 1;
BA_ "GenMsgCycleTime" BO_ 1046 100;
BA_ "GenSigASIL"  SG_ 1046 HCU_PowerLimit 5;
BA_ "GenSigASIL"  SG_ 1046 HCU_GasPedalPosition 5;
BA_ "GenSigASIL"  SG_ 1046 HCU_GasPedalPositionInvalidData 5;
BA_ "GenSigASIL"  SG_ 1046 HCU_BrakePedalStsValidData 5;
BA_ "GenSigASIL"  SG_ 1046 HCU_BrakePedalSts 5;
BA_ "GenMsgILSupport" BO_ 1072 1;
BA_ "GenMsgCycleTime" BO_ 1072 20;
BA_ "GenSigASIL"  SG_ 1072 DisplayVehicleSpeed 5;
BA_ "GenSigASIL"  SG_ 1072 ECOModeSWSts 5;
BA_ "GenSigASIL"  SG_ 1072 ICM_1MessageCounter 5;
BA_ "GenSigASIL"  SG_ 1072 LDWLKA_LaneAssitTypeReq 5;
BA_ "GenSigASIL"  SG_ 1072 TotalOdometer_km 5;
BA_ "GenMsgILSupport" BO_ 1106 1;
BA_ "GenMsgCycleTime" BO_ 1106 100;
BA_ "GenSigASIL"  SG_ 1106 DISFail 5;
BA_ "GenSigASIL"  SG_ 1106 QDashACCFail 5;
BA_ "GenMsgILSupport" BO_ 1107 1;
BA_ "GenMsgCycleTime" BO_ 1107 500;
BA_ "GenSigASIL"  SG_ 1107 CurrentTimeHour 5;
BA_ "GenSigASIL"  SG_ 1107 CurrentTimeMinute 5;
BA_ "GenSigASIL"  SG_ 1107 CurrentTimeSecond 5;
BA_ "GenSigStartValue" SG_ 1107 CurrentTimeDay 1;
BA_ "GenSigASIL"  SG_ 1107 CurrentTimeDay 5;
BA_ "GenSigStartValue" SG_ 1107 CurrentTimeMonth 1;
BA_ "GenSigASIL"  SG_ 1107 CurrentTimeMonth 5;
BA_ "GenSigASIL"  SG_ 1107 CurrentTimeYear 5;
BA_ "GenMsgILSupport" BO_ 647 1;
BA_ "GenMsgCycleTime" BO_ 647 20;
BA_ "GenSigASIL"  SG_ 647 ICM_5_DriverSeatBeltSwitch 5;
BA_ "GenSigASIL"  SG_ 647 DriverSeatBeltSwitchQbit 5;
BA_ "GenSigASIL"  SG_ 647 ACC_Kilometre_Mile 5;
BA_ "GenSigASIL"  SG_ 647 ICM_5_MessageCounter 5;
BA_ "GenSigASIL"  SG_ 647 ICM_5_Checksum 5;
BA_ "GenMsgILSupport" BO_ 666 1;
BA_ "GenMsgCycleTime" BO_ 666 20;
BA_ "GenSigStartValue" SG_ 666 IPB_InputRodStroke 100;
BA_ "GenSigASIL"  SG_ 666 IPB_InputRodStroke 5;
BA_ "GenSigASIL"  SG_ 666 IPB_InputRodStrokeStatus 5;
BA_ "GenSigASIL"  SG_ 666 IPB_ESP_11_MessageCounter 5;
BA_ "GenSigASIL"  SG_ 666 IPB_ESP_11_CRC 5;
BA_ "GenMsgILSupport" BO_ 864 1;
BA_ "GenMsgSendType" BO_ 864 5;
BA_ "GenMsgDelayTime" BO_ 864 5;
BA_ "GenSigSendType" SG_ 864 CHKSM_MFS_2 2;
BA_ "GenSigASIL"  SG_ 864 CHKSM_MFS_2 5;
BA_ "GenSigSendType" SG_ 864 ALIVE_MFS_2 2;
BA_ "GenSigASIL"  SG_ 864 ALIVE_MFS_2 5;
BA_ "GenSigASIL"  SG_ 864 MFS_2_LeftRoller 5;
BA_ "GenSigSendType" SG_ 864 MFS_Cruise_Control 2;
BA_ "GenSigASIL"  SG_ 864 MFS_Cruise_Control 5;
BA_ "GenSigSendType" SG_ 864 MFS_Speed_limit 2;
BA_ "GenSigASIL"  SG_ 864 MFS_Speed_limit 5;
BA_ "GenSigSendType" SG_ 864 MFS_RESPlus 2;
BA_ "GenSigASIL"  SG_ 864 MFS_RESPlus 5;
BA_ "GenSigSendType" SG_ 864 MFS_SETMinus 2;
BA_ "GenSigASIL"  SG_ 864 MFS_SETMinus 5;
BA_ "GenSigASIL"  SG_ 864 MFS_2_LeRollrUpDwnAdjSteps 5;
BA_ "GenSigSendType" SG_ 864 MFS_Time_Gap_Add 2;
BA_ "GenSigASIL"  SG_ 864 MFS_Time_Gap_Add 5;
BA_ "GenSigSendType" SG_ 864 MFS_Time_Gap_Reduce 2;
BA_ "GenSigASIL"  SG_ 864 MFS_Time_Gap_Reduce 5;
BA_ "GenMsgILSupport" BO_ 196 1;
BA_ "GenMsgCycleTime" BO_ 196 10;
BA_ "GenSigStartValue" SG_ 196 SteeringAngle 65535;
BA_ "GenSigASIL"  SG_ 196 SteeringAngle 5;
BA_ "GenSigStartValue" SG_ 196 SteeringAngleSpeed 255;
BA_ "GenSigASIL"  SG_ 196 SteeringAngleSpeed 5;
BA_ "GenSigASIL"  SG_ 196 AngleFailure 5;
BA_ "GenSigStartValue" SG_ 196 SteeringAngleValidData 1;
BA_ "GenSigASIL"  SG_ 196 SteeringAngleValidData 5;
BA_ "GenSigStartValue" SG_ 196 SteeringAngleSpeedValidData 1;
BA_ "GenSigASIL"  SG_ 196 SteeringAngleSpeedValidData 5;
BA_ "GenSigASIL"  SG_ 196 SAM_1_G_MessageCounter 5;
BA_ "GenSigASIL"  SG_ 196 SAM_1_GCRCCheck 5;
BA_ "GenMsgILSupport" BO_ 768 1;
BA_ "GenMsgCycleTime" BO_ 768 10;
BA_ "GenSigStartValue" SG_ 768 GBPositoionDisplayForPEPS 15;
BA_ "GenSigASIL"  SG_ 768 GBPositoionDisplayForPEPS 5;
BA_ "GenSigASIL"  SG_ 768 DriverMode 5;
BA_ "GenSigASIL"  SG_ 768 TargetGearValidData 5;
BA_ "GenSigASIL"  SG_ 768 ShiftInProgress 5;
BA_ "GenSigStartValue" SG_ 768 TargetGear 15;
BA_ "GenSigASIL"  SG_ 768 TargetGear 5;
BA_ "GenSigASIL"  SG_ 768 TCU_2_MessageCounter 5;
BA_ "GenSigASIL"  SG_ 768 TCU_2_Checksum 5;
BA_ "GenMsgILSupport" BO_ 448 1;
BA_ "GenMsgCycleTime" BO_ 448 10;
BA_ "GenSigASIL"  SG_ 448 STAT_LimpHomeMode 5;
BA_ "GenSigASIL"  SG_ 448 ALIVE_TCU_4 5;
BA_ "GenSigASIL"  SG_ 448 CRC_TCU_4 5;
BA_ "GenMsgILSupport" BO_ 1335 1;
BA_ "GenMsgCycleTime" BO_ 1335 100;
BA_ "GenSigStartValue" SG_ 1335 NavSpeedLimitStatus 2;
BA_ "GenSigASIL"  SG_ 1335 NavSpeedLimitStatus 5;
BA_ "GenSigASIL"  SG_ 1335 NavSpeedLimit 5;
BA_ "GenSigASIL"  SG_ 1335 NavSpeedLimitUnits 5;
BA_ "GenSigASIL"  SG_ 1335 Reserved_NavCountryCode 5;
BA_ "GenSigASIL"  SG_ 1335 NavCurrRoadType 5;
BA_ "GenSigStartValue" SG_ 1335 IHU_DriveMode 6;
BA_ "GenSigASIL"  SG_ 1335 IHU_DriveMode 5;
BA_ "GenSigASIL"  SG_ 1335 SLASpdLimChgAudSwSet 5;
BA_ "GenMsgILSupport" BO_ 1276 1;
BA_ "GenMsgSendType" BO_ 1276 5;
BA_ "GenMsgCycleTimeFast" BO_ 1276 100;
BA_ "GenMsgNrOfRepetition" BO_ 1276 3;
BA_ "GenMsgDelayTime" BO_ 1276 5;
BA_ "GenSigSendType" SG_ 1276 IHU_11_AEBSwtSet 5;
BA_ "GenSigASIL"  SG_ 1276 IHU_11_AEBSwtSet 5;
BA_ "GenSigSendType" SG_ 1276 IHU_11_FCWSnvtySet 5;
BA_ "GenSigASIL"  SG_ 1276 IHU_11_FCWSnvtySet 5;
BA_ "GenSigSendType" SG_ 1276 IHU_11_FCWSwtSet 5;
BA_ "GenSigASIL"  SG_ 1276 IHU_11_FCWSwtSet 5;
BA_ "GenSigSendType" SG_ 1276 IHU_11_TJAICAExitTextInfoSwtSet 5;
BA_ "GenSigASIL"  SG_ 1276 IHU_11_TJAICAExitTextInfoSwtSet 5;
BA_ "GenSigSendType" SG_ 1276 IHU_11_SLASwtSet 5;
BA_ "GenSigASIL"  SG_ 1276 IHU_11_SLASwtSet 5;
BA_ "GenSigSendType" SG_ 1276 IHU_11_SCFSwtSet 5;
BA_ "GenSigASIL"  SG_ 1276 IHU_11_SCFSwtSet 5;
BA_ "GenSigSendType" SG_ 1276 IHU_11_DAISwtSet 5;
BA_ "GenSigASIL"  SG_ 1276 IHU_11_DAISwtSet 5;
BA_ "GenSigSendType" SG_ 1276 IHU_11_IESSwtSet 5;
BA_ "GenSigASIL"  SG_ 1276 IHU_11_IESSwtSet 5;
BA_ "GenSigSendType" SG_ 1276 IHU_11_HMASwtSet 5;
BA_ "GenSigASIL"  SG_ 1276 IHU_11_HMASwtSet 5;
BA_ "GenSigSendType" SG_ 1276 IHU_11_TSISwtSet 5;
BA_ "GenSigASIL"  SG_ 1276 IHU_11_TSISwtSet 5;
BA_ "GenSigSendType" SG_ 1276 IHU_11_TLISwtSet 5;
BA_ "GenSigASIL"  SG_ 1276 IHU_11_TLISwtSet 5;
BA_ "GenSigSendType" SG_ 1276 IHU_11_LDWSwtSet 5;
BA_ "GenSigASIL"  SG_ 1276 IHU_11_LDWSwtSet 5;
BA_ "GenSigSendType" SG_ 1276 IHU_11_WarnModSwtSet 5;
BA_ "GenSigASIL"  SG_ 1276 IHU_11_WarnModSwtSet 5;
BA_ "GenSigSendType" SG_ 1276 IHU_11_LDPSwtSet 5;
BA_ "GenSigASIL"  SG_ 1276 IHU_11_LDPSwtSet 5;
BA_ "GenSigSendType" SG_ 1276 IHU_11_LDWLDPSnvtySet 5;
BA_ "GenSigASIL"  SG_ 1276 IHU_11_LDWLDPSnvtySet 5;
BA_ "GenSigSendType" SG_ 1276 IHU_11_ELKSwtSet 5;
BA_ "GenSigASIL"  SG_ 1276 IHU_11_ELKSwtSet 5;
BA_ "GenMsgILSupport" BO_ 1330 1;
BA_ "GenMsgSendType" BO_ 1330 5;
BA_ "GenMsgCycleTimeFast" BO_ 1330 100;
BA_ "GenMsgNrOfRepetition" BO_ 1330 3;
BA_ "GenMsgDelayTime" BO_ 1330 5;
BA_ "GenSigSendType" SG_ 1330 SLWFONOFFSet 5;
BA_ "GenSigASIL"  SG_ 1330 SLWFONOFFSet 5;
BA_ "GenSigSendType" SG_ 1330 SLASpdlimitWarningAudSWSet 5;
BA_ "GenSigASIL"  SG_ 1330 SLASpdlimitWarningAudSWSet 5;
BA_ "GenSigSendType" SG_ 1330 IHU_29_SLAMode 5;
BA_ "GenSigASIL"  SG_ 1330 IHU_29_SLAMode 5;
BA_ "GenSigSendType" SG_ 1330 IHU_29_SpeedLmtNmberAb 5;
BA_ "GenSigASIL"  SG_ 1330 IHU_29_SpeedLmtNmberAb 5;
BA_ "GenSigSendType" SG_ 1330 IHU_29_SpeedLmtNmberE 5;
BA_ "GenSigASIL"  SG_ 1330 IHU_29_SpeedLmtNmberE 5;
BA_ "GenMsgILSupport" BO_ 1092 1;
BA_ "GenMsgCycleTime" BO_ 1092 100;
BA_ "GenSigASIL"  SG_ 1092 NavCountryCodeInfo 5;
BA_ "GenSigASIL"  SG_ 1092 NavSpeedLimit_ISA 5;
BA_ "GenSigASIL"  SG_ 1092 NavRainSpeedLimit 5;
BA_ "GenSigASIL"  SG_ 1092 NavSnowSpeedLimit 5;
BA_ "GenSigASIL"  SG_ 1092 NavFogSpeedLimit 5;
BA_ "GenSigASIL"  SG_ 1092 NavSpeedLimitType 5;
BA_ "GenSigASIL"  SG_ 1092 NavRampInfo 5;
BA_ "GenSigASIL"  SG_ 1092 NavRampDistance 5;
BA_ "GenSigASIL"  SG_ 1092 NavRoundabouts 5;
BA_ "GenSigASIL"  SG_ 1092 NavJunctions 5;
BA_ "GenSigASIL"  SG_ 1092 IHU_30_Reserved_2 5;
BA_ "GenMsgILSupport" BO_ 1120 1;
BA_ "GenMsgCycleTime" BO_ 1120 100;
BA_ "GenSigASIL"  SG_ 1120 NavWinding 5;
BA_ "GenSigASIL"  SG_ 1120 NavTrafficlights 5;
BA_ "GenSigASIL"  SG_ 1120 NavIsTimeSpeedLimit 5;
BA_ "GenSigASIL"  SG_ 1120 NavRoundaboutsDist 5;
BA_ "GenSigASIL"  SG_ 1120 NavInRoundabout 5;
BA_ "GenSigASIL"  SG_ 1120 NavSpeedLimitIsUnknown 5;
BA_ "GenSigASIL"  SG_ 1120 NavIsVariableSpeedLimit 5;
BA_ "GenSigASIL"  SG_ 1120 NavVSLExitEnterDist 5;
BA_ "GenSigASIL"  SG_ 1120 NavInRestzone 5;
BA_ "GenSigASIL"  SG_ 1120 AdasSignDistance 5;
BA_ "GenMsgILSupport" BO_ 1388 1;
BA_ "GenMsgCycleTime" BO_ 1388 1000;
BA_ "GenSigASIL"  SG_ 1388 IHU_34_GPSLongitudeinfo 5;
BA_ "GenSigASIL"  SG_ 1388 IHU_34_GPSHDOP 5;
BA_ "GenSigASIL"  SG_ 1388 IHU_34_GPSLongitudesign 5;
BA_ "GenSigASIL"  SG_ 1388 IHU_34_MsgCntr 5;
BA_ "GenSigASIL"  SG_ 1388 IHU_34_CRC 5;
BA_ "GenMsgILSupport" BO_ 1403 1;
BA_ "GenMsgCycleTime" BO_ 1403 1000;
BA_ "GenSigASIL"  SG_ 1403 IHU_35_GPSLatitudeinfo 5;
BA_ "GenSigASIL"  SG_ 1403 IHU_35_GPSnum 5;
BA_ "GenSigASIL"  SG_ 1403 IHU_35_GPSLatitudesign 5;
BA_ "GenSigASIL"  SG_ 1403 IHU_35_MsgCntr 5;
BA_ "GenSigASIL"  SG_ 1403 IHU_35_CRC 5;
BA_ "GenMsgILSupport" BO_ 1441 1;
BA_ "GenMsgSendType" BO_ 1441 5;
BA_ "GenMsgCycleTimeFast" BO_ 1441 100;
BA_ "GenMsgNrOfRepetition" BO_ 1441 3;
BA_ "GenMsgDelayTime" BO_ 1441 5;
BA_ "GenSigSendType" SG_ 1441 IHU_40_IDSSwtSet 5;
BA_ "GenSigASIL"  SG_ 1441 IHU_40_IDSSwtSet 5;
BA_ "GenSigSendType" SG_ 1441 IHU_40_WSOSSwtSet 5;
BA_ "GenSigASIL"  SG_ 1441 IHU_40_WSOSSwtSet 5;
BA_ "GenMsgILSupport" BO_ 62 1;
BA_ "GenMsgCycleTime" BO_ 62 10;
BA_ "GenSigASIL"  SG_ 62 VCU_2_CRC1 5;
BA_ "GenSigASIL"  SG_ 62 VCU_2_RollgCntr1 5;
BA_ "GenSigASIL"  SG_ 62 VCU_2_Resd1 5;
BA_ "GenSigStartValue" SG_ 62 VCU_MinActualWheelTorque 32768;
BA_ "GenSigASIL"  SG_ 62 VCU_MinActualWheelTorque 5;
BA_ "GenSigASIL"  SG_ 62 VCU_2_CRC2 5;
BA_ "GenSigASIL"  SG_ 62 VCU_2_RollgCntr2 5;
BA_ "GenSigASIL"  SG_ 62 VCU_2_Resd2 5;
BA_ "GenSigStartValue" SG_ 62 VCU_MaxActualWheelTorque 32768;
BA_ "GenSigASIL"  SG_ 62 VCU_MaxActualWheelTorque 5;
BA_ "GenSigASIL"  SG_ 62 VCU_2_CRC3 5;
BA_ "GenSigASIL"  SG_ 62 VCU_2_RollgCntr3 5;
BA_ "GenSigASIL"  SG_ 62 VCU_2_Resd3 5;
BA_ "GenSigASIL"  SG_ 62 VCU_GasPedalPositionInvalidData 5;
BA_ "GenSigASIL"  SG_ 62 VCU_DrivePedalOverride 5;
BA_ "GenSigASIL"  SG_ 62 VCU_DrivePedalOverride_Valid 5;
BA_ "GenSigASIL"  SG_ 62 VCU_GasPedalPosition 5;
BA_ "GenSigASIL"  SG_ 62 VCU_2_CRC4 5;
BA_ "GenSigASIL"  SG_ 62 VCU_2_RollgCntr4 5;
BA_ "GenSigASIL"  SG_ 62 VCU_PTReady 5;
BA_ "GenSigASIL"  SG_ 62 VCU_2_Resd4 5;
BA_ "GenSigASIL"  SG_ 62 VCU_TargetGear 5;
BA_ "GenSigASIL"  SG_ 62 VCU_ActualGear 5;
BA_ "GenSigASIL"  SG_ 62 VCU_TargetGearValidData 5;
BA_ "GenSigASIL"  SG_ 62 VCU_ActualGearValidData 5;
BA_ "GenSigASIL"  SG_ 62 VCU_BrakePedalStsValidData 5;
BA_ "GenSigASIL"  SG_ 62 VCU_BrakePedalSts 5;
BA_ "GenSigASIL"  SG_ 62 VCU_LimitSpeedSts 5;
BA_ "GenMsgILSupport" BO_ 1261 1;
BA_ "GenMsgCycleTime" BO_ 1261 100;
BA_ "GenSigASIL"  SG_ 1261 VCU_LowSOCCLMLimitSts 5;
BA_ "GenSigASIL"  SG_ 1261 VCU_VehicleSystemFailure 5;
BA_ "GenSigASIL"  SG_ 1261 VCU_6_MsgCounter 5;
BA_ "GenSigASIL"  SG_ 1261 VCU_6_CRC 5;
BA_ "GenMsgILSupport" BO_ 295 1;
BA_ "GenMsgCycleTime" BO_ 295 20;
BA_ "GenSigASIL"  SG_ 295 YAS_1_MessageCounter 5;
BA_ "GenSigStartValue" SG_ 295 YAS_CalibrationSts 1;
BA_ "GenSigASIL"  SG_ 295 YAS_CalibrationSts 5;
BA_ "GenSigStartValue" SG_ 295 YawrateSigValidData 3;
BA_ "GenSigASIL"  SG_ 295 YawrateSigValidData 5;
BA_ "GenSigStartValue" SG_ 295 LateralAccelerationSigValidData 3;
BA_ "GenSigASIL"  SG_ 295 LateralAccelerationSigValidData 5;
BA_ "GenSigASIL"  SG_ 295 LateralAcceleration 5;
BA_ "GenSigASIL"  SG_ 295 YawRate 5;
BA_ "GenSigASIL"  SG_ 295 YAS_1_Checksum 5;
BA_ "GenMsgILSupport" BO_ 296 1;
BA_ "GenMsgCycleTime" BO_ 296 20;
BA_ "GenSigASIL"  SG_ 296 YAS_2_MessageCounter 5;
BA_ "GenSigStartValue" SG_ 296 LongitudinalAccelerationSigValid 3;
BA_ "GenSigASIL"  SG_ 296 LongitudinalAccelerationSigValid 5;
BA_ "GenSigASIL"  SG_ 296 LongitudinalAcceleration 5;
BA_ "GenSigASIL"  SG_ 296 YAS_2_Checksum 5;
BA_ "GenMsgSendType" BO_ 1784 5;
BA_ "GenSigSendType" SG_ 1784 XCP_FCM_REQ 2;
BA_ "GenSigASIL"  SG_ 1784 XCP_FCM_REQ 5;
BA_ "GenMsgSendType" BO_ 1838 5;
BA_ "GenSigSendType" SG_ 1838 Diag_FCM_REQ 2;
BA_ "GenSigASIL"  SG_ 1838 Diag_FCM_REQ 5;
BA_ "DiagState" BO_ 2015 1;
BA_ "GenMsgSendType" BO_ 2015 5;
BA_ "GenSigSendType" SG_ 2015 Diag_Functional_REQ 2;
BA_ "GenSigASIL"  SG_ 2015 Diag_Functional_REQ 5;
VAL_ 969 RRCR_3_Ri2ObjBoxLen 511 "Invalid" ;
VAL_ 969 RRCR_3_Ri2ObjBoxWidth 511 "Invalid" ;
VAL_ 969 RRCR_3_Ri2HdTo 4095 "Invalid" ;
VAL_ 969 RRCR_3_Ri2ObjID 255 "Invalid" ;
VAL_ 969 RRCR_3_Ri2ObjCoordY 8191 "Invalid" ;
VAL_ 969 RRCR_3_Ri2ObjCoordX 8191 "Invalid" ;
VAL_ 969 RRCR_3_Ri2ObjXDirAV 255 "Invalid" ;
VAL_ 969 RRCR_3_Ri2ObjYDirV 16383 "Invalid" ;
VAL_ 969 RRCR_3_Ri2ObjXDirV 16383 "Invalid" ;
VAL_ 969 RRCR_3_Ri2ObjMtnChartc 3 " Moving" 2 " StatyFromMoving" 1 " Staty" 0 "  Invalid" ;
VAL_ 969 RRCR_3_Ri2ObjTyp 3 " Not Used" 2 " Two wheels vehicle " 1 " Four wheels vehicle " 0 "  Invalid" ;
VAL_ 969 RRCR_3_Ri2ObjConf 1 " Conf" 0 " Un conf" ;
VAL_ 969 RRCR_3_Ri2ObjNrOffocst 31 "Invalid" ;
VAL_ 969 RRCR_3_Ri2ObjTrackSt 3 " Coasted" 2 " New" 1 " Updated" 0 " Invalid" ;
VAL_ 969 RRCR_3_Ri2ObjCoordXDstStdDe 255 "Invalid" ;
VAL_ 969 RRCR_3_Ri2ObjCoordYDstStdDe 255 "Invalid" ;
VAL_ 969 RRCR_3_Ri2ObjXDirVStdDe 63 "Invalid" ;
VAL_ 969 RRCR_3_Ri2ObjYDirVStdDe 63 "Invalid" ;
VAL_ 976 RRCR_4_Ri3ObjBoxLen 511 "Invalid" ;
VAL_ 976 RRCR_4_Ri3ObjBoxWidth 511 "Invalid" ;
VAL_ 976 RRCR_4_Ri3HdTo 4095 "Invalid" ;
VAL_ 976 RRCR_4_Ri3ObjID 255 "Invalid" ;
VAL_ 976 RRCR_4_Ri3ObjCoordY 8191 "Invalid" ;
VAL_ 976 RRCR_4_Ri3ObjCoordX 8191 "Invalid" ;
VAL_ 976 RRCR_4_Ri3ObjXDirAV 255 "Invalid" ;
VAL_ 976 RRCR_4_Ri3ObjYDirV 16383 "Invalid" ;
VAL_ 976 RRCR_4_Ri3ObjXDirV 16383 "Invalid" ;
VAL_ 976 RRCR_4_Ri3ObjMtnChartc 3 " Moving" 2 " StatyFromMoving" 1 " Staty" 0 "  Invalid" ;
VAL_ 976 RRCR_4_Ri3ObjTyp 3 " Not Used" 2 " Two wheels vehicle " 1 " Four wheels vehicle " 0 "  Invalid" ;
VAL_ 976 RRCR_4_Ri3ObjConf 1 " Conf" 0 " Un conf" ;
VAL_ 976 RRCR_4_Ri3ObjNrOffocst 31 "Invalid" ;
VAL_ 976 RRCR_4_Ri3ObjTrackSt 3 " Coasted" 2 " New" 1 " Updated" 0 " Invalid" ;
VAL_ 976 RRCR_4_Ri3ObjCoordXDstStdDe 255 "Invalid" ;
VAL_ 976 RRCR_4_Ri3ObjCoordYDstStdDe 255 "Invalid" ;
VAL_ 976 RRCR_4_Ri3ObjXDirVStdDe 63 "Invalid" ;
VAL_ 976 RRCR_4_Ri3ObjYDirVStdDe 63 "Invalid" ;
VAL_ 984 RRCR_5_Ri4ObjBoxLen 511 "Invalid" ;
VAL_ 984 RRCR_5_Ri4ObjBoxWidth 511 "Invalid" ;
VAL_ 984 RRCR_5_Ri4HdTo 4095 "Invalid" ;
VAL_ 984 RRCR_5_Ri4ObjID 255 "Invalid" ;
VAL_ 984 RRCR_5_Ri4ObjCoordY 8191 "Invalid" ;
VAL_ 984 RRCR_5_Ri4ObjCoordX 8191 "Invalid" ;
VAL_ 984 RRCR_5_Ri4ObjXDirAV 255 "Invalid" ;
VAL_ 984 RRCR_5_Ri4ObjYDirV 16383 "Invalid" ;
VAL_ 984 RRCR_5_Ri4ObjXDirV 16383 "Invalid" ;
VAL_ 984 RRCR_5_Ri4ObjMtnChartc 3 " Moving" 2 " StatyFromMoving" 1 " Staty" 0 "  Invalid" ;
VAL_ 984 RRCR_5_Ri4ObjTyp 3 " Not Used" 2 " Two wheels vehicle " 1 " Four wheels vehicle " 0 "  Invalid" ;
VAL_ 984 RRCR_5_Ri4ObjConf 1 " Conf" 0 " Un conf" ;
VAL_ 984 RRCR_5_Ri4ObjNrOffocst 31 "Invalid" ;
VAL_ 984 RRCR_5_Ri4ObjTrackSt 3 " Coasted" 2 " New" 1 " Updated" 0 " Invalid" ;
VAL_ 984 RRCR_5_Ri4ObjCoordXDstStdDe 255 "Invalid" ;
VAL_ 984 RRCR_5_Ri4ObjCoordYDstStdDe 255 "Invalid" ;
VAL_ 984 RRCR_5_Ri4ObjXDirVStdDe 63 "Invalid" ;
VAL_ 984 RRCR_5_Ri4ObjYDirVStdDe 63 "Invalid" ;
VAL_ 986 RRCR_6_Ri5ObjBoxLen 511 "Invalid" ;
VAL_ 986 RRCR_6_Ri5ObjBoxWidth 511 "Invalid" ;
VAL_ 986 RRCR_6_Ri5HdTo 4095 "Invalid" ;
VAL_ 986 RRCR_6_Ri5ObjID 255 "Invalid" ;
VAL_ 986 RRCR_6_Ri5ObjCoordY 8191 "Invalid" ;
VAL_ 986 RRCR_6_Ri5ObjCoordX 8191 "Invalid" ;
VAL_ 986 RRCR_6_Ri5ObjXDirAV 255 "Invalid" ;
VAL_ 986 RRCR_6_Ri5ObjYDirV 16383 "Invalid" ;
VAL_ 986 RRCR_6_Ri5ObjXDirV 16383 "Invalid" ;
VAL_ 986 RRCR_6_Ri5ObjMtnChartc 3 " Moving" 2 " StatyFromMoving" 1 " Staty" 0 "  Invalid" ;
VAL_ 986 RRCR_6_Ri5ObjTyp 3 " Not Used" 2 " Two wheels vehicle " 1 " Four wheels vehicle " 0 "  Invalid" ;
VAL_ 986 RRCR_6_Ri5ObjConf 1 " Conf" 0 " Un conf" ;
VAL_ 986 RRCR_6_Ri5ObjNrOffocst 31 "Invalid" ;
VAL_ 986 RRCR_6_Ri5ObjTrackSt 3 " Coasted" 2 " New" 1 " Updated" 0 " Invalid" ;
VAL_ 986 RRCR_6_Ri5ObjCoordXDstStdDe 255 "Invalid" ;
VAL_ 986 RRCR_6_Ri5ObjCoordYDstStdDe 255 "Invalid" ;
VAL_ 986 RRCR_6_Ri5ObjXDirVStdDe 63 "Invalid" ;
VAL_ 986 RRCR_6_Ri5ObjYDirVStdDe 63 "Invalid" ;
VAL_ 994 RRCR_8_ObjVldFlg 1 " InValid" 0 " Valid" ;
VAL_ 994 RRCR_8_LgtDst 8191 "Invalid" ;
VAL_ 994 RRCR_8_LgtRelV 16383 "Invalid" ;
VAL_ 745 ABS_ESP_1_EBDFailSts 1 " Fail present (lamp on)" 0 " Not present" ;
VAL_ 745 ABS_ESP_1_ABSFailSts 1 " Fail present (lamp on)" 0 " Not present" ;
VAL_ 745 ABS_ESP_1_ABSActive 1 " Active" 0 " Not active" ;
VAL_ 745 ABS_ESP_1_VDCFailSts 1 " Fail present (lamp on)" 0 " Not present" ;
VAL_ 745 ABS_ESP_1_VDCActive 1 " Active" 0 " Not active" ;
VAL_ 745 ABS_ESP_1_TCSFailSts 1 " Fail present (lamp on)" 0 " Not present" ;
VAL_ 745 ABS_ESP_1_TCSActive 1 " Active" 0 " Not active" ;
VAL_ 745 ABS_ESP_1_PressureMasterCylinder 1023 "Invalid" ;
VAL_ 745 ESP1_PressureMasCylindValidData 1 " Not Valid" 0 " Valid" ;
VAL_ 745 ESP1_VehicleSpeedVSOSigValidData 1 " Not Valid" 0 " Valid" ;
VAL_ 745 ABS_ESP_1_VehicleSpeedVSOSig 8191 "Invalid" ;
VAL_ 745 ABS_ESP_1_HDCCtrlSts 3 " Not Used" 2 " active braking(lamp flash)" 1 " Not active braking(lamp on)" 0 " OFF" ;
VAL_ 745 ABS_ESP_1_HDCFailSts 1 " Fail present (lamp on)" 0 " Not present" ;
VAL_ 745 ABS_ESP_1_ESPSwitchStatus 1 " Disable" 0 " On" ;
VAL_ 745 SwitchOffCruiseControl 1 " Switch off cruise control" 0 " Not switch off cruise control                          " ;
VAL_ 787 NoBrakeForce 1 " No Brake Force" 0 " Exist Brake Force" ;
VAL_ 787 ABS_ESP_3_AVHFailSts 1 " Fail present (lamp on)" 0 " Not present" ;
VAL_ 787 ABS_ESP_3_AVHSts 3 " Not used" 2 " Active" 1 " Standby" 0 " Off" ;
VAL_ 790 VehicleStandstill 3 " Reserved" 2 " invalid" 1 " Standstill" 0 " Not standstill" ;
VAL_ 790 AWBactive 1 " Active" 0 " Not active" ;
VAL_ 790 AWBavailable 1 " Available" 0 " Not available" ;
VAL_ 790 ECDTempOff 0 " not high" 1 " temp too high" ;
VAL_ 790 DCFail 1 " Error" 0 " No error" ;
VAL_ 790 VLC_Active 1 " Active" 0 " Not active" ;
VAL_ 790 VLC_Available 1 " Available" 0 " Not available" ;
VAL_ 790 CDDActive 1 " Active" 0 " Not active" ;
VAL_ 790 CDDAvailable 1 " Available" 0 " Not available" ;
VAL_ 790 ABAactive 1 " Active" 0 " Not active" ;
VAL_ 790 ABAavailable 1 " Available" 0 " Not available" ;
VAL_ 608 LHFWheelDriveDirection 7 " reserved" 6 " reserved" 5 " reserved" 4 " Invalid" 3 " Stop" 2 " Backward" 1 " Forward" 0 " Init" ;
VAL_ 608 LHFWheelSpeedRawValidData 1 " Not Valid" 0 " Valid" ;
VAL_ 608 RHFWheelDriveDirection 7 " reserved" 6 " reserved" 5 " reserved" 4 " Invalid" 3 " Stop" 2 " Backward" 1 " Forward" 0 " Init" ;
VAL_ 608 RHFWheelSpeedRawValidData 1 " Not Valid" 0 " Valid" ;
VAL_ 608 QDCACC 3 " Not defined" 2 " Irreversible error" 1 " Reversible error" 0 " No error" ;
VAL_ 608 VLCFail 1 " Error" 0 " No error" ;
VAL_ 608 WheelBrakeForce 65535 "Invalid" ;
VAL_ 641 LHRWheelDriveDirection 7 " reserved" 6 " reserved" 5 " reserved" 4 " Invalid" 3 " Stop" 2 " Backward" 1 " Forward" 0 " Init" ;
VAL_ 641 LHRWheelSpeedRawValidData 1 " Not Valid" 0 " Valid" ;
VAL_ 641 RHRWheelDriveDirection 7 " reserved" 6 " reserved" 5 " reserved" 4 " Invalid" 3 " Stop" 2 " Backward" 1 " Forward" 0 " Init" ;
VAL_ 641 RHRWheelSpeedRawValidData 1 " Not Valid" 0 " Valid" ;
VAL_ 641 ABPActive 1 " Active" 0 " Not active" ;
VAL_ 641 ABPAvailable 1 " Available" 0 " Not available" ;
VAL_ 641 AEBdecActive 1 " Active" 0 " Not active" ;
VAL_ 641 AEBdecAvailable 1 " Available" 0 " Not available" ;
VAL_ 1282 CDPActive 0 " Not active" 1 " Active" ;
VAL_ 913 RHTurnlightSts 1 " Active" 0 " Off" ;
VAL_ 913 LHTurnlightSts 1 " Active" 0 " Off" ;
VAL_ 913 HighBeamSts 1 " Active" 0 " Off" ;
VAL_ 913 LowBeamSts 1 " Active" 0 " Off" ;
VAL_ 913 KeySts 3 " CRANK + ON" 2 " ON" 1 " ACC" 0 " OFF" ;
VAL_ 913 DirectionIndRight 1 " Active" 0 " Not active" ;
VAL_ 913 DirectionIndLeft 1 " Active" 0 " Not active" ;
VAL_ 913 HazardLightSW 1 " Active" 0 " Not active" ;
VAL_ 913 AutoLightSW 1 " Active" 0 " Not active" ;
VAL_ 913 FGHeat_Request_CommandFeedback 1 "Active" 0 "Not Active        " ;
VAL_ 913 DriverDoorLockSts 1 " Unlock" 0 " Lock" ;
VAL_ 913 DriverDoorSts 1 " Open" 0 " Close" ;
VAL_ 913 PsngrDoorSts 1 " Open" 0 " Close" ;
VAL_ 913 HoodSts 1 " Open" 0 " Close" ;
VAL_ 913 RHRDoorSts 1 " Open" 0 " Close" ;
VAL_ 913 LHRdoorSts 1 " Open" 0 " Close" ;
VAL_ 913 TrunkSts 1 " Open" 0 " Close" ;
VAL_ 913 DriverDoorStsQbit 1 " invalid" 0 " valid" ;
VAL_ 913 HMASW 1 " Active" 0 " Off" ;
VAL_ 913 RearFogLightSts 1 " Active" 0 " Off" ;
VAL_ 913 ReverseGearSts 1 " Active" 0 " Off" ;
VAL_ 913 FrontFogLightSts 1 " Active" 0 " Off" ;
VAL_ 913 HighBeamSWSts 1 " Active" 0 " Off" ;
VAL_ 913 FlashSWSts 1 " Active" 0 " Off" ;
VAL_ 913 LHTurnSW 1 " Active" 0 " Off" ;
VAL_ 913 RHTurnSW 1 " Active" 0 " Off" ;
VAL_ 913 WiperSts 3 " ContinuousFast" 2 " ContinuousSlow" 1 " Auto or Intermittent" 0 " OFF" ;
VAL_ 913 RainDetected 1 " True" 0 "False" ;
VAL_ 913 AutoHighSpeedRequest 1 " True" 0 "False" ;
VAL_ 1077 TrailerConnectSts 1 " Active" 0 " Not Active" ;
VAL_ 1333 CLM2_ExternalTempFailSts 1 " Fail Present" 0 " Fail Not Present" ;
VAL_ 1039 DMS_1_DMSSt 7 " Reserved" 6 " Reserved" 5 " Reserved" 4 " Faulty" 3 " Active " 2 " Standby" 1 " Off" 0 " Not Active" ;
VAL_ 1039 DMS_1_CameraSt 3 " Faulty" 2 " Blocked" 1 " Ok" 0 " Not Active" ;
VAL_ 1039 DMS_1_DriverSts 5 "Will distract" 4 "Unresonsive" 3 "Fatigue" 2 "Distract" 1 "Attention" 0 "Not Active" ;
VAL_ 250 EMS1_EngineSpeed 65535 "Invalid" ;
VAL_ 250 CruiseControlStatus 3 " Invalid" 2 " Standby" 1 " Active" 0 " Not Active" ;
VAL_ 250 AcceleratorPosRaw 255 "Invalid" ;
VAL_ 250 NeutralGearSts 1 " Neutral" 0 " Not in Neutral" ;
VAL_ 250 ECFail 1 " Failure" 0 " No Failure" ;
VAL_ 250 ECGPOvrd 1 " Driver Override" 0 " No Override" ;
VAL_ 257 BrakePedalStsValidDataForTCU 0 " Valid" 1 " Not Valid" ;
VAL_ 257 BrakePedalStsForTCU 0 " Not applied" 1 " applied" ;
VAL_ 257 EngineStsForDCT 7 " Invalid" 6 " Reserved" 5 " Reserved" 4 " Engine running in limp home mode" 3 " Engine running" 2 " Activation of starter powerstage" 1 " Stop" 0 " Init" ;
VAL_ 705 SSMStatus 7 "Invalid" 6 " Auto Stopping" 5 " Operation" 4 " Engine Restart" 3 " Starter Restart" 2 " Stopped" 1 " Standby" 0 " Reset/Not Implemented" ;
VAL_ 259 ECGPOvrd 1 " Driver Override" 0 " No Override" ;
VAL_ 259 ECGPOvrdInvalidData 1 " Invalid" 0 " Valid" ;
VAL_ 259 BrakePedalStsValidDataForTCU 0 " Valid" 1 " Not Valid" ;
VAL_ 259 BrakePedalStsForTCU 0 " Not applied" 1 " applied" ;
VAL_ 1057 LimitSpeedSts 5 " Kickdown" 4 " Cancel" 3 " Limit" 2 " Overspeed" 1 " Standby" 0 " Off" ;
VAL_ 1057 GasPedalPositionInvalidData 1 " Invalid" 0 " Valid" ;
VAL_ 1270 EPBErrorStatus 1 " Error" 0 " No Error" ;
VAL_ 1270 EPBStatus 7 " Not Used" 6 " Not Used" 5 " Error" 4 " Unknown / Initial" 3 " Applying" 2 " Releasing" 1 " Applied" 0 " Released" ;
VAL_ 1270 RWUActive 1 " Active" 0 " Not Active" ;
VAL_ 1285 EPSFailSts 1 " Fail present" 0 " Not present" ;
VAL_ 1285 EPSSteeringAngleCalibrationSts 1 " No calibration or no initialization" 0 " Calibration is fine" ;
VAL_ 1285 EPS_AssistanceStyle_Sts 3 " Reserved" 2 " Reserved" 1 " Light" 0 " Heavy" ;
VAL_ 916 TorsionBarTorqueDir 1 " negative" 0 " postive" ;
VAL_ 916 TosionBarTorqueValid 1 " Valid" 0 " Invalid" ;
VAL_ 916 EpsControlStatus 3 " control request not allowed(permanent)" 2 " control request not allowed(temporarily)" 1 " request honored" 0 " no request" ;
VAL_ 467 EPS_3_StrngWhlAg 16383 "Invalid" ;
VAL_ 467 EPS_3_StrngWhlAgValid 1 " Invalid" 0 " Valid" ;
VAL_ 467 EPS_3_StrngAgSpdValidData 1 " Not Valid" 0 " Valid" ;
VAL_ 467 EPS_3_StrngAgSpd 255 "Invalid" ;
VAL_ 467 EPS_3_AgFailr 1 " Failure" 0 " No Failure" ;
VAL_ 483 EPS_4_LoASts 1 " LoA fault" 0 " No LoA fault" ;
VAL_ 483 EPS_4_LatDrvgAvlForLvl 3 " Reserved" 2 " Available" 1 " FailureDetected" 0 " NotAvailable" ;
VAL_ 483 EPS_4_HptcVibSrvAvl 3 " Reserved" 2 " Available" 1 " FailureDetected" 0 " NotAvailable" ;
VAL_ 483 EPS_4_AgCtrlLimActvd 3 " RateLimReached" 2 " TqLimLowerReached" 1 " TqLimUpperReached" 0 " NotLimited" ;
VAL_ 483 EPS_4_PSCMActRPCTrqValid 1 " Invalid" 0 " Valid" ;
VAL_ 483 EPS_4_PSCMActRPCTrq 2047 "Invalid" ;
VAL_ 483 EPS_4_StrngWhlAgResActive 1 " Active" 0 " Not active" ;
VAL_ 483 EPS_4_ManMachineSharingSts 3 "reserved" 2 "Man-machine sharing is available" 1 "Man-machine sharing is not available" 0 "Not Active" ;
VAL_ 406 EPB_FltLvl 3 "Two caliper fault" 2 "One caliper fault-R" 1 "One caliper fault-L " 0 "No fault" ;
VAL_ 406 EPBStatus 7 " Not Used" 6 " Fault" 5 " ErrorApplied" 4 " Unknown / Initial" 3 " Applying" 2 " Releasing" 1 " Applied" 0 " Released" ;
VAL_ 263 HCU_6_MaxTorqueWheel 65535 "Invalid" ;
VAL_ 263 HCU_6_MinTorqueWheel 65535 "Invalid" ;
VAL_ 263 HCU_6_ECGPOvrd 1 " Driver Override" 0 " No Override" ;
VAL_ 263 HCU_6_ECGPOvrdInvalidData 1 " Invalid" 0 " Valid" ;
VAL_ 263 HCU_BrakePedalStsValidDataForTCU 0 " Valid" 1 " Not Valid" ;
VAL_ 263 HCU_6_BrakePedalStsForTCU 0 " Not applied" 1 " applied" ;
VAL_ 269 PRNDGearAct 7 "Reserved" 6 "Reserved" 5 "Reserved" 4 " D" 3 " N" 2 " R" 1 " P" 0 " Init" ;
VAL_ 269 PRNDGearActValidData 1 "Valid" 0 "Not Valid" ;
VAL_ 269 PRNDGearTarget 7 "Reserved" 6 "Reserved" 5 "Reserved" 4 "D" 3 "N" 2 "R" 1 "P" 0 " Init" ;
VAL_ 1034 HCU_PTReady 1 " LmpON" 0 " LmpOFF" ;
VAL_ 1034 HCU_PowertrainFault 1 " Fault" 0 " No Fault" ;
VAL_ 1046 HCU_PowerLimit 1 " On" 0 " Off" ;
VAL_ 1046 HCU_GasPedalPositionInvalidData 1 " Invalid" 0 " Valid" ;
VAL_ 1046 HCU_BrakePedalStsValidData 0 " Valid" 1 " Not Valid" ;
VAL_ 1046 HCU_BrakePedalSts 0 " Not applied" 1 " Applied" ;
VAL_ 1072 DisplayVehicleSpeed 8191 "Invalid" ;
VAL_ 1072 ECOModeSWSts 1 " Active" 0 " Not active" ;
VAL_ 1072 LDWLKA_LaneAssitTypeReq 3 " OFF" 2 " LKA" 1 " LDW" 0 " Default" ;
VAL_ 1072 TotalOdometer_km 1048575 "Invalid" ;
VAL_ 1106 DISFail 1 " error" 0 " no error" ;
VAL_ 1106 QDashACCFail 3 " not defined" 2 " irreversible error" 1 " reversible error" 0 " no error" ;
VAL_ 1107 CurrentTimeHour 0 "Invalid" ;
VAL_ 1107 CurrentTimeMinute 0 "Invalid" ;
VAL_ 1107 CurrentTimeSecond 0 "Invalid" ;
VAL_ 1107 CurrentTimeDay 0 "Invalid" ;
VAL_ 1107 CurrentTimeMonth 0 "Invalid" ;
VAL_ 1107 CurrentTimeYear 0 "Invalid" ;
VAL_ 647 ICM_5_DriverSeatBeltSwitch 1 " Unfasten" 0 " Fasten" ;
VAL_ 647 DriverSeatBeltSwitchQbit 1 " invalid" 0 " valid" ;
VAL_ 647 ACC_Kilometre_Mile 1 " mile" 0 " kilometer" ;
VAL_ 666 IPB_InputRodStrokeStatus 1 " Invalid" 0 " Valid " ;
VAL_ 864 MFS_2_LeftRoller 3 "invalid" 2 "ScrollDown" 1 "ScrollUp" 0 "Not action" ;
VAL_ 864 MFS_Cruise_Control 3 "invalid" 2 "Stuck" 1 "Pressed" 0 "Not action" ;
VAL_ 864 MFS_Speed_limit 3 "invalid" 2 "Stuck" 1 " Pressed" 0 "Not action" ;
VAL_ 864 MFS_RESPlus 3 "invalid" 2 "Stuck" 1 "Pressed" 0 "Not action" ;
VAL_ 864 MFS_SETMinus 3 "invalid" 2 " Stuck" 1 " Pressed" 0 " Not action" ;
VAL_ 864 MFS_Time_Gap_Add 3 "invalid" 2 "Stuck" 1 "Pressed" 0 "Not action" ;
VAL_ 864 MFS_Time_Gap_Reduce 3 "invalid" 2 "Stuck" 1 "Pressed" 0 "Not action" ;
VAL_ 196 SteeringAngle 65535 "Invalid" ;
VAL_ 196 SteeringAngleSpeed 255 "Invalid" ;
VAL_ 196 AngleFailure 1 " Failure" 0 " No Failure" ;
VAL_ 196 SteeringAngleValidData 1 " Not Valid" 0 " Valid" ;
VAL_ 196 SteeringAngleSpeedValidData 1 " Not Valid" 0 " Valid" ;
VAL_ 768 GBPositoionDisplayForPEPS 15 "Invalid/limp home" 14 "Park                                                      " 13 "Reverse                                                   " 12 "Neutral                                                   " 11 "Drive" 10 "Low                                                         " 9 "M 9th gear                                                    " 8 "M 8th gear                                    " 7 "M 7th gear                                                  " 6 "M 6th gear" 5 "M 5th gear" 4 "M 4th gear" 3 "M3rd gear" 2 "M2nd gear" 1 "M1st gear（Manual）" 0 "Reserved" ;
VAL_ 768 DriverMode 3 "Winter Mode" 2 "Econ Mode" 1 "Sport Mode" 0 "Normal Mode" ;
VAL_ 768 TargetGearValidData 1 " valid" 0 " Not Valid" ;
VAL_ 768 ShiftInProgress 1 "In progress" 0 "Not in progress" ;
VAL_ 768 TargetGear 15 "Invalid / limp home" 13 "Reserved " 14 "Reserved  " 12 "9th gear  " 11 "Park" 10 "Neutral" 9 "Reverse" 8 "8th gear" 7 "7thgear " 6 "6th gear" 5 "5th gear" 4 "4th gear" 3 "3rd gear" 2 "2nd gear" 1 "1st gear" 0 "Reserved" ;
VAL_ 448 STAT_LimpHomeMode 1 " Limphome mode" 0 " Not limphome mode" ;
VAL_ 1335 NavSpeedLimitStatus 3 " SL_PLURAL" 2 " SL_NOLIMIT" 1 " SL_EXISTS" 0 " SL_UNKNOWN" ;
VAL_ 1335 NavSpeedLimit 63 " Reserved" 62 " Reserved" 61 " Reserved" 60 " Reserved" 59 " Reserved" 58 " Reserved" 57 " Reserved" 56 " Reserved" 55 " Reserved" 54 " Reserved" 53 " Reserved" 52 " Reserved" 51 " Reserved" 50 " Reserved" 49 " Reserved" 48 " Reserved" 47 " Reserved" 46 " Reserved" 45 " Reserved" 44 " Reserved" 43 " Reserved" 42 " Reserved" 41 " Reserved" 40 " Reserved" 39 " Reserved" 38 " Reserved" 37 " Reserved" 36 " Reserved" 35 " Reserved" 34 " Reserved" 33 " Reserved" 32 " Reserved" 31 " Reserved" 30 " Reserved" 29 " Reserved" 28 " Reserved" 27 " Reserved" 26 " SPL 130" 25 " SPL 125" 24 " SPL 120" 23 " SPL 115" 22 " SPL 110" 21 " SPL 105" 20 " SPL 100" 19 " SPL 95" 18 " SPL 90" 17 " SPL 85" 16 " SPL 80" 15 " SPL 75" 14 " SPL 70" 13 " SPL 65" 12 " SPL 60" 11 " SPL 55" 10 " SPL 50" 9 " SPL 45" 8 " SPL 40" 7 " SPL 35" 6 " SPL 30" 5 " SPL 25" 4 " SPL 20" 3 " SPL 15" 2 " SPL 10" 1 " SPL 5" 0 " No Display" ;
VAL_ 1335 NavSpeedLimitUnits 3 " Reserved" 2 " KMH" 1 " MPH" 0 " Unknown" ;
VAL_ 1335 NavCurrRoadType 10 " Nonaviway" 9 " Commonway" 8 " Minorway" 7 " Mainway" 6 " Expressway" 5 " CountyandTownlway" 4 " Townway" 3 " Countylway" 2 " Provincialway" 1 " Nationalway" 0 " Highway" ;
VAL_ 1335 IHU_DriveMode 7 " SAND" 6 " Not display" 5 " Offroad" 4 " MUD" 3 " SNOW" 2 " SPORT" 1 " NORMAL" 0 " ECO" ;
VAL_ 1335 SLASpdLimChgAudSwSet 3 " Not Used" 2 " OFF" 1 " ON" 0 " Not Active" ;
VAL_ 1276 IHU_11_AEBSwtSet 3 " Not Used" 2 " OFF" 1 " ON" 0 " Not Active" ;
VAL_ 1276 IHU_11_FCWSnvtySet 3 " far" 2 " near" 1 " standard" 0 " Not Active" ;
VAL_ 1276 IHU_11_FCWSwtSet 3 " Not Used" 2 " OFF" 1 " ON" 0 " Not Active" ;
VAL_ 1276 IHU_11_TJAICAExitTextInfoSwtSet 3 " Not Used" 2 " OFF" 1 " ON" 0 " Not Active" ;
VAL_ 1276 IHU_11_SLASwtSet 3 " Not Used" 2 " OFF" 1 " ON" 0 " Not Active" ;
VAL_ 1276 IHU_11_SCFSwtSet 3 " Not Used" 2 " OFF" 1 " ON" 0 " Not Active" ;
VAL_ 1276 IHU_11_DAISwtSet 3 " Not Used" 2 " OFF" 1 " ON" 0 " Not Active" ;
VAL_ 1276 IHU_11_IESSwtSet 3 " Not Used" 2 " OFF" 1 " ON" 0 " Not Active" ;
VAL_ 1276 IHU_11_HMASwtSet 3 " Not Used" 2 " OFF" 1 " ON" 0 " Not Active" ;
VAL_ 1276 IHU_11_TSISwtSet 3 " Not Used" 2 " OFF" 1 " ON" 0 " Not Active" ;
VAL_ 1276 IHU_11_TLISwtSet 3 " Not Used" 2 " OFF" 1 " ON" 0 " Not Active" ;
VAL_ 1276 IHU_11_LDWSwtSet 3 " Not Used" 2 " OFF" 1 " ON" 0 " Not Active" ;
VAL_ 1276 IHU_11_WarnModSwtSet 3 " voice and shock" 2 " only shock " 1 " only voice" 0 " Not Active" ;
VAL_ 1276 IHU_11_LDPSwtSet 3 " Not Used" 2 " OFF" 1 " ON" 0 " Not Active" ;
VAL_ 1276 IHU_11_LDWLDPSnvtySet 3 " Not Used" 2 " HIGH" 1 " LOW" 0 " Not Active" ;
VAL_ 1276 IHU_11_ELKSwtSet 3 " Not Used" 2 " OFF" 1 " ON" 0 " Not Active" ;
VAL_ 1330 SLWFONOFFSet 3 " Not Used" 2 " OFF" 1 " ON" 0 " Not Active" ;
VAL_ 1330 SLASpdlimitWarningAudSWSet 3 " Not Used" 2 " OFF" 1 " ON" 0 " Not Active" ;
VAL_ 1330 IHU_29_SLAMode 3 " Reserved" 2 " Relative" 1 " Absolute" 0 " Not active" ;
VAL_ 1330 IHU_29_SpeedLmtNmberAb 63 "reserved" 62 "reserved" 61 "reserved" 60 "reserved" 59 "reserved" 58 "reserved" 57 "reserved" 56 "reserved" 55 "reserved" 54 "reserved" 53 "reserved" 52 "reserved" 51 "reserved" 50 "reserved" 49 "reserved" 48 "reserved" 47 "reserved" 46 "reserved" 45 "reserved" 44 "reserved" 43 "reserved" 42 "reserved" 41 "reserved" 40 "reserved" 39 "reserved" 38 "reserved" 37 "reserved" 36 "reserved" 35 "reserved" 34 "reserved" 33 "reserved" 32 "reserved" 31 "reserved" 30 "reserved" 29 "reserved" 28 "reserved" 27 "reserved" 26 "reserved" 25 "reserved" 24 "reserved" 23 "reserved" 22 "reserved" 21 "10" 20 "9" 19 "8" 18 "7" 17 "6" 16 "5" 15 "4" 14 "3" 13 "2" 12 "1" 11 "0" 10 "-1" 9 "-2" 8 "-3" 7 "-4" 6 "-5" 5 "-6" 4 "-7" 3 "-8" 2 "-9" 1 "-10" 0 "No display" ;
VAL_ 1330 IHU_29_SpeedLmtNmberE 63 " reserved" 62 " reserved" 61 " reserved" 60 " reserved" 59 " reserved" 58 " reserved" 41 "20%" 40 "19%" 39 "18%" 38 "17%" 37 "16%" 36 "15%" 35 "14%" 34 "13%" 33 "12%" 32 "11%" 31 "10%" 30 "9%" 29 "8%" 28 "7%" 27 "6%" 26 "5%" 25 "4%" 24 "3%" 23 "2%" 22 "1%" 21 "0%" 20 "-1%" 19 "-2%" 18 "-3%" 17 "-4%" 16 "-5%" 15 "-6%" 14 "-7%" 13 "-8%" 12 "-9%" 11 "-10% " 10 "-11%" 9 "-12%" 8 "-13%" 7 "-14%" 6 "-15%" 5 "-16%" 4 "-17%" 3 "-18%" 2 "-19%" 1 "-20%" 0 "No display" ;
VAL_ 1092 NavCountryCodeInfo 127 "Reserve" 126 "Reserve" 125 "Reserve" 124 "Reserve" 123 "Reserve" 122 "Reserve" 121 "Reserve" 120 "Reserve" 119 "Reserve" 118 "Reserve" 117 "Reserve" 116 "Reserve" 115 "Reserve" 114 "Reserve" 113 "Reserve" 112 "Reserve" 111 "Reserve" 110 "Reserve" 109 "Reserve" 108 "Reserve" 107 "Reserve" 106 "Reserve" 105 "Reserve" 104 "Reserve" 103 "Reserve" 102 "Reserve" 101 "Reserve" 100 "Reserve" 99 "Reserve" 98 "Reserve" 97 "Reserve" 96 "Reserve" 95 "Reserve" 94 "Reserve" 93 "Reserve" 92 "Reserve" 91 "Reserve" 90 "Reserve" 89 "Reserve" 88 "Reserve" 87 "Reserve" 86 "Reserve" 85 "Reserve" 84 "Reserve" 83 "Reserve" 82 "Reserve" 81 "Reserve" 80 "Reserve" 79 "Reserve" 78 "Reserve" 77 "Reserve" 76 "Reserve" 75 "Reserve" 74 "Reserve" 73 "Reserve" 72 "Reserve" 71 "Reserve" 70 "Reserve" 69 "Reserve" 68 "Reserve" 67 "Reserve" 66 "Reserve" 65 "Reserve" 64 "Reserve" 63 "Reserve" 62 "Reserve" 61 "Reserve" 60 "Reserve" 59 "Reserve" 58 "Reserve" 57 "Reserve" 56 "Reserve" 55 "Reserve" 54 "Reserve" 53 "Reserve" 52 "Reserve" 51 "Reserve" 50 "Reserve" 49 "Reserve" 48 "Reserve" 47 "Reserve" 46 "Reserve" 45 "CHN 中国" 44 "MYS 马来西亚" 43 "NZL 新西兰" 42 "AUS 澳大利亚" 41 "KOS 科索沃" 40 "ALB 阿尔巴尼亚" 39 "MNE 黑山" 38 "MKD 北马其顿" 37 "BIH 波黑" 36 "SRB 塞尔维亚" 35 "ISR 以色列" 34 "TUR 土耳其" 33 "CHE 瑞士" 32 "NOR 挪威" 31 " AUT 奥地利" 30 "SWE 瑞典" 29 "SVN 斯洛文尼亚" 28 "SVK 斯洛伐克" 27 "ROU 罗马尼亚" 26 "PRT 葡萄牙" 25 "POL 波兰" 24 "NLD 荷兰" 23 "MLT 马耳他" 22 "LVA 拉脱维亚" 21 "LUX 卢森堡" 20 "LTU 立陶宛" 19 "ITA 意大利" 18 "IRL 爱尔兰" 17 "IMN 马恩岛" 16 "HUN 匈牙利" 15 "HRV 克罗地亚" 14 "GIB 直布罗陀" 13 "GRC 希腊" 12 "GBR 英国" 11 "FRO 法罗群岛" 10 "FRA 法国" 9 "FIN 芬兰" 8 "EST 爱沙尼亚" 7 "ESP 西班牙" 6 "DNK 丹麦" 5 "DEU 德国" 4 "CZE 捷克共和国" 3 "CYP 塞浦路斯" 2 "BGR 保加利亚" 1 "BEL 比利时" 0 "None" ;
VAL_ 1092 NavSpeedLimit_ISA 47 "Invalid" 34 "180" 33 "160" 32 "150" 31 "145" 30 "130" 29 "120" 28 "113" 27 "110" 26 "100" 25 "97" 24 "90" 23 "80" 22 "72" 21 "70" 20 "65" 19 "64" 18 "60" 17 "56" 16 "55" 15 "50" 14 "48" 13 "45" 12 "40" 11 "35" 10 "32" 9 "30" 8 "25" 7 "24" 6 "20" 5 "16" 4 "15" 3 "10" 2 "8" 1 "5" 0 "not display" ;
VAL_ 1092 NavRainSpeedLimit 127 "Invalid" ;
VAL_ 1092 NavSnowSpeedLimit 127 "Invalid" ;
VAL_ 1092 NavFogSpeedLimit 127 "Invalid" ;
VAL_ 1092 NavSpeedLimitType 3 " Reserved" 2 "Recessive" 1 "dominance" 0 "unknown" ;
VAL_ 1092 NavRampInfo 3 "Reserved" 2 "About to leave" 1 "exists" 0 "unknown" ;
VAL_ 1092 NavRampDistance 1023 "Invalid" ;
VAL_ 1092 NavRoundabouts 127 "Invalid" ;
VAL_ 1092 NavJunctions 127 "Invalid" ;
VAL_ 1120 NavWinding 511 "Invalid" ;
VAL_ 1120 NavTrafficlights 127 "Invalid" ;
VAL_ 1120 NavIsTimeSpeedLimit 3 "reserved" 2 "in time range" 1 "not effect" 0 "Not Active" ;
VAL_ 1120 NavInRoundabout 1 "in roundabout" 0 "Not Active" ;
VAL_ 1120 NavSpeedLimitIsUnknown 3 "reserved" 2 "limit exist" 1 "no limit data" 0 "Not Active" ;
VAL_ 1120 NavIsVariableSpeedLimit 1 "variable" 0 "Not Active" ;
VAL_ 1120 NavInRestzone 1 "restzone" 0 "Not Active" ;
VAL_ 1120 AdasSignDistance 127 "Invalid" ;
VAL_ 1388 IHU_34_GPSLongitudeinfo 268435455 "Invalid" ;
VAL_ 1388 IHU_34_GPSHDOP 1023 "Invalid" ;
VAL_ 1388 IHU_34_GPSLongitudesign 1 "West Longitude" 0 "East Longitude" ;
VAL_ 1403 IHU_35_GPSLatitudeinfo 134217727 "Invalid" ;
VAL_ 1403 IHU_35_GPSnum 255 "Invalid" ;
VAL_ 1403 IHU_35_GPSLatitudesign 1 "South Latitude" 0 "North Latitude" ;
VAL_ 1441 IHU_40_IDSSwtSet 3 "Not Used" 2 "OFF" 1 "ON" 0 "Not Active" ;
VAL_ 1441 IHU_40_WSOSSwtSet 3 "Not Used" 2 "OFF" 1 "ON" 0 "Not Active" ;
VAL_ 62 VCU_GasPedalPositionInvalidData 1 " Invalid" 0 " Valid" ;
VAL_ 62 VCU_DrivePedalOverride 1 " Driver Override" 0 " No Override" ;
VAL_ 62 VCU_DrivePedalOverride_Valid 1 " Available" 0 "Not available" ;
VAL_ 62 VCU_PTReady 1 " LmpON" 0 " LmpOFF" ;
VAL_ 62 VCU_TargetGear 7 " Invalid" 6 " Reserved" 5 " Reserved" 4 " Target gear D" 3 " Target gear N" 2 " Target gear R" 1 " Target gear P" 0 " No Request" ;
VAL_ 62 VCU_ActualGear 7 " Reserved" 6 " Reserved" 5 " Reserved" 4 " D" 3 " N" 2 " R" 1 " P" 0 " Init" ;
VAL_ 62 VCU_TargetGearValidData 1 "V alid" 0 "Not Valid" ;
VAL_ 62 VCU_ActualGearValidData 1 "Valid" 0 "Not Valid" ;
VAL_ 62 VCU_BrakePedalStsValidData 0 " Valid" 1 " Not Valid" ;
VAL_ 62 VCU_BrakePedalSts 0 " Not applied" 1 " Applied" ;
VAL_ 62 VCU_LimitSpeedSts 5 " Kickdown" 4 " Cancel" 3 " Limit" 2 " Overspeed" 1 " Standby" 0 " Off" ;
VAL_ 1261 VCU_LowSOCCLMLimitSts 1 " LmpON" 0 " LmpOFF" ;
VAL_ 1261 VCU_VehicleSystemFailure 1 " Fail present" 0 " Fail not present" ;
VAL_ 295 YAS_CalibrationSts 1 " Sensor  Calibrated" 0 " Sensor  Not Calibrated" ;
VAL_ 295 YawrateSigValidData 3 " Initialize" 2 " Invalid" 1 " Reserved" 0 " Valid" ;
VAL_ 295 LateralAccelerationSigValidData 3 " Initialize" 2 " Invalid" 1 " Reserved" 0 " Valid" ;
VAL_ 295 LateralAcceleration 65535 "Invalid" ;
VAL_ 295 YawRate 65535 "Invalid" ;
VAL_ 296 LongitudinalAccelerationSigValid 3 " Initialize" 2 " Invalid" 1 " Reserved" 0 " Valid" ;
VAL_ 296 LongitudinalAcceleration 65535 "Invalid" ;
